AUTOSAR XML (schema 00048)
package /ComponentTypes
  swc implementation Common_Normal_Implementation: behavior=Common_Normal_InternalBehavior
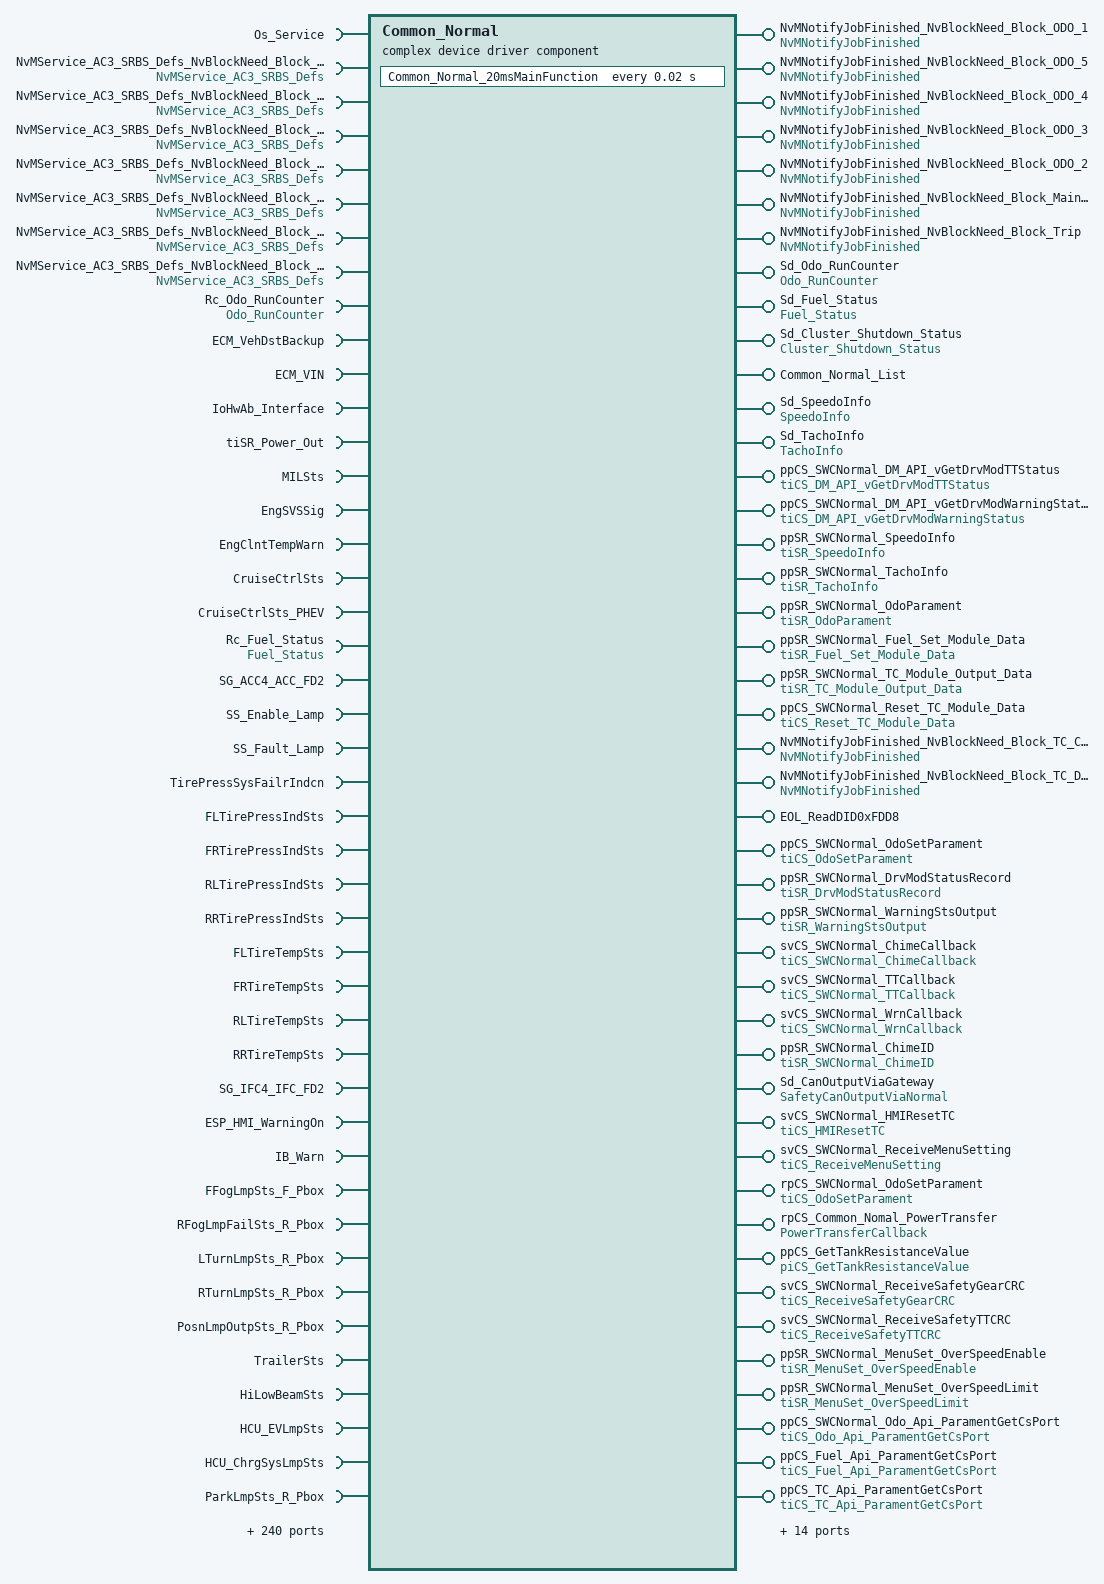
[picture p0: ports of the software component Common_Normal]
  complex device driver sw component type Common_Normal
    require port Os_Service: required-com-specs=[GetElapsedValue, GetCounterValue], required-interface=Os_Service
    require port NvMService_AC3_SRBS_Defs_NvBlockNeed_Block_ODO_1: required-com-specs=[WriteBlock, SetRamBlockStatus, RestoreBlockDefaults, ReadBlock, InvalidateNvBlock, GetErrorStatus, EraseBlock], required-interface=NvMService_AC3_SRBS_Defs
    provide port NvMNotifyJobFinished_NvBlockNeed_Block_ODO_1: server-com-spec{operation=JobFinished, queue-length=1}, provided-interface=NvMNotifyJobFinished
    provide port NvMNotifyJobFinished_NvBlockNeed_Block_ODO_5: server-com-spec{operation=JobFinished, queue-length=1}, provided-interface=NvMNotifyJobFinished
    require port NvMService_AC3_SRBS_Defs_NvBlockNeed_Block_ODO_5: required-com-specs=[WriteBlock, SetRamBlockStatus, RestoreBlockDefaults, ReadBlock, InvalidateNvBlock, GetErrorStatus, EraseBlock], required-interface=NvMService_AC3_SRBS_Defs
    provide port NvMNotifyJobFinished_NvBlockNeed_Block_ODO_4: server-com-spec{operation=JobFinished, queue-length=1}, provided-interface=NvMNotifyJobFinished
    require port NvMService_AC3_SRBS_Defs_NvBlockNeed_Block_ODO_4: required-com-specs=[WriteBlock, SetRamBlockStatus, RestoreBlockDefaults, ReadBlock, InvalidateNvBlock, GetErrorStatus, EraseBlock], required-interface=NvMService_AC3_SRBS_Defs
    provide port NvMNotifyJobFinished_NvBlockNeed_Block_ODO_3: server-com-spec{operation=JobFinished, queue-length=1}, provided-interface=NvMNotifyJobFinished
    require port NvMService_AC3_SRBS_Defs_NvBlockNeed_Block_ODO_3: required-com-specs=[WriteBlock, SetRamBlockStatus, RestoreBlockDefaults, ReadBlock, InvalidateNvBlock, GetErrorStatus, EraseBlock], required-interface=NvMService_AC3_SRBS_Defs
    provide port NvMNotifyJobFinished_NvBlockNeed_Block_ODO_2: server-com-spec{operation=JobFinished, queue-length=1}, provided-interface=NvMNotifyJobFinished
    require port NvMService_AC3_SRBS_Defs_NvBlockNeed_Block_ODO_2: required-com-specs=[WriteBlock, SetRamBlockStatus, RestoreBlockDefaults, ReadBlock, InvalidateNvBlock, GetErrorStatus, EraseBlock], required-interface=NvMService_AC3_SRBS_Defs
    provide port NvMNotifyJobFinished_NvBlockNeed_Block_MaintainOdo: server-com-spec{operation=JobFinished, queue-length=1}, provided-interface=NvMNotifyJobFinished
    require port NvMService_AC3_SRBS_Defs_NvBlockNeed_Block_MaintainOdo: required-com-specs=[WriteBlock, SetRamBlockStatus, RestoreBlockDefaults, ReadBlock, InvalidateNvBlock, GetErrorStatus, EraseBlock], required-interface=NvMService_AC3_SRBS_Defs
    provide port NvMNotifyJobFinished_NvBlockNeed_Block_Trip: server-com-spec{operation=JobFinished, queue-length=1}, provided-interface=NvMNotifyJobFinished
    require port NvMService_AC3_SRBS_Defs_NvBlockNeed_Block_Trip: required-com-specs=[WriteBlock, SetRamBlockStatus, RestoreBlockDefaults, ReadBlock, InvalidateNvBlock, GetErrorStatus, EraseBlock], required-interface=NvMService_AC3_SRBS_Defs
    provide port Sd_Odo_RunCounter: nonqueued-sender-com-spec{data-element=RunCounter, init-value=0}, provided-interface=Odo_RunCounter
    10 x require port:
      Rc_Odo_RunCounter: nonqueued-receiver-com-spec{data-element=RunCounter, filter=data-filter-type=ALWAYS, init-value=0}, required-interface=Odo_RunCounter
      ECM_VehDstBackup: nonqueued-receiver-com-spec{data-element=ECM_VehDstBackup, alive-timeout=10, enable-update=true, filter=data-filter-type=ALWAYS, handle-never-received=true, init-value=0}, required-interface=ECM_VehDstBackup
      ECM_VIN: nonqueued-receiver-com-spec{data-element=ECM19_0x3B5, alive-timeout=1.2, enable-update=true, filter=data-filter-type=ALWAYS, handle-never-received=true, init-value=8 x 0}, required-interface=ECM_VIN
      IoHwAb_Interface: required-com-specs=[SetHsLsOutput, SetPeriodAndDuty, SetDuty, SetPin, GetPin, GetVoltage], required-interface=IoHwAb_Interface
      tiSR_Power_Out: nonqueued-receiver-com-spec{data-element=SystemStateOut, alive-timeout=1, filter=data-filter-type=ALWAYS, handle-never-received=true, init-value=constant-reference=PowerOutInit}, required-interface=tiSR_Power_Out
      MILSts: nonqueued-receiver-com-spec{data-element=MILSts, alive-timeout=0.2, enable-update=true, filter=data-filter-type=ALWAYS, handle-never-received=true, init-value=0}, required-interface=MILSts
      EngSVSSig: nonqueued-receiver-com-spec{data-element=EngSVSSig, alive-timeout=0.2, enable-update=true, filter=data-filter-type=ALWAYS, handle-never-received=true, init-value=0}, required-interface=EngSVSSig
      EngClntTempWarn: nonqueued-receiver-com-spec{data-element=EngClntTempWarn, alive-timeout=1, enable-update=true, filter=data-filter-type=ALWAYS, handle-never-received=true, init-value=0}, required-interface=EngClntTempWarn
      CruiseCtrlSts: nonqueued-receiver-com-spec{data-element=CruiseCtrlSts, alive-timeout=0.2, enable-update=true, filter=data-filter-type=ALWAYS, handle-never-received=true, init-value=0}, required-interface=CruiseCtrlSts
      CruiseCtrlSts_PHEV: nonqueued-receiver-com-spec{data-element=CruiseCtrlSts_PHEV, alive-timeout=0.2, enable-update=true, filter=data-filter-type=ALWAYS, handle-never-received=true, init-value=0}, required-interface=CruiseCtrlSts_PHEV
    provide port Sd_Fuel_Status: nonqueued-sender-com-spec{data-element=Fuel_Status, init-value=0}, provided-interface=Fuel_Status
    38 x require port:
      Rc_Fuel_Status: nonqueued-receiver-com-spec{data-element=Fuel_Status, alive-timeout=1, enable-update=true, filter=data-filter-type=ALWAYS, handle-never-received=true, init-value=0}, required-interface=Fuel_Status
      SG_ACC4_ACC_FD2: nonqueued-receiver-com-spec{data-element=SG_ACC4_ACC_FD2, uses-end-to-end-protection=true, alive-timeout=1, enable-update=true, handle-never-received=true, init-value=fields=[ACC_FctSts:0, ACC_InterSysInfoDisp:0, ACC_ModDisp:0, ACC_ObjDetecte:0, ACC_SpdSetValue:0, ACC_TakeOverReq:0, ACC_TgtObjBarDisp:0, ACC_TimeGapSet:0, Checksum_ACC4:0, ISL_InterSysInfoDisp:0, RollingCounter_ACC4:0, TJA_ACC_SelSts:0, TJA_ICA_InterSysInfoDisp:0, TJA_ICA_ModDisp:0, CruCha_ModDisp:0, CruChar_InterSysInfoDisp:0, Longctrl_HazActv:0, dummy_ACC_FD2_8:0, dummy_ACC_FD2_9:0, dummy_ACC_FD2_10:0]}, required-interface=SG_ACC4_ACC_FD2
      SS_Enable_Lamp: nonqueued-receiver-com-spec{data-element=SS_Enable_Lamp, alive-timeout=1, enable-update=true, filter=data-filter-type=ALWAYS, handle-never-received=true, init-value=0}, required-interface=SS_Enable_Lamp
      SS_Fault_Lamp: nonqueued-receiver-com-spec{data-element=SS_Fault_Lamp, alive-timeout=1, enable-update=true, filter=data-filter-type=ALWAYS, handle-never-received=true, init-value=0}, required-interface=SS_Fault_Lamp
      TirePressSysFailrIndcn: nonqueued-receiver-com-spec{data-element=TirePressSysFailrIndcn, alive-timeout=5, enable-update=true, filter=data-filter-type=ALWAYS, handle-never-received=true, init-value=0}, required-interface=TirePressSysFailrIndcn
      FLTirePressIndSts: nonqueued-receiver-com-spec{data-element=FLTirePressIndSts, alive-timeout=5, enable-update=true, filter=data-filter-type=ALWAYS, handle-never-received=true, init-value=0}, required-interface=FLTirePressIndSts
      FRTirePressIndSts: nonqueued-receiver-com-spec{data-element=FRTirePressIndSts, alive-timeout=5, enable-update=true, filter=data-filter-type=ALWAYS, handle-never-received=true, init-value=0}, required-interface=FRTirePressIndSts
      RLTirePressIndSts: nonqueued-receiver-com-spec{data-element=RLTirePressIndSts, alive-timeout=5, enable-update=true, filter=data-filter-type=ALWAYS, handle-never-received=true, init-value=0}, required-interface=RLTirePressIndSts
      RRTirePressIndSts: nonqueued-receiver-com-spec{data-element=RRTirePressIndSts, alive-timeout=5, enable-update=true, filter=data-filter-type=ALWAYS, handle-never-received=true, init-value=0}, required-interface=RRTirePressIndSts
      FLTireTempSts: nonqueued-receiver-com-spec{data-element=FLTireTempSts, alive-timeout=5, enable-update=true, filter=data-filter-type=ALWAYS, handle-never-received=true, init-value=0}, required-interface=FLTireTempSts
      FRTireTempSts: nonqueued-receiver-com-spec{data-element=FRTireTempSts, alive-timeout=5, enable-update=true, filter=data-filter-type=ALWAYS, handle-never-received=true, init-value=0}, required-interface=FRTireTempSts
      RLTireTempSts: nonqueued-receiver-com-spec{data-element=RLTireTempSts, alive-timeout=5, enable-update=true, filter=data-filter-type=ALWAYS, handle-never-received=true, init-value=0}, required-interface=RLTireTempSts
      RRTireTempSts: nonqueued-receiver-com-spec{data-element=RRTireTempSts, alive-timeout=5, enable-update=true, filter=data-filter-type=ALWAYS, handle-never-received=true, init-value=0}, required-interface=RRTireTempSts
      SG_IFC4_IFC_FD2: nonqueued-receiver-com-spec{data-element=SG_IFC4_IFC_FD2, uses-end-to-end-protection=true, alive-timeout=0.5, enable-update=true, handle-never-received=true, init-value=fields=[CameraBlockageSts:0, Checksum_IFC4:0, ELKMainState:0, IFC_Handsoffwarn:0, IFCCalibrationSts:0, LaneAvailability:0, LDW_LKAWarn:0, LSSErrSts:0, LSSFuncSts:0, LSSIntervention:0, RollingCounter_IFC4:0, TJA_FollowSts:0, AESintervention:0, ESSintervention:0, dummy_IFC_FD2_13:0, dummy_IFC_FD2_14:0, dummy_IFC_FD2_15:0, ELKActSts:0, IntelligentEvaActSts:0, LCKStsIndcr:0]}, required-interface=SG_IFC4_IFC_FD2
      ESP_HMI_WarningOn: nonqueued-receiver-com-spec{data-element=ESP_HMI_WarningOn, alive-timeout=0.1, enable-update=true, filter=data-filter-type=ALWAYS, handle-never-received=true, init-value=0}, required-interface=ESP_HMI_WarningOn
      IB_Warn: nonqueued-receiver-com-spec{data-element=IB_Warn, alive-timeout=0.2, enable-update=true, filter=data-filter-type=ALWAYS, handle-never-received=true, init-value=0}, required-interface=IB_Warn
      FFogLmpSts_F_Pbox: nonqueued-receiver-com-spec{data-element=FFogLmpSts_F_Pbox, alive-timeout=0.5, enable-update=true, filter=data-filter-type=ALWAYS, handle-never-received=true, init-value=0}, required-interface=FFogLmpSts_F_Pbox
      RFogLmpFailSts_R_Pbox: nonqueued-receiver-com-spec{data-element=RFogLmpFailSts_R_Pbox, alive-timeout=0.5, enable-update=true, filter=data-filter-type=ALWAYS, handle-never-received=true, init-value=0}, required-interface=RFogLmpFailSts_R_Pbox
      LTurnLmpSts_R_Pbox: nonqueued-receiver-com-spec{data-element=LTurnLmpSts_R_Pbox, alive-timeout=0.5, enable-update=true, filter=data-filter-type=ALWAYS, handle-never-received=true, init-value=0}, required-interface=LTurnLmpSts_R_Pbox
      RTurnLmpSts_R_Pbox: nonqueued-receiver-com-spec{data-element=RTurnLmpSts_R_Pbox, alive-timeout=0.5, enable-update=true, filter=data-filter-type=ALWAYS, handle-never-received=true, init-value=0}, required-interface=RTurnLmpSts_R_Pbox
      PosnLmpOutpSts_R_Pbox: nonqueued-receiver-com-spec{data-element=PosnLmpOutpSts_R_Pbox, alive-timeout=0.5, enable-update=true, filter=data-filter-type=ALWAYS, handle-never-received=true, init-value=0}, required-interface=PosnLmpOutpSts_R_Pbox
      TrailerSts: nonqueued-receiver-com-spec{data-element=TrailerSts, alive-timeout=0.5, enable-update=true, filter=data-filter-type=ALWAYS, handle-never-received=true, init-value=0}, required-interface=TrailerSts
      HiLowBeamSts: nonqueued-receiver-com-spec{data-element=HiLowBeamSts, alive-timeout=0.5, enable-update=true, filter=data-filter-type=ALWAYS, handle-never-received=true, init-value=0}, required-interface=HiLowBeamSts
      HCU_EVLmpSts: nonqueued-receiver-com-spec{data-element=HCU_EVLmpSts, alive-timeout=0.2, enable-update=true, filter=data-filter-type=ALWAYS, handle-never-received=true, init-value=0}, required-interface=HCU_EVLmpSts
      HCU_ChrgSysLmpSts: nonqueued-receiver-com-spec{data-element=HCU_ChrgSysLmpSts, alive-timeout=0.5, enable-update=true, filter=data-filter-type=ALWAYS, handle-never-received=true, init-value=0}, required-interface=HCU_ChrgSysLmpSts
      ParkLmpSts_R_Pbox: nonqueued-receiver-com-spec{data-element=ParkLmpSts_R_Pbox, alive-timeout=0.5, enable-update=true, filter=data-filter-type=ALWAYS, handle-never-received=true, init-value=0}, required-interface=ParkLmpSts_R_Pbox
      TgtRcprtnTrqSts: nonqueued-receiver-com-spec{data-element=TgtRcprtnTrqSts, alive-timeout=0.1, enable-update=true, filter=data-filter-type=ALWAYS, handle-never-received=true, init-value=0}, required-interface=TgtRcprtnTrqSts
      CCO_Active: nonqueued-receiver-com-spec{data-element=CCO_Active, alive-timeout=0.2, enable-update=true, filter=data-filter-type=ALWAYS, handle-never-received=true, init-value=0}, required-interface=CCO_Active
      RSDS_CTA_Actv: nonqueued-receiver-com-spec{data-element=RSDS_CTA_Actv, alive-timeout=0.2, enable-update=true, filter=data-filter-type=ALWAYS, handle-never-received=true, init-value=0}, required-interface=RSDS_CTA_Actv
      RSDS_ErrSts: nonqueued-receiver-com-spec{data-element=RSDS_ErrSts, alive-timeout=0.2, enable-update=true, filter=data-filter-type=ALWAYS, handle-never-received=true, init-value=0}, required-interface=RSDS_ErrSts
      RemoteModSts: nonqueued-receiver-com-spec{data-element=RemoteModSts, alive-timeout=1, enable-update=true, filter=data-filter-type=ALWAYS, handle-never-received=true, init-value=0}, required-interface=RemoteModSts
      KL30BRelaySts: nonqueued-receiver-com-spec{data-element=KL30BRelaySts, alive-timeout=1, enable-update=true, filter=data-filter-type=ALWAYS, handle-never-received=true, init-value=0}, required-interface=KL30BRelaySts
      BMS_SOCLowWarn: nonqueued-receiver-com-spec{data-element=BMS_SOCLowWarn, alive-timeout=10, enable-update=true, filter=data-filter-type=ALWAYS, handle-never-received=true, init-value=0}, required-interface=BMS_SOCLowWarn
      TSRSts: nonqueued-receiver-com-spec{data-element=TSRSts, alive-timeout=1, enable-update=true, filter=data-filter-type=ALWAYS, handle-never-received=true, init-value=0}, required-interface=TSRSts
      TSRSpdLimSts: nonqueued-receiver-com-spec{data-element=TSRSpdLimSts, alive-timeout=1, enable-update=true, filter=data-filter-type=ALWAYS, handle-never-received=true, init-value=0}, required-interface=TSRSpdLimSts
      TSRSpdLim: nonqueued-receiver-com-spec{data-element=TSRSpdLim, alive-timeout=1, enable-update=true, filter=data-filter-type=ALWAYS, handle-never-received=true, init-value=0}, required-interface=TSRSpdLim
      TSRSpdLimWarn: nonqueued-receiver-com-spec{data-element=TSRSpdLimWarn, alive-timeout=1, enable-update=true, filter=data-filter-type=ALWAYS, handle-never-received=true, init-value=0}, required-interface=TSRSpdLimWarn
      TSRTrfcSignVal: nonqueued-receiver-com-spec{data-element=TSRTrfcSignVal, alive-timeout=1, enable-update=true, filter=data-filter-type=ALWAYS, handle-never-received=true, init-value=0}, required-interface=TSRTrfcSignVal
    provide port Sd_Cluster_Shutdown_Status: nonqueued-sender-com-spec=Element, provided-interface=Cluster_Shutdown_Status
    require port Rc_Cluster_Shutdown_Status: nonqueued-receiver-com-spec{data-element=Element, filter=data-filter-type=ALWAYS, init-value=0}, required-interface=Cluster_Shutdown_Status
    require port VConfig_GetKindConfig: client-com-spec=Operation_VConfig_GetKindConfig, required-interface=VConfig_GetKindConfig
    require port VConfig_GetUpdateTick: client-com-spec=OperationVConfig_GetUpdateTick, required-interface=VConfig_GetUpdateTick
    provide port Common_Normal_List: provided-com-specs=[{operation=Deinit, queue-length=1}, {operation=Int, queue-length=1}], provided-interface=Common_Normal_List
    21 x require port:
      SS_Screen_tip: nonqueued-receiver-com-spec{data-element=SS_Screen_tip, alive-timeout=1, filter=data-filter-type=ALWAYS, handle-never-received=true, init-value=0}, required-interface=SS_Screen_tip
      TgtCrsVehSpd: nonqueued-receiver-com-spec{data-element=TgtCrsVehSpd, alive-timeout=0.2, filter=data-filter-type=ALWAYS, handle-never-received=true, init-value=0}, required-interface=TgtCrsVehSpd
      ECM11_EngSpd_ForIP: nonqueued-receiver-com-spec{data-element=EngSpd_ForIP, alive-timeout=1, filter=data-filter-type=ALWAYS, handle-never-received=true, init-value=0}, required-interface=EngSpd_ForIP
      ECM1_EngSpdVldty: nonqueued-receiver-com-spec{data-element=EngSpdVldty, alive-timeout=0.1, filter=data-filter-type=ALWAYS, handle-never-received=true, init-value=0}, required-interface=EngSpdVldty
      TranPMode_Sts: nonqueued-receiver-com-spec{data-element=TranPMode_Sts, alive-timeout=1, filter=data-filter-type=ALWAYS, handle-never-received=true, init-value=0}, required-interface=TranPMode_Sts
      Stat_PwrSv_Lvl: nonqueued-receiver-com-spec{data-element=Stat_PwrSv_Lvl, alive-timeout=1, filter=data-filter-type=ALWAYS, handle-never-received=true, init-value=0}, required-interface=Stat_PwrSv_Lvl
      Dyn_PwrSv_Lvl: nonqueued-receiver-com-spec{data-element=Dyn_PwrSv_Lvl, alive-timeout=1, filter=data-filter-type=ALWAYS, handle-never-received=true, init-value=0}, required-interface=Dyn_PwrSv_Lvl
      LvPwrSysErr: nonqueued-receiver-com-spec{data-element=LvPwrSysErr, alive-timeout=1, filter=data-filter-type=ALWAYS, handle-never-received=true, init-value=0}, required-interface=LvPwrSysErr
      DrvDoorSts: nonqueued-receiver-com-spec{data-element=DrvDoorSts, alive-timeout=0.5, filter=data-filter-type=ALWAYS, handle-never-received=true, init-value=0}, required-interface=DrvDoorSts
      PassengerDoorSts: nonqueued-receiver-com-spec{data-element=PassengerDoorSts, alive-timeout=0.5, filter=data-filter-type=ALWAYS, handle-never-received=true, init-value=0}, required-interface=PassengerDoorSts
      LRDoorSts: nonqueued-receiver-com-spec{data-element=LRDoorSts, alive-timeout=0.5, filter=data-filter-type=ALWAYS, handle-never-received=true, init-value=0}, required-interface=LRDoorSts
      RRDoorSts: nonqueued-receiver-com-spec{data-element=RRDoorSts, alive-timeout=0.5, filter=data-filter-type=ALWAYS, handle-never-received=true, init-value=0}, required-interface=RRDoorSts
      TrunkSts: nonqueued-receiver-com-spec{data-element=TrunkSts, alive-timeout=0.5, filter=data-filter-type=ALWAYS, handle-never-received=true, init-value=0}, required-interface=TrunkSts
      HoodSts_F_Pbox: nonqueued-receiver-com-spec{data-element=HoodSts_F_Pbox, alive-timeout=0.5, filter=data-filter-type=ALWAYS, handle-never-received=true, init-value=0}, required-interface=HoodSts_F_Pbox
      SysPowerMod: nonqueued-receiver-com-spec{data-element=SysPowerMod, alive-timeout=0.5, filter=data-filter-type=ALWAYS, handle-never-received=true, init-value=0}, required-interface=SysPowerMod
      AutoLmpSwtSts: nonqueued-receiver-com-spec{data-element=AutoLmpSwtSts, alive-timeout=0.2, filter=data-filter-type=ALWAYS, handle-never-received=true, init-value=0}, required-interface=AutoLmpSwtSts
      LBrkLmpFailSts: nonqueued-receiver-com-spec{data-element=LBrkLmpFailSts, alive-timeout=0.5, filter=data-filter-type=ALWAYS, handle-never-received=true, init-value=0}, required-interface=LBrkLmpFailSts
      HiPosnBrkLmpFailSts: nonqueued-receiver-com-spec{data-element=HiPosnBrkLmpFailSts, alive-timeout=0.5, filter=data-filter-type=ALWAYS, handle-never-received=true, init-value=0}, required-interface=HiPosnBrkLmpFailSts
      RBrkLmpFailSts: nonqueued-receiver-com-spec{data-element=RBrkLmpFailSts, alive-timeout=0.5, filter=data-filter-type=ALWAYS, handle-never-received=true, init-value=0}, required-interface=RBrkLmpFailSts
      LicPlateLmpFailSts: nonqueued-receiver-com-spec{data-element=LicPlateLmpFailSts, alive-timeout=0.5, filter=data-filter-type=ALWAYS, handle-never-received=true, init-value=0}, required-interface=LicPlateLmpFailSts
      RvsLmpFailSts: nonqueued-receiver-com-spec{data-element=RvsLmpFailSts, alive-timeout=0.5, filter=data-filter-type=ALWAYS, handle-never-received=true, init-value=0}, required-interface=RvsLmpFailSts
    provide port Sd_SpeedoInfo: provided-interface=SpeedoInfo
      provided-com-specs:
        data-element=OverSpdWrnFlg, init-value=0
        data-element=IndicateSpeed, init-value=0
        data-element=RealSpeed, init-value=0
        data-element=VehRunSts, init-value=0
    provide port Sd_TachoInfo: provided-com-specs=[{data-element=EngSpd, init-value=0}, {data-element=EngRunSts, init-value=0}], provided-interface=TachoInfo
    88 x require port:
      Rc_TachoInfo: required-interface=TachoInfo
        required-com-specs:
          data-element=EngSpd, filter=data-filter-type=ALWAYS, init-value=0
          data-element=EngRunSts, filter=data-filter-type=ALWAYS, init-value=0
      Rc_SpeedoInfo: required-interface=SpeedoInfo
        required-com-specs:
          data-element=OverSpdWrnFlg, filter=data-filter-type=ALWAYS, init-value=0
          data-element=IndicateSpeed, filter=data-filter-type=ALWAYS, init-value=0
          data-element=RealSpeed, filter=data-filter-type=ALWAYS, init-value=0
          data-element=VehRunSts, filter=data-filter-type=ALWAYS, init-value=0
      DCT3_TgtEngSpdIP: nonqueued-receiver-com-spec{data-element=TgtEngSpdIP, alive-timeout=0.1, enable-update=true, filter=data-filter-type=ALWAYS, handle-never-received=true, init-value=0}, required-interface=TgtEngSpdIP
      DCT3_TgtEngSpdIPValid: nonqueued-receiver-com-spec{data-element=TgtEngSpdIPValid, alive-timeout=0.1, enable-update=true, filter=data-filter-type=ALWAYS, handle-never-received=true, init-value=0}, required-interface=TgtEngSpdIPValid
      EngSpd_ForIP: nonqueued-receiver-com-spec{data-element=EngSpd_ForIP, alive-timeout=1, filter=data-filter-type=ALWAYS, handle-never-received=true, init-value=0}, required-interface=EngSpd_ForIP
      EngSpdVldty: nonqueued-receiver-com-spec{data-element=EngSpdVldty, alive-timeout=0.1, filter=data-filter-type=ALWAYS, handle-never-received=true, init-value=0}, required-interface=EngSpdVldty
      LRPosnLmpFailSts: nonqueued-receiver-com-spec{data-element=LRPosnLmpFailSts, alive-timeout=0.5, filter=data-filter-type=ALWAYS, handle-never-received=true, init-value=0}, required-interface=LRPosnLmpFailSts
      RRPosnLmpFailSts: nonqueued-receiver-com-spec{data-element=RRPosnLmpFailSts, alive-timeout=0.5, filter=data-filter-type=ALWAYS, handle-never-received=true, init-value=0}, required-interface=RRPosnLmpFailSts
      RLSFailSts: nonqueued-receiver-com-spec{data-element=RLSFailSts, alive-timeout=0.5, filter=data-filter-type=ALWAYS, handle-never-received=true, init-value=0}, required-interface=RLSFailSts
      DrowsyDrvDetWarn: nonqueued-receiver-com-spec{data-element=DrowsyDrvDetWarn, alive-timeout=0.5, filter=data-filter-type=ALWAYS, handle-never-received=true, init-value=0}, required-interface=DrowsyDrvDetWarn
      WarnKeyInCarWhenExit: nonqueued-receiver-com-spec{data-element=WarnKeyInCarWhenExit, alive-timeout=2, filter=data-filter-type=ALWAYS, handle-never-received=true, init-value=0}, required-interface=WarnKeyInCarWhenExit
      WarnVldKeyNotFound: nonqueued-receiver-com-spec{data-element=WarnVldKeyNotFound, alive-timeout=2, filter=data-filter-type=ALWAYS, handle-never-received=true, init-value=0}, required-interface=WarnVldKeyNotFound
      WarnEngStrtNotMeet: nonqueued-receiver-com-spec{data-element=WarnEngStrtNotMeet, alive-timeout=2, filter=data-filter-type=ALWAYS, handle-never-received=true, init-value=0}, required-interface=WarnEngStrtNotMeet
      PowerRlyFault: nonqueued-receiver-com-spec{data-element=PowerRlyFault, alive-timeout=2, filter=data-filter-type=ALWAYS, handle-never-received=true, init-value=0}, required-interface=PowerRlyFault
      WarnPowerNotInOffPosn: nonqueued-receiver-com-spec{data-element=WarnPowerNotInOffPosn, alive-timeout=2, filter=data-filter-type=ALWAYS, handle-never-received=true, init-value=0}, required-interface=WarnPowerNotInOffPosn
      RotSteerWheel: nonqueued-receiver-com-spec{data-element=RotSteerWheel, alive-timeout=2, filter=data-filter-type=ALWAYS, handle-never-received=true, init-value=0}, required-interface=RotSteerWheel
      DiagLmpReq: nonqueued-receiver-com-spec{data-element=DiagLmpReq, alive-timeout=0.2, filter=data-filter-type=ALWAYS, handle-never-received=true, init-value=0}, required-interface=DiagLmpReq
      CouplingThermWarning: nonqueued-receiver-com-spec{data-element=CouplingThermWarning, alive-timeout=0.2, filter=data-filter-type=ALWAYS, handle-never-received=true, init-value=0}, required-interface=CouplingThermWarning
      CCO_Warn: nonqueued-receiver-com-spec{data-element=CCO_Warn, alive-timeout=0.2, filter=data-filter-type=ALWAYS, handle-never-received=true, init-value=0}, required-interface=CCO_Warn
      HCU_ChrgSysErr_3: nonqueued-receiver-com-spec{data-element=HCU_ChrgSysErr_3, alive-timeout=0.5, filter=data-filter-type=ALWAYS, handle-never-received=true, init-value=0}, required-interface=HCU_ChrgSysErr_3
      HCU_ChrgSysErr_4: nonqueued-receiver-com-spec{data-element=HCU_ChrgSysErr_4, alive-timeout=0.5, filter=data-filter-type=ALWAYS, handle-never-received=true, init-value=0}, required-interface=HCU_ChrgSysErr_4
      HCU_ChrgSysErr_1: nonqueued-receiver-com-spec{data-element=HCU_ChrgSysErr_1, alive-timeout=0.5, filter=data-filter-type=ALWAYS, handle-never-received=true, init-value=0}, required-interface=HCU_ChrgSysErr_1
      HCU_ChrgSysErr_2: nonqueued-receiver-com-spec{data-element=HCU_ChrgSysErr_2, alive-timeout=0.5, filter=data-filter-type=ALWAYS, handle-never-received=true, init-value=0}, required-interface=HCU_ChrgSysErr_2
      HCU_ChrgSysErr_{5..8}: nonqueued-receiver-com-spec{data-element=HCU_ChrgSysErr_{5..8}, alive-timeout=0.5, filter=data-filter-type=ALWAYS, handle-never-received=true, init-value=0}, required-interface=HCU_ChrgSysErr_{5..8}
      VSG_Sts: nonqueued-receiver-com-spec{data-element=VSG_Sts, alive-timeout=1, filter=data-filter-type=ALWAYS, handle-never-received=true, init-value=0}, required-interface=VSG_Sts
      HCU_BattLowTemWarn: nonqueued-receiver-com-spec{data-element=HCU_BattLowTemWarn, alive-timeout=0.5, filter=data-filter-type=ALWAYS, handle-never-received=true, init-value=0}, required-interface=HCU_BattLowTemWarn
      HCU_BattLowHeatSts: nonqueued-receiver-com-spec{data-element=HCU_BattLowHeatSts, alive-timeout=0.5, filter=data-filter-type=ALWAYS, handle-never-received=true, init-value=0}, required-interface=HCU_BattLowHeatSts
      HCU_ACLineDisconnect: nonqueued-receiver-com-spec{data-element=HCU_ACLineDisconnect, alive-timeout=2, filter=data-filter-type=ALWAYS, handle-never-received=true, init-value=0}, required-interface=HCU_ACLineDisconnect
      HCU_ChargSts: nonqueued-receiver-com-spec{data-element=HCU_ChargSts, alive-timeout=2, filter=data-filter-type=ALWAYS, handle-never-received=true, init-value=0}, required-interface=HCU_ChargSts
      HCU_WorkshopMode: nonqueued-receiver-com-spec{data-element=HCU_WorkshopMode, alive-timeout=2, filter=data-filter-type=ALWAYS, handle-never-received=true, init-value=0}, required-interface=HCU_WorkshopMode
      HCU_IntelBattTempMagSts: nonqueued-receiver-com-spec{data-element=HCU_IntelBattTempMagSts, alive-timeout=2, filter=data-filter-type=ALWAYS, handle-never-received=true, init-value=0}, required-interface=HCU_IntelBattTempMagSts
      HCU_EgyUsed: nonqueued-receiver-com-spec{data-element=HCU_EgyUsed, alive-timeout=10, filter=data-filter-type=ALWAYS, handle-never-received=true, init-value=0}, required-interface=HCU_EgyUsed
      HCU_RecupPwr: nonqueued-receiver-com-spec{data-element=HCU_RecupPwr, alive-timeout=10, filter=data-filter-type=ALWAYS, handle-never-received=true, init-value=0}, required-interface=HCU_RecupPwr
      HCU_EVContnsDistanceVld: nonqueued-receiver-com-spec{data-element=HCU_EVContnsDistanceVld, alive-timeout=10, filter=data-filter-type=ALWAYS, handle-never-received=true, init-value=0}, required-interface=HCU_EVContnsDistanceVld
      HCU_EVContnsDistance: nonqueued-receiver-com-spec{data-element=HCU_EVContnsDistance, alive-timeout=10, filter=data-filter-type=ALWAYS, handle-never-received=true, init-value=0}, required-interface=HCU_EVContnsDistance
      BMS_BattHeatRunaway: nonqueued-receiver-com-spec{data-element=BMS_BattHeatRunaway, alive-timeout=1, filter=data-filter-type=ALWAYS, handle-never-received=true, init-value=0}, required-interface=BMS_BattHeatRunaway
      BMS_BattSOC: nonqueued-receiver-com-spec{data-element=BMS_BattSOC, alive-timeout=1, filter=data-filter-type=ALWAYS, handle-never-received=true, init-value=0}, required-interface=BMS_BattSOC
      OBC_ConnectSts: nonqueued-receiver-com-spec{data-element=OBC_ConnectSts, alive-timeout=2, filter=data-filter-type=ALWAYS, handle-never-received=true, init-value=0}, required-interface=OBC_ConnectSts
      VSG_HUTSoundResp: nonqueued-receiver-com-spec{data-element=VSG_HUTSoundResp, alive-timeout=1, filter=data-filter-type=ALWAYS, handle-never-received=true, init-value=0}, required-interface=VSG_HUTSoundResp
      HCU_DrvMod: nonqueued-receiver-com-spec{data-element=HCU_DrvMod, alive-timeout=0.2, filter=data-filter-type=ALWAYS, handle-never-received=true, init-value=0}, required-interface=HCU_DrvMod
      HCUImmoAuthRes: nonqueued-receiver-com-spec{data-element=HCUImmoAuthRes, alive-timeout=0.2, filter=data-filter-type=ALWAYS, handle-never-received=true, init-value=0}, required-interface=HCUImmoAuthRes
      HCU_ECODrvHabit_Indcn: nonqueued-receiver-com-spec{data-element=HCU_ECODrvHabit_Indcn, alive-timeout=0.2, filter=data-filter-type=ALWAYS, handle-never-received=true, init-value=0}, required-interface=HCU_ECODrvHabit_Indcn
      HCU_TotDrvReqPower: nonqueued-receiver-com-spec{data-element=HCU_TotDrvReqPower, alive-timeout=0.2, filter=data-filter-type=ALWAYS, handle-never-received=true, init-value=0}, required-interface=HCU_TotDrvReqPower
      HCU_AvailPower_TM: nonqueued-receiver-com-spec{data-element=HCU_AvailPower_TM, alive-timeout=0.2, filter=data-filter-type=ALWAYS, handle-never-received=true, init-value=0}, required-interface=HCU_AvailPower_TM
      BMS_ChrgDurationTime: nonqueued-receiver-com-spec{data-element=BMS_ChrgDurationTime, alive-timeout=10, filter=data-filter-type=ALWAYS, handle-never-received=true, init-value=0}, required-interface=BMS_ChrgDurationTime
      AccelPedlPosnDiagc: nonqueued-receiver-com-spec{data-element=AccelPedlPosnDiagc, alive-timeout=0.2, filter=data-filter-type=ALWAYS, handle-never-received=true, init-value=0}, required-interface=AccelPedlPosnDiagc
      AccelPedalPosnVldty: nonqueued-receiver-com-spec{data-element=AccelPedalPosnVldty, alive-timeout=0.2, filter=data-filter-type=ALWAYS, handle-never-received=true, init-value=0}, required-interface=AccelPedalPosnVldty
      BrkPedalSts_BCM: nonqueued-receiver-com-spec{data-element=BrkPedalSts_BCM, alive-timeout=0.5, filter=data-filter-type=ALWAYS, handle-never-received=true, init-value=0}, required-interface=BrkPedalSts_BCM
      EMS_AuthenResult: nonqueued-receiver-com-spec{data-element=EMS_AuthenResult, alive-timeout=0.1, filter=data-filter-type=ALWAYS, handle-never-received=true, init-value=0}, required-interface=EMS_AuthenResult
      FTIVFault: nonqueued-receiver-com-spec{data-element=FTIVFault, alive-timeout=1, filter=data-filter-type=ALWAYS, handle-never-received=true, init-value=0}, required-interface=FTIVFault
      HCU_RaceLaunchSts: nonqueued-receiver-com-spec{data-element=HCU_RaceLaunchSts, alive-timeout=0.1, filter=data-filter-type=ALWAYS, handle-never-received=true, init-value=0}, required-interface=HCU_RaceLaunchSts
      HCU_RaceLaunchAvail: nonqueued-receiver-com-spec{data-element=HCU_RaceLaunchAvail, alive-timeout=0.1, filter=data-filter-type=ALWAYS, handle-never-received=true, init-value=0}, required-interface=HCU_RaceLaunchAvail
      GPF_Warning: nonqueued-receiver-com-spec{data-element=GPF_Warning, alive-timeout=1, filter=data-filter-type=ALWAYS, handle-never-received=true, init-value=0}, required-interface=GPF_Warning
      LLasHdLmpDiagSig: nonqueued-receiver-com-spec{data-element=LLasHdLmpDiagSig, alive-timeout=0.5, filter=data-filter-type=ALWAYS, handle-never-received=true, init-value=0}, required-interface=LLasHdLmpDiagSig
      RLasHdLmpDiagSig: nonqueued-receiver-com-spec{data-element=RLasHdLmpDiagSig, alive-timeout=0.5, filter=data-filter-type=ALWAYS, handle-never-received=true, init-value=0}, required-interface=RLasHdLmpDiagSig
      LasHdLmpSts_F_Pbox: nonqueued-receiver-com-spec{data-element=LasHdLmpSts_F_Pbox, alive-timeout=0.5, filter=data-filter-type=ALWAYS, handle-never-received=true, init-value=0}, required-interface=LasHdLmpSts_F_Pbox
      LLowBeamFailSts: nonqueued-receiver-com-spec{data-element=LLowBeamFailSts, alive-timeout=0.5, filter=data-filter-type=ALWAYS, handle-never-received=true, init-value=0}, required-interface=LLowBeamFailSts
      RLowBeamFailSts: nonqueued-receiver-com-spec{data-element=RLowBeamFailSts, alive-timeout=0.5, filter=data-filter-type=ALWAYS, handle-never-received=true, init-value=0}, required-interface=RLowBeamFailSts
      LHiBeamFailSts: nonqueued-receiver-com-spec{data-element=LHiBeamFailSts, alive-timeout=0.5, filter=data-filter-type=ALWAYS, handle-never-received=true, init-value=0}, required-interface=LHiBeamFailSts
      RHiBeamFailSts: nonqueued-receiver-com-spec{data-element=RHiBeamFailSts, alive-timeout=0.5, filter=data-filter-type=ALWAYS, handle-never-received=true, init-value=0}, required-interface=RHiBeamFailSts
      LHeadLmpFailSts: nonqueued-receiver-com-spec{data-element=LHeadLmpFailSts, alive-timeout=0.5, filter=data-filter-type=ALWAYS, handle-never-received=true, init-value=0}, required-interface=LHeadLmpFailSts
      RHeadLmpFailSts: nonqueued-receiver-com-spec{data-element=RHeadLmpFailSts, alive-timeout=0.5, filter=data-filter-type=ALWAYS, handle-never-received=true, init-value=0}, required-interface=RHeadLmpFailSts
      EspFuncOffSts_mode: nonqueued-receiver-com-spec{data-element=EspFuncOffSts_mode, alive-timeout=0.2, filter=data-filter-type=ALWAYS, handle-never-received=true, init-value=0}, required-interface=EspFuncOffSts_mode
      FuelTankCapWarning: nonqueued-receiver-com-spec{data-element=FuelTankCapWarning, alive-timeout=1, filter=data-filter-type=ALWAYS, handle-never-received=true, init-value=0}, required-interface=FuelTankCapWarning
      RearELDLckSts: nonqueued-receiver-com-spec{data-element=RearELDLckSts, alive-timeout=0.2, filter=data-filter-type=ALWAYS, handle-never-received=true, init-value=0}, required-interface=RearELDLckSts
      WPC_FaultSts: nonqueued-receiver-com-spec{data-element=WPC_FaultSts, alive-timeout=1, filter=data-filter-type=ALWAYS, handle-never-received=true, init-value=0}, required-interface=WPC_FaultSts
      WPC_PhoneReminder: nonqueued-receiver-com-spec{data-element=WPC_PhoneReminder, alive-timeout=1, filter=data-filter-type=ALWAYS, handle-never-received=true, init-value=0}, required-interface=WPC_PhoneReminder
      CCO_TgtVel: nonqueued-receiver-com-spec{data-element=CCO_TgtVel, alive-timeout=0.2, filter=data-filter-type=ALWAYS, handle-never-received=true, init-value=0}, required-interface=CCO_TgtVel
      EWP_Err: nonqueued-receiver-com-spec{data-element=EWP_Err, alive-timeout=1, filter=data-filter-type=ALWAYS, handle-never-received=true, init-value=0}, required-interface=EWP_Err
      DistrctnLvl: nonqueued-receiver-com-spec{data-element=DistrctnLvl, alive-timeout=0.5, filter=data-filter-type=ALWAYS, handle-never-received=true, init-value=0}, required-interface=DistrctnLvl
      DrowsnsLvl: nonqueued-receiver-com-spec{data-element=DrowsnsLvl, alive-timeout=0.5, filter=data-filter-type=ALWAYS, handle-never-received=true, init-value=0}, required-interface=DrowsnsLvl
      DMSProc: nonqueued-receiver-com-spec{data-element=DMSProc, alive-timeout=0.5, filter=data-filter-type=ALWAYS, handle-never-received=true, init-value=0}, required-interface=DMSProc
      DMSProcResult: nonqueued-receiver-com-spec{data-element=DMSProcResult, alive-timeout=0.5, filter=data-filter-type=ALWAYS, handle-never-received=true, init-value=0}, required-interface=DMSProcResult
      DMSProcSts: nonqueued-receiver-com-spec{data-element=DMSProcSts, alive-timeout=0.5, filter=data-filter-type=ALWAYS, handle-never-received=true, init-value=0}, required-interface=DMSProcSts
      PressReliProgs: nonqueued-receiver-com-spec{data-element=PressReliProgs, alive-timeout=1, filter=data-filter-type=ALWAYS, handle-never-received=true, init-value=0}, required-interface=PressReliProgs
      RSDS_TrailerSts: nonqueued-receiver-com-spec{data-element=RSDS_TrailerSts, alive-timeout=0.2, filter=data-filter-type=ALWAYS, handle-never-received=true, init-value=0}, required-interface=RSDS_TrailerSts
      RSDS_BrkgTrig: nonqueued-receiver-com-spec{data-element=RSDS_BrkgTrig, alive-timeout=0.2, filter=data-filter-type=ALWAYS, handle-never-received=true, init-value=0}, required-interface=RSDS_BrkgTrig
      RSDS_RCW_Trigger: nonqueued-receiver-com-spec{data-element=RSDS_RCW_Trigger, alive-timeout=0.2, filter=data-filter-type=ALWAYS, handle-never-received=true, init-value=0}, required-interface=RSDS_RCW_Trigger
      IPC_Send: client-com-spec=IPC_Send, required-interface=IPC_Send
      HiBeamSts_F_Pbox: nonqueued-receiver-com-spec{data-element=HiBeamSts_F_Pbox, alive-timeout=0.5, filter=data-filter-type=ALWAYS, handle-never-received=true, init-value=0}, required-interface=HiBeamSts_F_Pbox
      RFogLmpSts_R_Pbox: nonqueued-receiver-com-spec{data-element=RFogLmpSts_R_Pbox, alive-timeout=0.5, filter=data-filter-type=ALWAYS, handle-never-received=true, init-value=0}, required-interface=RFogLmpSts_R_Pbox
      HCU_AccelPedalPosn_DiagValid: nonqueued-receiver-com-spec{data-element=HCU_AccelPedalPosn_DiagValid, alive-timeout=0.1, filter=data-filter-type=ALWAYS, handle-never-received=true, init-value=0}, required-interface=HCU_AccelPedalPosn_DiagValid
      HCU_AccelPedalPosn_Diag: nonqueued-receiver-com-spec{data-element=HCU_AccelPedalPosn_Diag, alive-timeout=0.1, filter=data-filter-type=ALWAYS, handle-never-received=true, init-value=0}, required-interface=HCU_AccelPedalPosn_Diag
      RSDS_LCAResp: nonqueued-receiver-com-spec{data-element=RSDS_LCAResp, alive-timeout=0.2, filter=data-filter-type=ALWAYS, handle-never-received=true, init-value=0}, required-interface=RSDS_LCAResp
      RSDS_BliSts: nonqueued-receiver-com-spec{data-element=RSDS_BliSts, alive-timeout=0.2, filter=data-filter-type=ALWAYS, handle-never-received=true, init-value=0}, required-interface=RSDS_BliSts
    provide port ppCS_SWCNormal_DM_API_vGetDrvModTTStatus: server-com-spec{operation=Operation, queue-length=1}, provided-interface=tiCS_DM_API_vGetDrvModTTStatus
    provide port ppCS_SWCNormal_DM_API_vGetDrvModWarningStatus: server-com-spec{operation=Operation, queue-length=1}, provided-interface=tiCS_DM_API_vGetDrvModWarningStatus
    require port rpCS_SWCNormal_DM_API_vGetDrvModTTStatus: client-com-spec=Operation, required-interface=tiCS_DM_API_vGetDrvModTTStatus
    require port rpCS_SWCNormal_DM_API_vGetDrvModWarningStatus: client-com-spec=Operation, required-interface=tiCS_DM_API_vGetDrvModWarningStatus
    provide port ppSR_SWCNormal_SpeedoInfo: nonqueued-sender-com-spec{data-element=Element, init-value=fields=[OverSpdWrnFlg:0, VehRunSts:0, IndicateSpeed:0, RealSpeed:0, IndicateSpeedMile:0, RealSpeedMile:0, RealSpeedBak:0, Msg_missingSts:0, VehSpdVld:0]}, provided-interface=tiSR_SpeedoInfo
    provide port ppSR_SWCNormal_TachoInfo: nonqueued-sender-com-spec{data-element=Element, init-value=fields=[EngRunSts:0, EngSpd:0, TimeOutFlag:0, EngSpdBak:0, Msg_missingSts:0]}, provided-interface=tiSR_TachoInfo
    require port rpSR_SWCNormal_SpeedoInfo: nonqueued-receiver-com-spec{data-element=Element, filter=data-filter-type=ALWAYS, init-value=fields=[OverSpdWrnFlg:0, VehRunSts:0, IndicateSpeed:0, RealSpeed:0, IndicateSpeedMile:0, RealSpeedMile:0, RealSpeedBak:0, Msg_missingSts:0, VehSpdVld:0]}, required-interface=tiSR_SpeedoInfo
    require port rpSR_SWCNormal_TachoInfo: nonqueued-receiver-com-spec{data-element=Element, filter=data-filter-type=ALWAYS}, required-interface=tiSR_TachoInfo
    provide port ppSR_SWCNormal_OdoParament: nonqueued-sender-com-spec{data-element=Element, init-value=fields=[OdoKmValue_u32:0, OdoMileValue_u32:0, TripKmValue_u32:[0, 0, 0], TripMileValue_u32:[0, 0, 0], FsrvKmValue_s32:0, FsrvMileValue_s32:0, OdoTripIsaInvalid:0, OdoInputlValid:0, NvmBlockWriteFlag:0, ClearData_u32:0, FsrvStatus:0, RunCounter_u8:0, VinCheckFlag_u8:0, ClearFlag_u8:0]}, provided-interface=tiSR_OdoParament
    require port rpSR_SWCNormal_OdoParament: nonqueued-receiver-com-spec{data-element=Element, filter=data-filter-type=ALWAYS}, required-interface=tiSR_OdoParament
    provide port ppSR_SWCNormal_Fuel_Set_Module_Data: nonqueued-sender-com-spec{data-element=Element, init-value=fields=[Fuel_Fast_Fill_Status:0, Fuel_Fast_Fill_Status_Aux:0, 0, 0, Fuel_Level_Display_Percent:0, Fuel_Level_Display_Percent_Aux:0, Fuel_Level_Display_Segment:0, Fuel_Warning_Status_Aux:0, Fuel_Warning_Status:0, Fuel_Sensor_Error_Status_Aux:0, Fuel_Sensor_Error_Status:0, Fuel_Level_Display_Value:0, Fuel_Level_Calculate_Value_Aux:0, Fuel_Level_Calculate_Value:0, Fuel_Sensor_Raw_Value_A:0, Fuel_Level_Display_Value_Aux:0, Fuel_Sensor_Raw_Value_B:0, Fuel_Sensor_Switch:0]}, provided-interface=tiSR_Fuel_Set_Module_Data
    require port rpSR_SWCNormal_Fuel_Set_Module_Data: nonqueued-receiver-com-spec{data-element=Element, filter=data-filter-type=ALWAYS}, required-interface=tiSR_Fuel_Set_Module_Data
    provide port ppSR_SWCNormal_TC_Module_Output_Data: nonqueued-sender-com-spec{data-element=Element, init-value=fields=[u16AFE_1st_Display_Output_Data:0, u16AFE_2st_Display_Output_Data:0, u32AFE_1st_Fuel_Trip_Value:0, u32AFE_1st_Fuel_Consumption_Value:0, u32AFE_2st_Fuel_Trip_Value:0, u32AFE_2st_Fuel_Consumption_Value:0, u16IFE_Calculate_Output_Data:0, u16IFE_Display_Output_Data:0, u32IFE_Fuel_Trip_Value:0, u32IFE_Fuel_Consumption_Value:0, u32IFE_Fuel_Consumption_Can_Signal:0, u16AVS_1st_Display_Output_Data:0, u16AVS_2st_Display_Output_Data:0, u32AVS_1st_Driving_Time_Value:0, u32AVS_2st_Driving_Time_Value:0, u32AVS_1st_Fuel_Trip_Value:0, u32AVS_2st_Fuel_Trip_Value:0, u8DrivingTime_1st_Display_Hour:0, u8DrivingTime_2st_Display_Hour:0, u8DrivingTime_1st_Display_Minute:0, u8DrivingTime_2st_Display_Minute:0, u16DTE_Fuel_Tank_Volume:0, u16DTE_Fuel_Tank_Volume_Aux:0, u8DTE_Fuel_Stage_Consumption:0, u8DTE_Fuel_Stage_Consumption_Aux:0, u16DTE_Display_Output_Data:0, u16DTE_Display_Output_Data_Aux:0, u16DTE_Calculate_Output_Data:0, u16SFC_Output_Data:0, u8IFC_Poc_Update:0, u16IFC_Poc_Calculate_Value:0, u16SFC_For_Fuel_Output_Data:0, u16IFC_Poc_For_Fuel_Calculate_Rate:0, u16IFC_Poc_For_Fuel_Calculate_Rate_Aux:0]}, provided-interface=tiSR_TC_Module_Output_Data
    require port rpSR_SWCNormal_TC_Module_Output_Data: nonqueued-receiver-com-spec{data-element=Element, filter=data-filter-type=ALWAYS}, required-interface=tiSR_TC_Module_Output_Data
    provide port ppCS_SWCNormal_Reset_TC_Module_Data: server-com-spec{operation=WriteData, queue-length=1}, provided-interface=tiCS_Reset_TC_Module_Data
    require port rpCS_SWCNormal_Reset_TC_Module_Data: client-com-spec=WriteData, required-interface=tiCS_Reset_TC_Module_Data
    provide port NvMNotifyJobFinished_NvBlockNeed_Block_TC_Config_Data: server-com-spec{operation=JobFinished, queue-length=1}, provided-interface=NvMNotifyJobFinished
    require port NvMService_AC3_SRBS_Defs_NvBlockNeed_Block_TC_Config_Data: required-com-specs=[WriteBlock, SetRamBlockStatus, RestoreBlockDefaults, ReadBlock, InvalidateNvBlock, GetErrorStatus, EraseBlock], required-interface=NvMService_AC3_SRBS_Defs
    require port NvMService_AC3_SRBS_Defs_NvBlockNeed_Block_TC_Data: required-com-specs=[EraseBlock, InvalidateNvBlock, RestoreBlockDefaults, WriteBlock, ReadBlock, SetRamBlockStatus, GetErrorStatus], required-interface=NvMService_AC3_SRBS_Defs
    provide port NvMNotifyJobFinished_NvBlockNeed_Block_TC_Data: server-com-spec{operation=JobFinished, queue-length=1}, provided-interface=NvMNotifyJobFinished
    provide port EOL_ReadDID0xFDD8: server-com-spec{operation=EOL_GetReadHardInputForCluster, queue-length=1}, provided-interface=EOL_ReadDID0xFDD8
    provide port ppCS_SWCNormal_OdoSetParament: server-com-spec{operation=Operation, queue-length=1}, provided-interface=tiCS_OdoSetParament
    36 x require port:
      SG_IFC5_IFC_FD2: nonqueued-receiver-com-spec{data-element=SG_IFC5_IFC_FD2, uses-end-to-end-protection=true, alive-timeout=0.5, enable-update=true, filter=data-filter-type=ALWAYS, handle-never-received=true, init-value=fields=[Checksum_IFC5:0, IFC_LaneCurve:0, IFC_LeLane_dy:0, IFC_LeLaneTyp:0, IFC_NextLeLaneTyp:0, IFC_NextRiLaneTyp:0, IFC_RiLane_dy:0, IFC_RiLaneTyp:0, RollingCounter_IFC5:0, dummy_IFC_FD2_16:0]}, required-interface=SG_IFC5_IFC_FD2
      RSDS_IPSoundReq: nonqueued-receiver-com-spec{data-element=RSDS_IPSoundReq, alive-timeout=0.2, enable-update=true, filter=data-filter-type=ALWAYS, handle-never-received=true, init-value=0}, required-interface=RSDS_IPSoundReq
      TSRSpdLimCfdc: nonqueued-receiver-com-spec{data-element=TSRSpdLimCfdc, alive-timeout=1, enable-update=true, filter=data-filter-type=ALWAYS, handle-never-received=true, init-value=0}, required-interface=TSRSpdLimCfdc
      PASWorkCmd: nonqueued-receiver-com-spec{data-element=PASWorkCmd, alive-timeout=1, enable-update=true, filter=data-filter-type=ALWAYS, handle-never-received=true, init-value=0}, required-interface=PASWorkCmd
      APS_FLSideSnsrFailSts: nonqueued-receiver-com-spec{data-element=APS_FLSideSnsrFailSts, alive-timeout=1, enable-update=true, filter=data-filter-type=ALWAYS, handle-never-received=true, init-value=0}, required-interface=APS_FLSideSnsrFailSts
      APS_FRSideSnsrFailSts: nonqueued-receiver-com-spec{data-element=APS_FRSideSnsrFailSts, alive-timeout=1, enable-update=true, filter=data-filter-type=ALWAYS, handle-never-received=true, init-value=0}, required-interface=APS_FRSideSnsrFailSts
      APS_RLSideSnsrFailSts: nonqueued-receiver-com-spec{data-element=APS_RLSideSnsrFailSts, alive-timeout=1, enable-update=true, filter=data-filter-type=ALWAYS, handle-never-received=true, init-value=0}, required-interface=APS_RLSideSnsrFailSts
      APS_RRSideSnsrFailSts: nonqueued-receiver-com-spec{data-element=APS_RRSideSnsrFailSts, alive-timeout=1, enable-update=true, filter=data-filter-type=ALWAYS, handle-never-received=true, init-value=0}, required-interface=APS_RRSideSnsrFailSts
      SDW_SoundIndcn: nonqueued-receiver-com-spec{data-element=SDW_SoundIndcn, alive-timeout=1, enable-update=true, filter=data-filter-type=ALWAYS, handle-never-received=true, init-value=0}, required-interface=SDW_SoundIndcn
      SDWActiveSts: nonqueued-receiver-com-spec{data-element=SDWActiveSts, alive-timeout=1, enable-update=true, filter=data-filter-type=ALWAYS, handle-never-received=true, init-value=0}, required-interface=SDWActiveSts
      APS_WorkSts: nonqueued-receiver-com-spec{data-element=APS_WorkSts, alive-timeout=0.2, enable-update=true, filter=data-filter-type=ALWAYS, handle-never-received=true, init-value=0}, required-interface=APS_WorkSts
      APS_SysSoundIndcn: nonqueued-receiver-com-spec{data-element=APS_SysSoundIndcn, alive-timeout=0.2, enable-update=true, filter=data-filter-type=ALWAYS, handle-never-received=true, init-value=0}, required-interface=APS_SysSoundIndcn
      RPAS_SoundIndcn_FD: nonqueued-receiver-com-spec{data-element=RPAS_SoundIndcn_FD, alive-timeout=1, enable-update=true, filter=data-filter-type=ALWAYS, handle-never-received=true, init-value=0}, required-interface=RPAS_SoundIndcn_FD
      RPAS_WorkSts_FD: nonqueued-receiver-com-spec{data-element=RPAS_WorkSts_FD, alive-timeout=1, enable-update=true, filter=data-filter-type=ALWAYS, handle-never-received=true, init-value=0}, required-interface=RPAS_WorkSts_FD
      FLTirePress: nonqueued-receiver-com-spec{data-element=FLTirePress, alive-timeout=5, enable-update=true, filter=data-filter-type=ALWAYS, handle-never-received=true, init-value=0}, required-interface=FLTirePress
      FLTireTemp: nonqueued-receiver-com-spec{data-element=FLTireTemp, alive-timeout=5, enable-update=true, filter=data-filter-type=ALWAYS, handle-never-received=true, init-value=0}, required-interface=FLTireTemp
      RLTirePress: nonqueued-receiver-com-spec{data-element=RLTirePress, alive-timeout=5, enable-update=true, filter=data-filter-type=ALWAYS, handle-never-received=true, init-value=0}, required-interface=RLTirePress
      RLTireTemp: nonqueued-receiver-com-spec{data-element=RLTireTemp, alive-timeout=5, enable-update=true, filter=data-filter-type=ALWAYS, handle-never-received=true, init-value=0}, required-interface=RLTireTemp
      RRTirePress: nonqueued-receiver-com-spec{data-element=RRTirePress, alive-timeout=5, enable-update=true, filter=data-filter-type=ALWAYS, handle-never-received=true, init-value=0}, required-interface=RRTirePress
      RRTireTemp: nonqueued-receiver-com-spec{data-element=RRTireTemp, alive-timeout=5, enable-update=true, filter=data-filter-type=ALWAYS, handle-never-received=true, init-value=0}, required-interface=RRTireTemp
      FRTirePress: nonqueued-receiver-com-spec{data-element=FRTirePress, alive-timeout=5, enable-update=true, filter=data-filter-type=ALWAYS, handle-never-received=true, init-value=0}, required-interface=FRTirePress
      FRTireTemp: nonqueued-receiver-com-spec{data-element=FRTireTemp, alive-timeout=5, enable-update=true, filter=data-filter-type=ALWAYS, handle-never-received=true, init-value=0}, required-interface=FRTireTemp
      BMS_IntelEngIdlChrgnSts: nonqueued-receiver-com-spec{data-element=BMS_IntelEngIdlChrgnSts, alive-timeout=5, enable-update=true, filter=data-filter-type=ALWAYS, handle-never-received=true, init-value=0}, required-interface=BMS_IntelEngIdlChrgnSts
      BMS_BattKeepTempSts: nonqueued-receiver-com-spec{data-element=BMS_BattKeepTempSts, alive-timeout=5, enable-update=true, filter=data-filter-type=ALWAYS, handle-never-received=true, init-value=0}, required-interface=BMS_BattKeepTempSts
      GentrWarnLmpSts: nonqueued-receiver-com-spec{data-element=GentrWarnLmpSts, alive-timeout=1, enable-update=true, filter=data-filter-type=ALWAYS, handle-never-received=true, init-value=0}, required-interface=GentrWarnLmpSts
      TGS_LEVER: nonqueued-receiver-com-spec{data-element=TGS_LEVER, alive-timeout=0.2, enable-update=true, filter=data-filter-type=ALWAYS, handle-never-received=true, init-value=0}, required-interface=TGS_LEVER
      FPAS_SoundIndcn_FD: nonqueued-receiver-com-spec{data-element=FPAS_SoundIndcn_FD, alive-timeout=1, enable-update=true, filter=data-filter-type=ALWAYS, handle-never-received=true, init-value=0}, required-interface=FPAS_SoundIndcn_FD
      FPAS_WorkSts_FD: nonqueued-receiver-com-spec{data-element=FPAS_WorkSts_FD, alive-timeout=1, enable-update=true, filter=data-filter-type=ALWAYS, handle-never-received=true, init-value=0}, required-interface=FPAS_WorkSts_FD
      FuelConsumption: nonqueued-receiver-com-spec{data-element=FuelConsumption, alive-timeout=0.2, enable-update=true, filter=data-filter-type=ALWAYS, handle-never-received=true, init-value=0}, required-interface=FuelConsumption
      FCTA_Warn: nonqueued-receiver-com-spec{data-element=FCTA_Warn, alive-timeout=0.2, enable-update=true, filter=data-filter-type=ALWAYS, handle-never-received=true, init-value=0}, required-interface=FCTA_Warn
      FCTA_B_FuncSts: nonqueued-receiver-com-spec{data-element=FCTA_B_FuncSts, alive-timeout=0.2, enable-update=true, filter=data-filter-type=ALWAYS, handle-never-received=true, init-value=0}, required-interface=FCTA_B_FuncSts
      FCTBTrig: nonqueued-receiver-com-spec{data-element=FCTBTrig, alive-timeout=0.2, enable-update=true, filter=data-filter-type=ALWAYS, handle-never-received=true, init-value=0}, required-interface=FCTBTrig
      CR_BliSts: nonqueued-receiver-com-spec{data-element=CR_BliSts, alive-timeout=0.2, enable-update=true, filter=data-filter-type=ALWAYS, handle-never-received=true, init-value=0}, required-interface=CR_BliSts
      SG_IFC3_IFC_FD2: nonqueued-receiver-com-spec{data-element=SG_IFC3_IFC_FD2, uses-end-to-end-protection=true, alive-timeout=0.5, enable-update=true, filter=data-filter-type=ALWAYS, handle-never-received=true, init-value=fields=[AESErrSts:0, AESResp:0, AESSts:0, Checksum_IFC3:0, ELKResp:0, ESS_Pedresp:0, ESS_Vehresp:0, ESSErrSts:0, ESSSts:0, IFCHUTInterface:0, IntelligentEvaResp:0, LCKResp:0, LDW_LKA_Snvty:0, LDWResp:0, LKAResp:0, LSSResp:0, LSSWarnFormResp:0, RollingCounter_IFC3:0, dummy_IFC_FD2_8:0, dummy_IFC_FD2_9:0, dummy_IFC_FD2_10:0, dummy_IFC_FD2_11:0, dummy_IFC_FD2_12:0]}, required-interface=SG_IFC3_IFC_FD2
      SG_ACC8_ACC_FD2: nonqueued-receiver-com-spec{data-element=SG_ACC8_ACC_FD2, uses-end-to-end-protection=true, alive-timeout=1, enable-update=true, filter=data-filter-type=ALWAYS, handle-never-received=true, init-value=fields=[ADAS_DriverInloop_Monitor:0, Checksum_ACC8:0, HWA_InterSysInfoDisp:0, HWA_LaneChange:0, HWA_LaneChangeReq:0, HWA_ModDisp:0, HWA_warning:0, Longctrl_HCUTrqReq_DVR:0, RollingCounter_ACC8:0, dummy_ACC_FD2_11:0, dummy_ACC_FD2_12:0, dummy_ACC_FD2_13:0, dummy_ACC_FD2_14:0, dummy_ACC_FD2_15:0]}, required-interface=SG_ACC8_ACC_FD2
      rpSR_SWCNormal_DrvModStatusRecord: nonqueued-receiver-com-spec{data-element=Element, filter=data-filter-type=ALWAYS, init-value=fields=[TelltaleStatus:0, WarningStatus:15 x 0]}, required-interface=tiSR_DrvModStatusRecord
    provide port ppSR_SWCNormal_DrvModStatusRecord: nonqueued-sender-com-spec{data-element=Element, init-value=fields=[TelltaleStatus:0, WarningStatus:15 x 0]}, provided-interface=tiSR_DrvModStatusRecord
    provide port ppSR_SWCNormal_WarningStsOutput: nonqueued-sender-com-spec{data-element=Element, init-value=fields=WarningStatus:150 x 0}, provided-interface=tiSR_WarningStsOutput
    12 x require port:
      rpSR_SWCNormal_WarningStsOutput: nonqueued-receiver-com-spec{data-element=Element, filter=data-filter-type=ALWAYS, init-value=fields=WarningStatus:150 x 0}, required-interface=tiSR_WarningStsOutput
      SG_ACC3_ACC_FD2: nonqueued-receiver-com-spec{data-element=SG_ACC3_ACC_FD2, uses-end-to-end-protection=true, alive-timeout=1, enable-update=true, filter=data-filter-type=ALWAYS, handle-never-received=true, init-value=fields=[ALC_InterSysInfoDisp:0, ALC_Resp:0, Checksum_ACC3:0, HWA_Resp:0, HWA_SnvtySet_Resp:0, ICA_HandsOffResp:0, ISL_Resp:0, Longctrl_Decel_Req_DVR:0, Longctrl_Decel_ReqValue_DVR:0, Longctrl_DecelToStopReq_DVR:0, Longctrl_DrvOFF_Req_DVR:0, Longctrl_EngTrqReq_DVR:0, Longctrl_EngTrqReqActive_DVR:0, Longctrl_HCUTrqReqActive_DVR:0, Longctrl_ModSts_DVR:0, Longctrl_ParkShiftReq_DVR:0, Longctrl_VehHldReq_DVR:0, RollingCounter_ACC3:0, dummy_ACC_FD2_4:0, dummy_ACC_FD2_5:0, dummy_ACC_FD2_6:0, dummy_ACC_FD2_7:0]}, required-interface=SG_ACC3_ACC_FD2
      tiSR_VIN: nonqueued-receiver-com-spec{data-element=Element, filter=data-filter-type=ALWAYS}, required-interface=tiSR_VIN
      SafetyCanOutputViaNormal: required-interface=SafetyCanOutputViaNormal
        required-com-specs:
          data-element=CheckSum_IP2, filter=data-filter-type=ALWAYS, init-value=0
          data-element=RollingCounter_IP2, filter=data-filter-type=ALWAYS, init-value=0
          data-element=IP_VINcompr, filter=data-filter-type=ALWAYS, init-value=0
          data-element=IP_VehTotDistanceValid, filter=data-filter-type=ALWAYS, init-value=0
          data-element=IP_VehTotDistance, filter=data-filter-type=ALWAYS, init-value=0
          data-element=IP_PassSeatBeltWarnLmpFailSts, filter=data-filter-type=ALWAYS, init-value=0
          data-element=IP_VehSpdUnit, filter=data-filter-type=ALWAYS, init-value=0
          data-element=IP_FuelLvlInfo, filter=data-filter-type=ALWAYS, init-value=0
          data-element=IP_FuelLvlLowLmpSts, filter=data-filter-type=ALWAYS, init-value=0
          data-element=IP_Err, filter=data-filter-type=ALWAYS, init-value=0
          data-element=IP_EngOilPressLowLmpSts, filter=data-filter-type=ALWAYS, init-value=0
          data-element=IP_DrvSeatBeltWarnLmpFailSts, filter=data-filter-type=ALWAYS, init-value=0
          data-element=IP_BattChrgLmpSts, filter=data-filter-type=ALWAYS, init-value=0
          data-element=IP_ACCErr, filter=data-filter-type=ALWAYS, init-value=0
          data-element=IP_ABMWarnLmpFailrSts, filter=data-filter-type=ALWAYS, init-value=0
          data-element=dummy_HUT_IP2_0, filter=data-filter-type=ALWAYS, init-value=0
          data-element=IP_RemainDistance, filter=data-filter-type=ALWAYS, init-value=0
          data-element=IP_InstFuelConsUnit, filter=data-filter-type=ALWAYS, init-value=0
          data-element=IP_AvgFuelCons, filter=data-filter-type=ALWAYS, init-value=0
          data-element=IP_InstFuelCons, filter=data-filter-type=ALWAYS, init-value=0
          data-element=IP_CurrTheme, filter=data-filter-type=ALWAYS, init-value=0
          data-element=IP_VehSpdDisp, filter=data-filter-type=ALWAYS, init-value=0
          data-element=IP_FuelMainTankR, filter=data-filter-type=ALWAYS, init-value=0
          data-element=IP_FuelAuxTankR, filter=data-filter-type=ALWAYS, init-value=0
          data-element=IP_VelSpdDisp_Mile, filter=data-filter-type=ALWAYS, init-value=0
          data-element=IP_LagueSet, filter=data-filter-type=ALWAYS, init-value=0
          data-element=IP_EBDFailSts, filter=data-filter-type=ALWAYS
      tiSR_Rte_Read_Sd_RTC_Data: required-interface=if_RTC
        required-com-specs:
          data-element=SleepDateTime, filter=data-filter-type=ALWAYS, init-value=-1
          data-element=UtcTime, filter=data-filter-type=ALWAYS, init-value=-1
      IRTC_Service: required-com-specs=[UTC2PerpetualCalendar, GetUTCTimeInMillis], required-interface=IRTC_Service
      EngCoolantTemp: nonqueued-receiver-com-spec{data-element=EngCoolantTemp, alive-timeout=1, enable-update=true, filter=data-filter-type=ALWAYS, handle-never-received=true, init-value=0}, required-interface=EngCoolantTemp
      EngClntTempVldty: nonqueued-receiver-com-spec{data-element=EngClntTempVldty, alive-timeout=1, enable-update=true, filter=data-filter-type=ALWAYS, handle-never-received=true, init-value=0}, required-interface=EngClntTempVldty
      SocReadyFlag: nonqueued-receiver-com-spec{data-element=Element, filter=data-filter-type=ALWAYS}, required-interface=SocReadyFlag
      ppCS_SWCNormal_ChimeCallback: client-com-spec=Operation, required-interface=ppCS_SWCNormal_ChimeCallback
      ppCS_SWCNormal_TTCallback: client-com-spec=Operation, required-interface=ppCS_SWCNormal_TTCallback
      ppCS_SWCNormal_WrnCallback: client-com-spec=Operation, required-interface=ppCS_SWCNormal_WrnCallback
    4 x provide port:
      svCS_SWCNormal_ChimeCallback: server-com-spec{operation=Operation, queue-length=1}, provided-interface=tiCS_SWCNormal_ChimeCallback
      svCS_SWCNormal_TTCallback: server-com-spec{operation=Operation, queue-length=1}, provided-interface=tiCS_SWCNormal_TTCallback
      svCS_SWCNormal_WrnCallback: server-com-spec{operation=Operation, queue-length=1}, provided-interface=tiCS_SWCNormal_WrnCallback
      ppSR_SWCNormal_ChimeID: nonqueued-sender-com-spec{data-element=Element, init-value=0}, provided-interface=tiSR_SWCNormal_ChimeID
    require port rpSR_SWCNormal_ChimeID: nonqueued-receiver-com-spec{data-element=Element, filter=data-filter-type=ALWAYS, init-value=0}, required-interface=tiSR_SWCNormal_ChimeID
    5 x provide port:
      Sd_CanOutputViaGateway: provided-interface=SafetyCanOutputViaNormal
        provided-com-specs:
          data-element=RollingCounter_IP2, init-value=0
          data-element=IP_VINcompr, init-value=0
          data-element=IP_VehTotDistanceValid, init-value=0
          data-element=IP_VehTotDistance, init-value=16777215
          data-element=IP_PassSeatBeltWarnLmpFailSts, init-value=0
          data-element=IP_VehSpdUnit, init-value=0
          data-element=IP_FuelLvlInfo, init-value=255
          data-element=IP_FuelLvlLowLmpSts, init-value=0
          data-element=IP_Err, init-value=0
          data-element=IP_EngOilPressLowLmpSts, init-value=0
          data-element=IP_DrvSeatBeltWarnLmpFailSts, init-value=0
          data-element=IP_BattChrgLmpSts, init-value=0
          data-element=IP_ACCErr, init-value=0
          data-element=IP_ABMWarnLmpFailrSts, init-value=0
          data-element=dummy_HUT_IP2_0, init-value=0
          data-element=CheckSum_IP2, init-value=0
          data-element=IP_RemainDistance, init-value=4095
          data-element=IP_InstFuelConsUnit, init-value=0
          data-element=IP_AvgFuelCons, init-value=4095
          data-element=IP_InstFuelCons, init-value=16383
          data-element=IP_CurrTheme, init-value=4
          data-element=IP_VehSpdDisp, init-value=0
          data-element=IP_FuelMainTankR, init-value=10
          data-element=IP_FuelAuxTankR, init-value=10
          data-element=IP_VelSpdDisp_Mile, init-value=0
          data-element=IP_LagueSet, init-value=15
          data-element=IP_EBDFailSts, init-value=0
      svCS_SWCNormal_HMIResetTC: server-com-spec{operation=Callback, queue-length=1}, provided-interface=tiCS_HMIResetTC
      svCS_SWCNormal_ReceiveMenuSetting: server-com-spec{operation=Callback, queue-length=1}, provided-interface=tiCS_ReceiveMenuSetting
      rpCS_SWCNormal_OdoSetParament: server-com-spec{operation=Operation, queue-length=1}, provided-interface=tiCS_OdoSetParament
      rpCS_Common_Nomal_PowerTransfer: provided-com-specs=[{operation=Nomal2StandbyCallback, queue-length=1}, {operation=Standby2NomalCallback, queue-length=1}], provided-interface=PowerTransferCallback
    5 x require port:
      rcSR_SWCNormal_BswM_Warm_Reset: nonqueued-receiver-com-spec{data-element=Element, filter=data-filter-type=ALWAYS, init-value=0}, required-interface=SWC_Init_Type
      DiagnosticMonitor_Fuel_Sensor2_ShortToBAT: required-interface=DiagnosticMonitor
        required-com-specs:
          GetEventExtendedDataRecordEx
          GetEventFreezeFrameDataEx
          GetFaultDetectionCounter
          GetDTCOfEvent
          GetEventTested
          GetEventFailed
          GetEventStatus
          GetEventUdsStatus
          ResetEventDebounceStatus
          ResetEventStatus
          SetEventStatus
      DiagnosticMonitor_Fuel_Sensor2_ShortToGND: required-interface=DiagnosticMonitor
        required-com-specs:
          GetEventExtendedDataRecordEx
          GetEventFreezeFrameDataEx
          GetFaultDetectionCounter
          GetDTCOfEvent
          GetEventTested
          GetEventFailed
          GetEventStatus
          GetEventUdsStatus
          ResetEventDebounceStatus
          ResetEventStatus
          SetEventStatus
      DiagnosticMonitor_Fuel_Sensor1_ShortToBAT: required-interface=DiagnosticMonitor
        required-com-specs:
          GetEventExtendedDataRecordEx
          GetEventFreezeFrameDataEx
          GetFaultDetectionCounter
          GetDTCOfEvent
          GetEventTested
          GetEventFailed
          GetEventStatus
          GetEventUdsStatus
          ResetEventDebounceStatus
          ResetEventStatus
          SetEventStatus
      DiagnosticMonitor_Fuel_Sensor1_ShortToGND: required-interface=DiagnosticMonitor
        required-com-specs:
          GetEventExtendedDataRecordEx
          GetEventFreezeFrameDataEx
          GetFaultDetectionCounter
          GetDTCOfEvent
          GetEventTested
          GetEventFailed
          GetEventStatus
          GetEventUdsStatus
          ResetEventDebounceStatus
          ResetEventStatus
          SetEventStatus
    provide port ppCS_GetTankResistanceValue: server-com-spec{operation=Operation, queue-length=1}, provided-interface=piCS_GetTankResistanceValue
    4 x require port:
      SG_HC1: nonqueued-receiver-com-spec{data-element=SG_HC1, uses-end-to-end-protection=true, alive-timeout=1, enable-update=true, handle-never-received=true, init-value=fields=[ADBstatus:0, ALS_FailSts:0, Checksum_HC1:0, HighBeamSts_HC:0, LeftHighBeamFailSts:0, LeftLowBeamFailSts:0, RightHighBeamFailSts:0, RightLowBeamFailSts:0, RollingCounter_HC1:0, dummy_HC1_0:0, dummy_HC1_1:0, dummy_HC1_2:0, dummy_HC1_3:0, dummy_HC1_4:0, dummy_HC1_5:0]}, required-interface=SG_HC1
      SG_ACC7_ACC_FD2: nonqueued-receiver-com-spec{data-element=SG_ACC7_ACC_FD2, uses-end-to-end-protection=true, alive-timeout=1, enable-update=true, handle-never-received=true, init-value=fields=[ACC_LeTargrtDection:0, ACC_LeTgtDx:0, ACC_LeTgtDy:0, ACC_LeTgtTyp:0, ACC_RiTargrtDetn:0, ACC_RiTgtDx:0, ACC_RiTgtDy:0, ACC_RiTgtTyp:0, Checksum_ACC7:0, dummy_ACC_FD2_19:0, dummy_ACC_FD2_20:0, Request_driveoff:0, RollingCounter_ACC7:0]}, required-interface=SG_ACC7_ACC_FD2
      Cconfig_KindBuffers_400Bytes: nonqueued-receiver-com-spec{data-element=CconfigKind_400Bytes, filter=data-filter-type=ALWAYS, init-value=400 x 0}, required-interface=Cconfig_KindBuffers_400Bytes
      T_Box_SysErrSts: nonqueued-receiver-com-spec{data-element=T_Box_SysErrSts, alive-timeout=5, enable-update=true, handle-never-received=true, init-value=0}, required-interface=T_Box_SysErrSts
    provide port svCS_SWCNormal_ReceiveSafetyGearCRC: server-com-spec{operation=Callback, queue-length=1}, provided-interface=tiCS_ReceiveSafetyGearCRC
    provide port svCS_SWCNormal_ReceiveSafetyTTCRC: server-com-spec{operation=Callback, queue-length=1}, provided-interface=tiCS_ReceiveSafetyTTCRC
    require port rpSR_SWCNormal_MenuSet_OverSpeedEnable: nonqueued-receiver-com-spec{data-element=Element, filter=data-filter-type=ALWAYS, init-value=0}, required-interface=tiSR_MenuSet_OverSpeedEnable
    require port rpSR_SWCNormal_MenuSet_OverSpeedLimit: nonqueued-receiver-com-spec{data-element=Element, filter=data-filter-type=ALWAYS, init-value=0}, required-interface=tiSR_MenuSet_OverSpeedLimit
    provide port ppSR_SWCNormal_MenuSet_OverSpeedEnable: nonqueued-sender-com-spec{data-element=Element, init-value=0}, provided-interface=tiSR_MenuSet_OverSpeedEnable
    provide port ppSR_SWCNormal_MenuSet_OverSpeedLimit: nonqueued-sender-com-spec{data-element=Element, init-value=0}, provided-interface=tiSR_MenuSet_OverSpeedLimit
    provide port ppCS_SWCNormal_Odo_Api_ParamentGetCsPort: server-com-spec{operation=Operation, queue-length=1}, provided-interface=tiCS_Odo_Api_ParamentGetCsPort
    6 x require port:
      BSD_LCA_warningReqRight: nonqueued-receiver-com-spec{data-element=BSD_LCA_warningReqRight, alive-timeout=0.2, enable-update=true, handle-never-received=true, init-value=0}, required-interface=BSD_LCA_warningReqRight
      BSD_LCA_warningReqleft: nonqueued-receiver-com-spec{data-element=BSD_LCA_warningReqleft, alive-timeout=0.2, enable-update=true, handle-never-received=true, init-value=0}, required-interface=BSD_LCA_warningReqleft
      DOW_warningReqleft: nonqueued-receiver-com-spec{data-element=DOW_warningReqleft, alive-timeout=0.2, enable-update=true, handle-never-received=true, init-value=0}, required-interface=DOW_warningReqleft
      DOW_warningReqRight: nonqueued-receiver-com-spec{data-element=DOW_warningReqRight, alive-timeout=0.2, enable-update=true, handle-never-received=true, init-value=0}, required-interface=DOW_warningReqRight
      RCTA_warningReqLeft: nonqueued-receiver-com-spec{data-element=RCTA_warningReqLeft, alive-timeout=0.2, enable-update=true, handle-never-received=true, init-value=0}, required-interface=RCTA_warningReqLeft
      RCTA_warningReqRight: nonqueued-receiver-com-spec{data-element=RCTA_warningReqRight, alive-timeout=0.2, enable-update=true, handle-never-received=true, init-value=0}, required-interface=RCTA_warningReqRight
    provide port ppCS_Fuel_Api_ParamentGetCsPort: server-com-spec{operation=Operation, queue-length=1}, provided-interface=tiCS_Fuel_Api_ParamentGetCsPort
    provide port ppCS_TC_Api_ParamentGetCsPort: server-com-spec{operation=Operation, queue-length=1}, provided-interface=tiCS_TC_Api_ParamentGetCsPort
    13 x require port:
      SG_AEB2_AEB_FD2: nonqueued-receiver-com-spec{data-element=SG_AEB2_AEB_FD2, alive-timeout=0.5, enable-update=true, handle-never-received=true, init-value=fields=[AEB_JA_Resp:1, AEB_PedResp:1, AEB_VehResp:1, Checksum_AEB2:0, FCW_Snvty:0, RollingCounter_AEB2:0, dummy_AEB_FD2_8:0, dummy_AEB_FD2_9:0, dummy_AEB_FD2_10:0, dummy_AEB_FD2_11:0, dummy_AEB_FD2_12:0, dummy_AEB_FD2_13:0, dummy_AEB_FD2_14:0]}, required-interface=SG_AEB2_AEB_FD2
      SG_AEB3_AEB_FD2: nonqueued-receiver-com-spec{data-element=SG_AEB3_AEB_FD2, alive-timeout=0.5, enable-update=true, handle-never-received=true, init-value=fields=[AEB_JA_Warn:0, AEB_JABrkTrig:0, AEB_JAFuncSts:0, AEB_PedTrig:0, AEB_VehTrig:0, Checksum_AEB3:0, FCW_AEB_PedFctSts:0, FCW_AEB_VehFctSts:0, FCW_Warn:0, RollingCounter_AEB3:0, dummy_AEB_FD2_15:0, dummy_AEB_FD2_16:0, dummy_AEB_FD2_17:0, dummy_AEB_FD2_18:0, dummy_AEB_FD2_19:0, dummy_AEB_FD2_20:0, dummy_AEB_FD2_21:0]}, required-interface=SG_AEB3_AEB_FD2
      SG_EPS1_FD1: nonqueued-receiver-com-spec{data-element=SG_EPS1_FD1, uses-end-to-end-protection=true, alive-timeout=0.2, enable-update=true, handle-never-received=true, init-value=fields=[CheckSum_EPS1_0x147:0, dummy_EPS_FD1_0:0, dummy_EPS_FD1_1:0, dummy_EPS_FD1_2:0, dummy_EPS_FD1_3:0, dummy_EPS_FD1_4:0, dummy_EPS_FD1_5:0, dummy_EPS_FD1_6:0, dummy_EPS_FD1_7:0, EPS_FailSts_0x147:0, EPS_SteerMod_0x147:0, EPS_TrqSnsrSts_0x147:0, RollingCounter_EPS1_0x147:0]}, required-interface=SG_EPS1_FD1
      SG_ESP2_ESP_FD2: nonqueued-receiver-com-spec{data-element=SG_ESP2_ESP_FD2, uses-end-to-end-protection=true, alive-timeout=0.2, enable-update=true, handle-never-received=true, init-value=fields=[ABAActv_0x137:0, ABAavailable_0x137:0, ABPActv_0x137:0, ABPAvailable_0x137:0, AEBAvailable_0x137:0, AEBBAActv_0x137:0, AEBIBActv_0x137:0, AVHErrSts_0x137:0, AVHSts_0x137:0, AWBActv_0x137:0, AWBAvailable_0x137:0, BrkDskOvrheatd_0x137:0, CDDActv_0x137:0, CDDAvailable_0x137:0, CDPActv_0x137:0, CheckSum_ESP2_0x137:0, dummy_ESP_FD2_8:0, dummy_ESP_FD2_9:0, dummy_ESP_FD2_10:0, dummy_ESP_FD2_11:0, dummy_ESP_FD2_12:0, dummy_ESP_FD2_13:0, dummy_ESP_FD2_14:0, dummy_ESP_FD2_15:0, HDCCtrl_0x137:0, HDCFault_0x137:0, NoBrkForce_0x137:0, RollingCounter_ESP2_0x137:0, VehStandstill_0x137:0]}, required-interface=SG_ESP2_ESP_FD2
      SG_ABM1: nonqueued-receiver-com-spec{data-element=SG_ABM1, alive-timeout=5, enable-update=true, handle-never-received=true, init-value=fields=[AirbFailLmpCmd:0, CheckSum_ABM1:0, DrvSBR:0, DrvSBR_Visual:0, PassSBR:0, PassSBR_Visual:0, RollingCounter_ABM1:0, SecRowLSBR:0, SecRowLSBR_Visual:0, SecRowMidSBR:0, SecRowMidSBR_Visual:0, SecRowRSBR:0, SecRowRSBR_Visual:0, CrashOutputSts:0, dummy_ABM1_0:0, dummy_ABM1_1:0, dummy_ABM1_2:0, dummy_ABM1_3:0, dummy_ABM1_4:0, dummy_ABM1_5:0]}, required-interface=SG_ABM1
      SG_ABS3_ESP_FD2: nonqueued-receiver-com-spec{data-element=SG_ABS3_ESP_FD2, alive-timeout=0.2, enable-update=true, handle-never-received=true, init-value=fields=[ABSActv_0x137:0, ABSFailSts_0x137:1, CheckSum_ABS3_0x137:0, dummy_ESP_FD2_37:0, dummy_ESP_FD2_38:0, dummy_ESP_FD2_39:0, dummy_ESP_FD2_40:0, EBDActv_0x137:0, EBDFailSts_0x137:0, RollingCounter_ABS3_0x137:0, VehOdoInfo_0x137:0, VehOdoInfoSts_0x137:1, VehSpd_0x137:0, VehSpdVld_0x137:0]}, required-interface=SG_ABS3_ESP_FD2
      SG_DCT7: nonqueued-receiver-com-spec{data-element=SG_DCT7, alive-timeout=0.5, enable-update=true, handle-never-received=true, init-value=fields=[CheckSum_DCT7:0, DCT_PrsBrk_Warn:0, DCT_RaceModeSts:0, DCT_ShftNotAlwd_Warn:0, DCT_ShftRecom_M:0, DrvAutoGearDisp:0, DrvWarnMsg:0, RollingCounter_DCT7:0, DrvFaiMsg_0x235:0, DrvGearDispSts_0x235:0, DrvModDisp_0x235:0, DrvModDispSts_0x235:0, dummy_DCT7_0:0, dummy_DCT7_1:0, dummy_DCT7_2:0, dummy_DCT7_3:0, dummy_DCT7_4:0, dummy_DCT7_5:0]}, required-interface=SG_DCT7
      SG_EPB1: nonqueued-receiver-com-spec{data-element=SG_EPB1, alive-timeout=0.2, enable-update=true, handle-never-received=true, init-value=fields=[CheckSum_EPB1:0, EPBErrSts:0, EPBRedLmpSts:0, EPBSts:0, EPBTextDisp:0, PressBrakePedalPointOut:0, RollingCounter_EPB1:0, dummy_EPB1_0:0, dummy_EPB1_1:0, dummy_EPB1_2:0, dummy_EPB1_3:0, dummy_EPB1_4:0, dummy_EPB1_5:0, dummy_EPB1_6:0, dummy_EPB1_7:0]}, required-interface=SG_EPB1
      SG_EPS1: nonqueued-receiver-com-spec{data-element=SG_EPS1, alive-timeout=0.2, enable-update=true, handle-never-received=true, init-value=fields=[CheckSum_EPS1_0x168:0, dummy_EPS1_0:0, dummy_EPS1_1:0, dummy_EPS1_2:0, dummy_EPS1_3:0, dummy_EPS1_4:0, dummy_EPS1_5:0, dummy_EPS1_6:0, dummy_EPS1_7:0, EPS_FailSts_0x168:0, EPS_SteerMod_0x168:0, EPS_TrqSnsrSts_0x168:1, RollingCounter_EPS1_0x168:0]}, required-interface=SG_EPS1
      SG_ESP2: nonqueued-receiver-com-spec{data-element=SG_ESP2, alive-timeout=0.2, enable-update=true, handle-never-received=true, init-value=fields=[DrivingModDis:0, DrivingModReq_ESP:0, TAB_Available:0, TAB_Sts:0, ABAActv_0x145:0, ABAavailable_0x145:0, ABPActv_0x145:0, ABPAvailable_0x145:0, AEBAvailable_0x145:0, AEBBAActv_0x145:0, AEBIBActv_0x145:0, AVHErrSts_0x145:0, AVHSts_0x145:0, AWBActv_0x145:0, AWBAvailable_0x145:0, BrkDskOvrheatd_0x145:0, CDDActv_0x145:0, CDDAvailable_0x145:0, CDPActv_0x145:0, CheckSum_ESP2_0x145:0, dummy_ESP2_0:0, dummy_ESP2_1:0, dummy_ESP2_2:0, dummy_ESP2_3:0, dummy_ESP2_4:0, dummy_ESP2_5:0, dummy_ESP2_6:0, dummy_ESP2_7:0, HDCCtrl_0x145:0, HDCFault_0x145:0, NoBrkForce_0x145:0, RollingCounter_ESP2_0x145:0, VehStandstill_0x145:0]}, required-interface=SG_ESP2
      SG_ABS3: nonqueued-receiver-com-spec{data-element=SG_ABS3, alive-timeout=0.2, enable-update=true, handle-never-received=true, init-value=fields=[ABSActv_0x265:0, ABSFailSts_0x265:1, CheckSum_ABS3_0x265:0, dummy_ABS3_0:0, dummy_ABS3_1:0, dummy_ABS3_2:0, dummy_ABS3_3:0, EBDActv_0x265:0, EBDFailSts_0x265:0, RollingCounter_ABS3_0x265:0, VehOdoInfo_0x265:0, VehOdoInfoSts_0x265:1, VehSpd_0x265:0, VehSpdVld_0x265:0]}, required-interface=SG_ABS3
      CsmDecrypt_CsmPrimitives_AES128_Decrypt: required-com-specs=[CancelJob, Decrypt], required-interface=CsmDecrypt_CsmPrimitives_AES128_Decrypt
      CsmEncrypt_CsmPrimitives_AES128_Encrypt: required-com-specs=[CancelJob, Encrypt], required-interface=CsmEncrypt_CsmPrimitives_AES128_Encrypt
    provide port ppSR_SWCNormal_MenuSetData: nonqueued-sender-com-spec{data-element=Element, init-value=fields=[NaviLimitSpeed:0, OverSpeedEnable:0, Language:0, ClusterTheme:0, OdometerUnit:0, TemperatureUnit:0, TirePressureUnit:0, TripComputerId:0, InteractiveCarId:0, DrivingModeMemorySwitch:0, TimeUnit:0, HighwayAssistSwitch:0, LaneChangeAssistSwitch:0, Cluster_Sunrise_Sunset_Mode:0, Cluster_Auto_Mode:0, DrvgModeMemReq:0, DrvingModReq_HUT:0, DataSyncFlag:0, AtmosphereLampLinkageSwt_Sts:0, SimSoundWaveLinkageSwt_Sts:0]}, provided-interface=tiSR_MenuSetData
    5 x require port:
      Hsm_Port: client-com-spec=TrngGenerate, required-interface=Hsm_Port
      HsmKeyM: required-com-specs=[SetCmacKey, SetAes128Key, GetCmacKeyState, GetCmacKey, GetAes128Key], required-interface=HsmKeyM
      rpSR_SWCNormal_MenuSetData: nonqueued-receiver-com-spec{data-element=Element, filter=data-filter-type=ALWAYS, init-value=fields=[NaviLimitSpeed:0, OverSpeedEnable:0, Language:0, ClusterTheme:0, OdometerUnit:0, TemperatureUnit:0, TirePressureUnit:0, TripComputerId:0, InteractiveCarId:0, DrivingModeMemorySwitch:0, TimeUnit:0, HighwayAssistSwitch:0, LaneChangeAssistSwitch:0, Cluster_Sunrise_Sunset_Mode:0, Cluster_Auto_Mode:0, DrvgModeMemReq:0, DrvingModReq_HUT:0, DataSyncFlag:0, AtmosphereLampLinkageSwt_Sts:0, SimSoundWaveLinkageSwt_Sts:0]}, required-interface=tiSR_MenuSetData
      NvMAdmin_NvBlockNeed_Menu: client-com-spec=SetBlockProtection, required-interface=NvMAdministration
      NvMService_AC3_SRBS_NvBlockNeed_Menu: required-com-specs=[WriteBlock, SetRamBlockStatus, ReadBlock, InvalidateNvBlock, GetErrorStatus, EraseBlock], required-interface=NvMService_AC3_SRBS
    provide port NvMNotifyJobFinished_NvBlockNeed_Menu: server-com-spec{operation=JobFinished, queue-length=1}, provided-interface=NvMNotifyJobFinished
    require port tiSR_SWC_TT_SelfCheck: nonqueued-receiver-com-spec{data-element=Element, filter=data-filter-type=ALWAYS, init-value=1}, required-interface=tiSR_SWC_TT_SelfCheck
    provide port CsmJob_Aes128_Decrypt_Cbk_Callback: server-com-spec{operation=CallbackNotification, queue-length=1}, provided-interface=CallbackNotification
    provide port CsmJob_Aes128_Encrypt_Cbk_Callback: server-com-spec{operation=CallbackNotification, queue-length=1}, provided-interface=CallbackNotification
    require port CanFrameCounter: required-com-specs=[Can_ECM2_Counter, Can_ESP_FD2_Counter, Can_ABS3_Counter], required-interface=CanFrameCounter
    require port rpSR_SWCNormal_S2M_Information: required-interface=tiSR_S2M_Information
      required-com-specs:
        data-element=TachoValue, filter=data-filter-type=ALWAYS, init-value=0
        data-element=SpeedValue, filter=data-filter-type=ALWAYS, init-value=0
    provide port svCS_SWCNormal_SensorAorB_Status: server-com-spec{operation=Operation, queue-length=1}, provided-interface=tiSR_SensorAorB_Status
    7 x require port:
      rpCS_SWCNormal_SensorAorB_Status: client-com-spec=Operation, required-interface=tiSR_SensorAorB_Status
      SG_IFC6_IFC_FD2: nonqueued-receiver-com-spec{data-element=SG_IFC6_IFC_FD2, uses-end-to-end-protection=true, alive-timeout=0.5, enable-update=true, filter=data-filter-type=ALWAYS, handle-never-received=true, init-value=fields=[Checksum_IFC6:0, dummy_IFC_FD2_17:0, dummy_IFC_FD2_18:0, dummy_IFC_FD2_19:0, dummy_IFC_FD2_20:0, IFC_NextLeLane_dy:2496, IFC_NextRiLane_dy:2496, RollingCounter_IFC6:0]}, required-interface=SG_IFC6_IFC_FD2
      SG_HCU_PT4: nonqueued-receiver-com-spec{data-element=SG_HCU_PT4, uses-end-to-end-protection=true, alive-timeout=1, enable-update=true, filter=data-filter-type=ALWAYS, handle-never-received=true, init-value=fields=[CarWashMode_Sts:0, CarWashMode_StsDisp:0, Checksum_HCU_PT4:0, dummy_HCU_PT4_0:0, dummy_HCU_PT4_1:0, dummy_HCU_PT4_2:0, dummy_HCU_PT4_3:0, dummy_HCU_PT4_4:0, dummy_HCU_PT4_5:0, dummy_HCU_PT4_6:0, dummy_HCU_PT4_7:0, HCU_ACStsReq:2, HCU_BattPowerRedWarn:0, HCU_ConnectChrgLine_Indcn:0, HCU_EgyRecFB:0, HCU_EnerSavePowerMod:0, HCU_InhbChrgInfo:0, HCU_OilTankCoverSts:0, HCU_OPDFail:0, HCU_RefuReq:0, HCU_RemoveChrgLine_Indcn:0, HCU_Shift_P_Indcn:0, HCU_SOCLow_Indcn:0, HCU_WadeModeSetSts:0, OPDParkWarnReq:0, RollingCounter_HCU_PT4:0]}, required-interface=SG_HCU_PT4
      SG_HCU_PT7: nonqueued-receiver-com-spec{data-element=SG_HCU_PT7, uses-end-to-end-protection=true, alive-timeout=0.5, enable-update=true, filter=data-filter-type=ALWAYS, handle-never-received=true, init-value=fields=[CheckSum_HCU_PT7:0, dummy_HCU_PT7_0:0, dummy_HCU_PT7_1:0, dummy_HCU_PT7_2:0, dummy_HCU_PT7_3:0, dummy_HCU_PT7_4:0, dummy_HCU_PT7_5:0, dummy_HCU_PT7_6:0, HCU_12VSysErr_1:0, HCU_12VSysErr_2:0, HCU_12VSysErrLmpSts:0, HCU_EnrgFlowInd:0, HCU_HybSysErr_1:0, HCU_HybSysErr_2:0, HCU_HybSysErr_3:0, HCU_HybSysErr_4:0, HCU_HybSysErr_5:0, HCU_HybSysErr_6:0, HCU_HybSysErr_7:0, HCU_HybSysErrLmpSts:0, HCU_ModSwtFail:0, HCU_OPDLmpSts:0, HCU_OPDSts:0, HCU_PowerRedWarnLmpCmd:0, HCU_RdyLmpSts:0, RollingCounter_HCU_PT7:0]}, required-interface=SG_HCU_PT7
      SG_BMS4: nonqueued-receiver-com-spec{data-element=SG_BMS4, uses-end-to-end-protection=true, alive-timeout=0.1, enable-update=true, filter=data-filter-type=ALWAYS, handle-never-received=true, init-value=fields=[BMS_BattPoweErr:0, BMS_ErrCategory:0, BMS_PackCurr:0, BMS_PackVolt:178, BMS_PowerDownCmplt:0, CheckSum_BMS4:0, dummy_BMS4_0:0, dummy_BMS4_1:0, dummy_BMS4_2:0, dummy_BMS4_3:0, dummy_BMS4_4:0, RollingCounter_BMS4:0]}, required-interface=SG_BMS4
      SG_DHT_FD1: nonqueued-receiver-com-spec{data-element=SG_DHT_FD1, uses-end-to-end-protection=true, alive-timeout=0.1, enable-update=true, filter=data-filter-type=ALWAYS, handle-never-received=true, init-value=fields=[CheckSum_DHT1:0, dummy_DHT_FD1_8:0, dummy_DHT_FD1_9:0, dummy_DHT_FD1_10:0, dummy_DHT_FD1_11:0, dummy_DHT_FD1_12:0, dummy_DHT_FD1_13:0, RollingCounter_DHT1:0, TCU_ClutchHotWarning:0, TCU_ErrCategory:0]}, required-interface=SG_DHT_FD1
      SG_HCU_HP5: nonqueued-receiver-com-spec{data-element=SG_HCU_HP5, uses-end-to-end-protection=true, alive-timeout=0.5, enable-update=true, filter=data-filter-type=ALWAYS, handle-never-received=true, init-value=fields=[Checksum_HCU_HP5:0, DrvFaiMsg_0x201:0, DrvGearDisp:0, DrvGearDispSts_0x201:0, DrvModDisp_0x201:0, DrvModDispSts_0x201:0, dummy_HCU_HP5_0:0, dummy_HCU_HP5_1:0, dummy_HCU_HP5_2:0, dummy_HCU_HP5_3:0, dummy_HCU_HP5_4:0, HCU_EnrgFlowInd_DHT:0, HCU_PrsBrkWarn:0, HCU_ShftNotAlwd_Warn:0, RollingCounter_HCU_HP5:0]}, required-interface=SG_HCU_HP5
    provide port ppCS_SWCNormal_TC_EnergyInfo: server-com-spec{operation=Operation, queue-length=1}, provided-interface=tiCS_TC_EnergyInfo
    provide port ppCS_SWCNormal_TC_EnergyInfoResp: server-com-spec{operation=Operation, queue-length=1}, provided-interface=tiCS_TC_EnergyInfoResp
    12 x require port:
      FPAS_SoundIndcn: nonqueued-receiver-com-spec{data-element=FPAS_SoundIndcn, alive-timeout=1, enable-update=true, filter=data-filter-type=ALWAYS, handle-never-received=true, init-value=0}, required-interface=FPAS_SoundIndcn
      FPAS_WorkSts: nonqueued-receiver-com-spec{data-element=FPAS_WorkSts, alive-timeout=1, enable-update=true, filter=data-filter-type=ALWAYS, handle-never-received=true, init-value=0}, required-interface=FPAS_WorkSts
      RPAS_WorkSts: nonqueued-receiver-com-spec{data-element=RPAS_WorkSts, alive-timeout=1, enable-update=true, filter=data-filter-type=ALWAYS, handle-never-received=true, init-value=0}, required-interface=RPAS_WorkSts
      RPAS_SoundIndcn: nonqueued-receiver-com-spec{data-element=RPAS_SoundIndcn, alive-timeout=1, enable-update=true, filter=data-filter-type=ALWAYS, handle-never-received=true, init-value=0}, required-interface=RPAS_SoundIndcn
      LHiBeamSts: nonqueued-receiver-com-spec{data-element=LHiBeamSts, alive-timeout=2, enable-update=true, filter=data-filter-type=ALWAYS, handle-never-received=true, init-value=0}, required-interface=LHiBeamSts
      RHiBeamSts: nonqueued-receiver-com-spec{data-element=RHiBeamSts, alive-timeout=2, enable-update=true, filter=data-filter-type=ALWAYS, handle-never-received=true, init-value=0}, required-interface=RHiBeamSts
      LADBstatus: nonqueued-receiver-com-spec{data-element=LADBstatus, alive-timeout=2, enable-update=true, filter=data-filter-type=ALWAYS, handle-never-received=true, init-value=0}, required-interface=LADBstatus
      RADBstatus: nonqueued-receiver-com-spec{data-element=RADBstatus, alive-timeout=2, enable-update=true, filter=data-filter-type=ALWAYS, handle-never-received=true, init-value=0}, required-interface=RADBstatus
      AVASDTCResults: nonqueued-receiver-com-spec{data-element=AVASDTC, filter=data-filter-type=ALWAYS, init-value=fields=[ElementConstant:2, ElementConstant_1:2, ElementConstant_2:2, ElementConstant_3:2, ElementConstant_4:2, ElementConstant_5:2]}, required-interface=AVASDTCResults
      ACAmbTemp: nonqueued-receiver-com-spec{data-element=ACAmbTemp, alive-timeout=1, filter=data-filter-type=ALWAYS, handle-never-received=true, init-value=0}, required-interface=ACAmbTemp
      rpCS_SWCNormal_ComEx: required-com-specs=[SendSignal, ReceiveSignal, GetRxE2EStatus], required-interface=ComEx
      rpSR_SWCNormal_EnergyInfoId: nonqueued-receiver-com-spec{data-element=Data, filter=data-filter-type=ALWAYS, init-value=fields=[ModuleId:0, ClientId:0]}, required-interface=tiSR_EnergyInfoId
    provide port svCS_SWCNormal_ReceiveAdasStatus: server-com-spec{operation=Callback, queue-length=1}, provided-interface=tiCS_HMIResetTC
    provide port svCS_SWCNormal_ReceiveHMIPowerMode: server-com-spec{operation=Callback, queue-length=1}, provided-interface=tiCS_HMIResetTC
    require port rpSR_SWCNormal_DiagMonitorReInitFlag: nonqueued-receiver-com-spec{data-element=ChangeCounter, filter=data-filter-type=ALWAYS, init-value=0}, required-interface=piDiagMonitorReInitFlag
    provide port ppCS_SWCNormal_ReceiveMenuTheme: server-com-spec{operation=Callback, queue-length=1}, provided-interface=tiCS_ReceiveMenuSetting
    provide port ppCS_SWCNormal_OdoTimeSync: server-com-spec{operation=CallBack, queue-length=1}, provided-interface=tiCS_OdoTimeSync
    provide port ppCS_SWCNormal_TtToChime: server-com-spec{operation=Callback, queue-length=1}, provided-interface=TtToChime
    require port Vconfig_GetKindBuffers: nonqueued-receiver-com-spec{data-element=AllKinds, filter=data-filter-type=ALWAYS, init-value=600 x 0}, required-interface=Vconfig_GetKindBuffers
    provide port svCS_SWCNormal_ReceiveOffroadInfo: server-com-spec{operation=Callback, queue-length=1}, provided-interface=tiCS_ReceiveOffroadInfo
    provide port ppSR_SWCNormal_TC_NE_ChargStsOutput: nonqueued-sender-com-spec{data-element=Element, init-value=fields=ChargFaultSts:0}, provided-interface=tiSR_TC_NE_ChargStsOutput
    require port rpSR_SWCNormal_TC_NE_ChargStsOutput: nonqueued-receiver-com-spec{data-element=Element, filter=data-filter-type=ALWAYS, init-value=fields=ChargFaultSts:0}, required-interface=tiSR_TC_NE_ChargStsOutput
    behavior Common_Normal_InternalBehavior: data-type-mapping=[DataTypeMappings_DEV, DataTypeMappings_DEV]
      exclusive area ExclusiveArea_Normal
      ar-typed-per-instance-memorys:
        9 x data, all with sw-calibration-access=READ-ONLY:
          NvBlockNeed_Block_ODO_{1..5}_MirrorBlock: type=A_ODO_data_u8_16
          NvBlockNeed_Block_MaintainOdo_MirrorBlock: type=NVMBlockMaintain_Type
          NvBlockNeed_Block_Trip_MirrorBlock: type=NVMBlockTrip
          NvBlockNeed_MENU_Data_MirrorBlock: type=NVMMenuData_A20
          NvBlockNeed_Menu_MirrorBlock: type=NVMMenuData_A20
      timing event TMT_ODO_MainFunction: start-on-event=Common_Normal_20msMainFunction, period=0.02
      init event ODO_InitEvent: start-on-event=Common_Normal_Init
      7 x operation invoked event:
        OIT_NvMNotifyJobFinished_NvBlockNeed_Block_ODO_1_JobFinished_NvMNotifyJobFinished_NvBlockNeed_Block_ODO_1_JobFinished: start-on-event=NvMNotifyJobFinished_NvBlockNeed_Block_ODO_1_JobFinished, operation=NvMNotifyJobFinished_NvBlockNeed_Block_ODO_1.JobFinished
        OIT_NvMNotifyJobFinished_NvBlockNeed_Block_ODO_5_JobFinished_NvMNotifyJobFinished_NvBlockNeed_Block_ODO_5_JobFinished: start-on-event=NvMNotifyJobFinished_NvBlockNeed_Block_ODO_5_JobFinished, operation=NvMNotifyJobFinished_NvBlockNeed_Block_ODO_5.JobFinished
        OIT_NvMNotifyJobFinished_NvBlockNeed_Block_ODO_4_JobFinished_NvMNotifyJobFinished_NvBlockNeed_Block_ODO_4_JobFinished: start-on-event=NvMNotifyJobFinished_NvBlockNeed_Block_ODO_4_JobFinished, operation=NvMNotifyJobFinished_NvBlockNeed_Block_ODO_4.JobFinished
        OIT_NvMNotifyJobFinished_NvBlockNeed_Block_ODO_3_JobFinished_NvMNotifyJobFinished_NvBlockNeed_Block_ODO_3_JobFinished: start-on-event=NvMNotifyJobFinished_NvBlockNeed_Block_ODO_3_JobFinished, operation=NvMNotifyJobFinished_NvBlockNeed_Block_ODO_3.JobFinished
        OIT_NvMNotifyJobFinished_NvBlockNeed_Block_ODO_2_JobFinished_NvMNotifyJobFinished_NvBlockNeed_Block_ODO_2_JobFinished: start-on-event=NvMNotifyJobFinished_NvBlockNeed_Block_ODO_2_JobFinished, operation=NvMNotifyJobFinished_NvBlockNeed_Block_ODO_2.JobFinished
        OIT_NvMNotifyJobFinished_NvBlockNeed_Block_Trip_JobFinished_NvMNotifyJobFinished_NvBlockNeed_Block_Trip_JobFinished: start-on-event=NvMNotifyJobFinished_NvBlockNeed_Block_Trip_JobFinished, operation=NvMNotifyJobFinished_NvBlockNeed_Block_Trip.JobFinished
        OIT_NvMNotifyJobFinished_NvBlockNeed_Block_MaintainOdo_JobFinished_NvMNotifyJobFinished_NvBlockNeed_Block_MaintainOdo_JoEF103C2C: start-on-event=NvMNotifyJobFinished_NvBlockNeed_Block_MaintainOdo_JobFinished, operation=NvMNotifyJobFinished_NvBlockNeed_Block_MaintainOdo.JobFinished
      4 x timing event:
        TMT_Speedo_MainFunction: start-on-event=Common_Normal_20msMainFunction_A, period=0.02
        TMT_Tacho_MainFunction: start-on-event=Common_Normal_5msMainFunction, period=0.005
        TMT_TC_MainFunction: start-on-event=Common_Normal_100msMainFunction, period=0.1
        TMT_Common_Normal_MainFunction: start-on-event=Common_Normal_10msMainFunction, period=0.01
      operation invoked event OIT_Common_Normal_List_Deinit_Common_Normal_List_Deinit: start-on-event=Common_Normal_List_Deinit, operation=Common_Normal_List.Deinit
      operation invoked event OIT_Common_Normal_List_Int_Common_Normal_List_Int: start-on-event=Common_Normal_List_Int, operation=Common_Normal_List.Int
      4 x timing event:
        TMT_Common_Normal_10msMainFunction_: start-on-event=Common_Normal_10msMainFunction_, period=0.01
        TMT_Common_Normal_20msMainFunction_: start-on-event=Common_Normal_20msMainFunction_, period=0.02
        TMT_Common_Normal_50msMainFunction_: start-on-event=Common_Normal_20msMainFunction_B, period=0.02
        TMT_Common_Normal_100msMainFunction_: start-on-event=Common_Normal_100msMainFunction_, period=0.1
      asynchronous server call returns event ASCRE_TC_MainFunction_SC_IoHwAb_Interface_GetPin
      asynchronous server call returns event ASCRE_TC_MainFunction_SC_IoHwAb_Interface_GetVoltage
      32 x operation invoked event:
        OIT_RTE_TC_API_Set_TC_Module_Reset_Data_ppCS_SWCNormal_Reset_TC_Module_Data_WriteData: start-on-event=RTE_TC_API_Set_TC_Module_Reset_Data, operation=ppCS_SWCNormal_Reset_TC_Module_Data.WriteData
        OIT_DM_API_vGetDrvModTTStatus_ppCS_SWCNormal_DM_API_vGetDrvModTTStatus_Operation: start-on-event=DM_API_vGetDrvModTTStatus, operation=ppCS_SWCNormal_DM_API_vGetDrvModTTStatus.Operation
        OIT_DM_API_vGetDrvModWarningStatus_ppCS_SWCNormal_DM_API_vGetDrvModWarningStatus_Operation: start-on-event=DM_API_vGetDrvModWarningStatus, operation=ppCS_SWCNormal_DM_API_vGetDrvModWarningStatus.Operation
        OIT_NvMNotifyJobFinished_NvBlockNeed_Block_TC_Config_Data_JobFinished_NvMNotifyJobFinished_NvBlockNeed_Block_TC_Config_DDE1EEDD9: start-on-event=NvMNotifyJobFinished_NvBlockNeed_Block_TC_Config_Data_JobFinished, operation=NvMNotifyJobFinished_NvBlockNeed_Block_TC_Config_Data.JobFinished
        OIT_NvMNotifyJobFinished_NvBlockNeed_Block_TC_Data_JobFinished_NvMNotifyJobFinished_NvBlockNeed_Block_TC_Data_JobFinished: start-on-event=NvMNotifyJobFinished_NvBlockNeed_Block_TC_Data_JobFinished, operation=NvMNotifyJobFinished_NvBlockNeed_Block_TC_Data.JobFinished
        OIT_EOL_ReadDID0xFDD8_EOL_GetReadHardInputForCluster_EOL_ReadDID0xFDD8_EOL_GetReadHardInputForCluster: start-on-event=EOL_ReadDID0xFDD8_EOL_GetReadHardInputForCluster, operation=EOL_ReadDID0xFDD8.EOL_GetReadHardInputForCluster
        OIT_RTE_Odo_Api_ParamentSetFunction_ppCS_SWCNormal_OdoSetParament_Operation: start-on-event=RTE_Odo_Api_ParamentSetFunction, operation=ppCS_SWCNormal_OdoSetParament.Operation
        OIT_svCS_SWCNormal_TTCallback_Operation_svCS_SWCNormal_TTCallback_Operation: start-on-event=svCS_SWCNormal_TTCallback_Operation, operation=svCS_SWCNormal_TTCallback.Operation
        OIT_svCS_SWCNormal_ChimeCallback_Operation_svCS_SWCNormal_ChimeCallback_Operation: start-on-event=svCS_SWCNormal_ChimeCallback_Operation, operation=svCS_SWCNormal_ChimeCallback.Operation
        OIT_svCS_SWCNormal_WrnCallback_Operation_svCS_SWCNormal_WrnCallback_Operation: start-on-event=svCS_SWCNormal_WrnCallback_Operation, operation=svCS_SWCNormal_WrnCallback.Operation
        OIT_svCS_SWCNormal_ReceiveMenuSetting_Callback_svCS_SWCNormal_ReceiveMenuSetting_Callback: start-on-event=svCS_SWCNormal_ReceiveMenuSetting_Callback, operation=svCS_SWCNormal_ReceiveMenuSetting.Callback
        OIT_svCS_SWCNormal_HMIResetTC_Callback_svCS_SWCNormal_HMIResetTC_Callback: start-on-event=svCS_SWCNormal_HMIResetTC_Callback, operation=svCS_SWCNormal_HMIResetTC.Callback
        OIT_Common_Normal_Nomal2Standby_Callbcak_rpCS_Common_Nomal_PowerTransfer_Nomal2StandbyCallback: start-on-event=Common_Normal_Nomal2Standby_Callbcak, operation=rpCS_Common_Nomal_PowerTransfer.Nomal2StandbyCallback
        OIT_Common_Normal_Standby2Nomal_Callbcak_rpCS_Common_Nomal_PowerTransfer_Standby2NomalCallback: start-on-event=Common_Normal_Standby2Nomal_Callbcak, operation=rpCS_Common_Nomal_PowerTransfer.Standby2NomalCallback
        OIT_ppCS_GetTankResistanceValue_Operation_ppCS_GetTankResistanceValue_Operation: start-on-event=svCS_GetTankResistanceValue_Operation, operation=ppCS_GetTankResistanceValue.Operation
        OIT_svCS_SWCNormal_ReceiveSafetyGearCRCCallback_svCS_SWCNormal_ReceiveSafetyGearCRC_Callback: start-on-event=svCS_SWCNormal_ReceiveSafetyGearCRCCallback, operation=svCS_SWCNormal_ReceiveSafetyGearCRC.Callback
        OIT_svCS_SWCNormal_ReceiveSafetyTTCRCCallback_svCS_SWCNormal_ReceiveSafetyTTCRC_Callback: start-on-event=svCS_SWCNormal_ReceiveSafetyTTCRCCallback, operation=svCS_SWCNormal_ReceiveSafetyTTCRC.Callback
        OIT_Odo_Api_ParamentGetCsPort_ppCS_SWCNormal_Odo_Api_ParamentGetCsPort_Operation: start-on-event=Odo_Api_ParamentGetCsPortGetData, operation=ppCS_SWCNormal_Odo_Api_ParamentGetCsPort.Operation
        OIT_tiCS_Fuel_Api_ParamentGetCsPort_Operation_tiCS_Fuel_Api_ParamentGetCsPort_Operation: start-on-event=Fuel_Api_ParamentGetCsPort_Operation, operation=ppCS_Fuel_Api_ParamentGetCsPort.Operation
        OIT_NvMNotifyJobFinished_NvBlockNeed_Menu_JobFinished_NvMNotifyJobFinished_NvBlockNeed_Menu_JobFinished: start-on-event=NvMNotifyJobFinished_NvBlockNeed_Menu_JobFinished, operation=NvMNotifyJobFinished_NvBlockNeed_Menu.JobFinished
        OIT_CsmJob_Aes128_Decrypt_Cbk_Callback_CallbackNotification_CsmJob_Aes128_Decrypt_Cbk_Callback_CallbackNotification: start-on-event=CsmJob_Aes128_Decrypt_Cbk_Callback_CallbackNotification, operation=CsmJob_Aes128_Decrypt_Cbk_Callback.CallbackNotification
        OIT_CsmJob_Aes128_Encrypt_Cbk_Callback_CallbackNotification_CsmJob_Aes128_Encrypt_Cbk_Callback_CallbackNotification: start-on-event=CsmJob_Aes128_Encrypt_Cbk_Callback_CallbackNotification, operation=CsmJob_Aes128_Encrypt_Cbk_Callback.CallbackNotification
        OIT_svCS_SWCNormal_SensorAorB_Status_Operation_svCS_SWCNormal_SensorAorB_Status_Operation: start-on-event=SWCNormal_SensorAorB_Status_Operation, operation=svCS_SWCNormal_SensorAorB_Status.Operation
        OIT_ppCS_SWCNormal_TC_EnergyInfo_Operation_ppCS_SWCNormal_TC_EnergyInfo_Operation: start-on-event=TC_EnergyInfo, operation=ppCS_SWCNormal_TC_EnergyInfo.Operation
        OIT_ppCS_SWCNormal_TC_EnergyInfoResp_Operation_ppCS_SWCNormal_TC_EnergyInfoResp_Operation: start-on-event=TC_EnergyInfoResp, operation=ppCS_SWCNormal_TC_EnergyInfoResp.Operation
        OIT_TC_Api_ParamentGetCsPort_1_Operation_ppCS_TC_Api_ParamentGetCsPort_Operation: start-on-event=TC_Api_ParamentGetCsPort_1_Operation, operation=ppCS_TC_Api_ParamentGetCsPort.Operation
        OIT_svCS_SWCNormal_ReceiveAdasStatus_Callback_svCS_SWCNormal_ReceiveAdasStatus_Callback: start-on-event=svCS_SWCNormal_ReceiveAdasStatus_Callback, operation=svCS_SWCNormal_ReceiveAdasStatus.Callback
        OIT_svCS_SWCNormal_ReceiveHMIPowerMode_Callback_svCS_SWCNormal_ReceiveHMIPowerMode_Callback: start-on-event=svCS_SWCNormal_ReceiveHMIPowerMode_Callback, operation=svCS_SWCNormal_ReceiveHMIPowerMode.Callback
        OIT_ppCS_SWCNormal_ReceiveMenuTheme_Callback_ppCS_SWCNormal_ReceiveMenuTheme_Callback: start-on-event=ppCS_SWCNormal_ReceiveMenuTheme_Callback, operation=ppCS_SWCNormal_ReceiveMenuTheme.Callback
        OIT_ppCS_SWCNormal_OdoTimeSync_CallBack_ppCS_SWCNormal_OdoTimeSync_CallBack: start-on-event=ppCS_SWCNormal_OdoTimeSync_CallBack, operation=ppCS_SWCNormal_OdoTimeSync.CallBack
        OIT_ppCS_TtToChime_ppCS_TtToChime_Operation: start-on-event=ppCS_TtToChime, operation=ppCS_SWCNormal_TtToChime.Callback
        OIT_svCS_SWCNormal_ReceiveOffroadInfo_Callback_svCS_SWCNormal_ReceiveOffroadInfo_Callback: start-on-event=svCS_SWCNormal_ReceiveOffroadInfo_Callback, operation=svCS_SWCNormal_ReceiveOffroadInfo.Callback
      port-api-options:
        enable-take-address=true, error-handling=NO-TRANSFORMER-ERROR-HANDLING, indirect-api=false, port=Common_Normal_List
        enable-take-address=true, error-handling=NO-TRANSFORMER-ERROR-HANDLING, indirect-api=false, port=NvMService_AC3_SRBS_Defs_NvBlockNeed_Block_MaintainOdo
        enable-take-address=true, error-handling=NO-TRANSFORMER-ERROR-HANDLING, indirect-api=false, port=NvMService_AC3_SRBS_Defs_NvBlockNeed_Block_ODO_{1..5}
        enable-take-address=true, error-handling=NO-TRANSFORMER-ERROR-HANDLING, indirect-api=false, port=NvMService_AC3_SRBS_Defs_NvBlockNeed_Block_Trip
        enable-take-address=true, error-handling=NO-TRANSFORMER-ERROR-HANDLING, indirect-api=false, port=ppCS_SWCNormal_OdoSetParament
        enable-take-address=true, error-handling=NO-TRANSFORMER-ERROR-HANDLING, indirect-api=false, port=rpCS_SWCNormal_OdoSetParament
        enable-take-address=false, error-handling=NO-TRANSFORMER-ERROR-HANDLING, indirect-api=false, port=ppCS_SWCNormal_TtToChime
        enable-take-address=true, error-handling=NO-TRANSFORMER-ERROR-HANDLING, indirect-api=false, port=svCS_SWCNormal_ReceiveOffroadInfo
      51 x runnable:
        Common_Normal_20msMainFunction  # OffSet:4ms
          data-read-access:
            access REC_tiSR_Power_Out_SystemStateOut: accessed-variable=tiSR_Power_Out.SystemStateOut
          data-receive-point-by-arguments:
            166 x access:
              REC_ECM_VIN_ECM_VIN: accessed-variable=ECM_VIN.ECM19_0x3B5
              REC_ECM_VehDstBackup_ECM_VehDstBackup: accessed-variable=ECM_VehDstBackup.ECM_VehDstBackup
              REC_MILSts_MILSts: accessed-variable=MILSts.MILSts
              REC_EngSVSSig_EngSVSSig: accessed-variable=EngSVSSig.EngSVSSig
              REC_EngClntTempWarn_EngClntTempWarn: accessed-variable=EngClntTempWarn.EngClntTempWarn
              REC_CruiseCtrlSts_CruiseCtrlSts: accessed-variable=CruiseCtrlSts.CruiseCtrlSts
              REC_CruiseCtrlSts_PHEV_CruiseCtrlSts_PHEV: accessed-variable=CruiseCtrlSts_PHEV.CruiseCtrlSts_PHEV
              REC_SG_ACC4_ACC_FD2_SG_ACC4_ACC_FD2: accessed-variable=SG_ACC4_ACC_FD2.SG_ACC4_ACC_FD2
              REC_SS_Enable_Lamp_SS_Enable_Lamp: accessed-variable=SS_Enable_Lamp.SS_Enable_Lamp
              REC_SS_Fault_Lamp_SS_Fault_Lamp: accessed-variable=SS_Fault_Lamp.SS_Fault_Lamp
              REC_TirePressSysFailrIndcn_TirePressSysFailrIndcn: accessed-variable=TirePressSysFailrIndcn.TirePressSysFailrIndcn
              REC_FLTirePressIndSts_FLTirePressIndSts: accessed-variable=FLTirePressIndSts.FLTirePressIndSts
              REC_FRTirePressIndSts_FRTirePressIndSts: accessed-variable=FRTirePressIndSts.FRTirePressIndSts
              REC_RLTirePressIndSts_RLTirePressIndSts: accessed-variable=RLTirePressIndSts.RLTirePressIndSts
              REC_RRTirePressIndSts_RRTirePressIndSts: accessed-variable=RRTirePressIndSts.RRTirePressIndSts
              REC_FLTireTempSts_FLTireTempSts: accessed-variable=FLTireTempSts.FLTireTempSts
              REC_FRTireTempSts_FRTireTempSts: accessed-variable=FRTireTempSts.FRTireTempSts
              REC_RLTireTempSts_RLTireTempSts: accessed-variable=RLTireTempSts.RLTireTempSts
              REC_RRTireTempSts_RRTireTempSts: accessed-variable=RRTireTempSts.RRTireTempSts
              REC_SG_IFC4_IFC_FD2_SG_IFC4_IFC_FD2: accessed-variable=SG_IFC4_IFC_FD2.SG_IFC4_IFC_FD2
              REC_ESP_HMI_WarningOn_ESP_HMI_WarningOn: accessed-variable=ESP_HMI_WarningOn.ESP_HMI_WarningOn
              REC_IB_Warn_IB_Warn: accessed-variable=IB_Warn.IB_Warn
              REC_FFogLmpSts_F_Pbox_FFogLmpSts_F_Pbox: accessed-variable=FFogLmpSts_F_Pbox.FFogLmpSts_F_Pbox
              REC_RFogLmpFailSts_R_Pbox_RFogLmpFailSts_R_Pbox: accessed-variable=RFogLmpFailSts_R_Pbox.RFogLmpFailSts_R_Pbox
              REC_LTurnLmpSts_R_Pbox_LTurnLmpSts_R_Pbox: accessed-variable=LTurnLmpSts_R_Pbox.LTurnLmpSts_R_Pbox
              REC_RTurnLmpSts_R_Pbox_RTurnLmpSts_R_Pbox: accessed-variable=RTurnLmpSts_R_Pbox.RTurnLmpSts_R_Pbox
              REC_PosnLmpOutpSts_R_Pbox_PosnLmpOutpSts_R_Pbox: accessed-variable=PosnLmpOutpSts_R_Pbox.PosnLmpOutpSts_R_Pbox
              REC_TrailerSts_TrailerSts: accessed-variable=TrailerSts.TrailerSts
              REC_HiLowBeamSts_HiLowBeamSts: accessed-variable=HiLowBeamSts.HiLowBeamSts
              REC_HCU_EVLmpSts_HCU_EVLmpSts: accessed-variable=HCU_EVLmpSts.HCU_EVLmpSts
              REC_HCU_ChrgSysLmpSts_HCU_ChrgSysLmpSts: accessed-variable=HCU_ChrgSysLmpSts.HCU_ChrgSysLmpSts
              REC_ParkLmpSts_R_Pbox_ParkLmpSts_R_Pbox: accessed-variable=ParkLmpSts_R_Pbox.ParkLmpSts_R_Pbox
              REC_TgtRcprtnTrqSts_TgtRcprtnTrqSts: accessed-variable=TgtRcprtnTrqSts.TgtRcprtnTrqSts
              REC_CCO_Active_CCO_Active: accessed-variable=CCO_Active.CCO_Active
              REC_RSDS_CTA_Actv_RSDS_CTA_Actv: accessed-variable=RSDS_CTA_Actv.RSDS_CTA_Actv
              REC_RSDS_ErrSts_RSDS_ErrSts: accessed-variable=RSDS_ErrSts.RSDS_ErrSts
              REC_RemoteModSts_RemoteModSts: accessed-variable=RemoteModSts.RemoteModSts
              REC_KL30BRelaySts_KL30BRelaySts: accessed-variable=KL30BRelaySts.KL30BRelaySts
              REC_BMS_SOCLowWarn_BMS_SOCLowWarn: accessed-variable=BMS_SOCLowWarn.BMS_SOCLowWarn
              REC_TSRSts_TSRSts: accessed-variable=TSRSts.TSRSts
              REC_TSRSpdLimSts_TSRSpdLimSts: accessed-variable=TSRSpdLimSts.TSRSpdLimSts
              REC_TSRSpdLim_TSRSpdLim: accessed-variable=TSRSpdLim.TSRSpdLim
              REC_TSRSpdLimWarn_TSRSpdLimWarn: accessed-variable=TSRSpdLimWarn.TSRSpdLimWarn
              REC_TSRTrfcSignVal_TSRTrfcSignVal: accessed-variable=TSRTrfcSignVal.TSRTrfcSignVal
              REC_WPC_PhoneReminder_WPC_PhoneReminder: accessed-variable=WPC_PhoneReminder.WPC_PhoneReminder
              REC_WPC_FaultSts_WPC_FaultSts: accessed-variable=WPC_FaultSts.WPC_FaultSts
              REC_WarnVldKeyNotFound_WarnVldKeyNotFound: accessed-variable=WarnVldKeyNotFound.WarnVldKeyNotFound
              REC_WarnPowerNotInOffPosn_WarnPowerNotInOffPosn: accessed-variable=WarnPowerNotInOffPosn.WarnPowerNotInOffPosn
              REC_WarnKeyInCarWhenExit_WarnKeyInCarWhenExit: accessed-variable=WarnKeyInCarWhenExit.WarnKeyInCarWhenExit
              REC_WarnEngStrtNotMeet_WarnEngStrtNotMeet: accessed-variable=WarnEngStrtNotMeet.WarnEngStrtNotMeet
              REC_VSG_Sts_VSG_Sts: accessed-variable=VSG_Sts.VSG_Sts
              REC_VSG_HUTSoundResp_VSG_HUTSoundResp: accessed-variable=VSG_HUTSoundResp.VSG_HUTSoundResp
              REC_TrunkSts_TrunkSts: accessed-variable=TrunkSts.TrunkSts
              REC_TranPMode_Sts_TranPMode_Sts: accessed-variable=TranPMode_Sts.TranPMode_Sts
              REC_TgtCrsVehSpd_TgtCrsVehSpd: accessed-variable=TgtCrsVehSpd.TgtCrsVehSpd
              REC_SysPowerMod_SysPowerMod: accessed-variable=SysPowerMod.SysPowerMod
              REC_Stat_PwrSv_Lvl_Stat_PwrSv_Lvl: accessed-variable=Stat_PwrSv_Lvl.Stat_PwrSv_Lvl
              REC_SS_Screen_tip_SS_Screen_tip: accessed-variable=SS_Screen_tip.SS_Screen_tip
              REC_RvsLmpFailSts_RvsLmpFailSts: accessed-variable=RvsLmpFailSts.RvsLmpFailSts
              REC_RSDS_TrailerSts_RSDS_TrailerSts: accessed-variable=RSDS_TrailerSts.RSDS_TrailerSts
              REC_RSDS_RCW_Trigger_RSDS_RCW_Trigger: accessed-variable=RSDS_RCW_Trigger.RSDS_RCW_Trigger
              REC_RSDS_BrkgTrig_RSDS_BrkgTrig: accessed-variable=RSDS_BrkgTrig.RSDS_BrkgTrig
              REC_RRPosnLmpFailSts_RRPosnLmpFailSts: accessed-variable=RRPosnLmpFailSts.RRPosnLmpFailSts
              REC_RRDoorSts_RRDoorSts: accessed-variable=RRDoorSts.RRDoorSts
              REC_RotSteerWheel_RotSteerWheel: accessed-variable=RotSteerWheel.RotSteerWheel
              REC_RLSFailSts_RLSFailSts: accessed-variable=RLSFailSts.RLSFailSts
              REC_RLowBeamFailSts_RLowBeamFailSts: accessed-variable=RLowBeamFailSts.RLowBeamFailSts
              REC_RLasHdLmpDiagSig_RLasHdLmpDiagSig: accessed-variable=RLasHdLmpDiagSig.RLasHdLmpDiagSig
              REC_RHiBeamFailSts_RHiBeamFailSts: accessed-variable=RHiBeamFailSts.RHiBeamFailSts
              REC_RHeadLmpFailSts_RHeadLmpFailSts: accessed-variable=RHeadLmpFailSts.RHeadLmpFailSts
              REC_RFogLmpSts_R_Pbox_RFogLmpSts_R_Pbox: accessed-variable=RFogLmpSts_R_Pbox.RFogLmpSts_R_Pbox
              REC_RearELDLckSts_RearELDLckSts: accessed-variable=RearELDLckSts.RearELDLckSts
              REC_Rc_TachoInfo_EngSpd: accessed-variable=Rc_TachoInfo.EngSpd
              REC_Rc_TachoInfo_EngRunSts: accessed-variable=Rc_TachoInfo.EngRunSts
              REC_Rc_SpeedoInfo_VehRunSts: accessed-variable=Rc_SpeedoInfo.VehRunSts
              REC_Rc_SpeedoInfo_RealSpeed: accessed-variable=Rc_SpeedoInfo.RealSpeed
              REC_Rc_SpeedoInfo_OverSpdWrnFlg: accessed-variable=Rc_SpeedoInfo.OverSpdWrnFlg
              REC_Rc_SpeedoInfo_IndicateSpeed: accessed-variable=Rc_SpeedoInfo.IndicateSpeed
              REC_Rc_Odo_RunCounter_RunCounter: accessed-variable=Rc_Odo_RunCounter.RunCounter
              REC_Rc_Fuel_Status_Fuel_Status: accessed-variable=Rc_Fuel_Status.Fuel_Status
              REC_Rc_Cluster_Shutdown_Status_Element: accessed-variable=Rc_Cluster_Shutdown_Status.Element
              REC_RBrkLmpFailSts_RBrkLmpFailSts: accessed-variable=RBrkLmpFailSts.RBrkLmpFailSts
              REC_PressReliProgs_PressReliProgs: accessed-variable=PressReliProgs.PressReliProgs
              REC_PowerRlyFault_PowerRlyFault: accessed-variable=PowerRlyFault.PowerRlyFault
              REC_PassengerDoorSts_PassengerDoorSts: accessed-variable=PassengerDoorSts.PassengerDoorSts
              REC_OBC_ConnectSts_OBC_ConnectSts: accessed-variable=OBC_ConnectSts.OBC_ConnectSts
              REC_LvPwrSysErr_LvPwrSysErr: accessed-variable=LvPwrSysErr.LvPwrSysErr
              REC_LRPosnLmpFailSts_LRPosnLmpFailSts: accessed-variable=LRPosnLmpFailSts.LRPosnLmpFailSts
              REC_LRDoorSts_LRDoorSts: accessed-variable=LRDoorSts.LRDoorSts
              REC_LLowBeamFailSts_LLowBeamFailSts: accessed-variable=LLowBeamFailSts.LLowBeamFailSts
              REC_LLasHdLmpDiagSig_LLasHdLmpDiagSig: accessed-variable=LLasHdLmpDiagSig.LLasHdLmpDiagSig
              REC_LicPlateLmpFailSts_LicPlateLmpFailSts: accessed-variable=LicPlateLmpFailSts.LicPlateLmpFailSts
              REC_LHiBeamFailSts_LHiBeamFailSts: accessed-variable=LHiBeamFailSts.LHiBeamFailSts
              REC_LHeadLmpFailSts_LHeadLmpFailSts: accessed-variable=LHeadLmpFailSts.LHeadLmpFailSts
              REC_LBrkLmpFailSts_LBrkLmpFailSts: accessed-variable=LBrkLmpFailSts.LBrkLmpFailSts
              REC_LasHdLmpSts_F_Pbox_LasHdLmpSts_F_Pbox: accessed-variable=LasHdLmpSts_F_Pbox.LasHdLmpSts_F_Pbox
              REC_HoodSts_F_Pbox_HoodSts_F_Pbox: accessed-variable=HoodSts_F_Pbox.HoodSts_F_Pbox
              REC_HiPosnBrkLmpFailSts_HiPosnBrkLmpFailSts: accessed-variable=HiPosnBrkLmpFailSts.HiPosnBrkLmpFailSts
              REC_HiBeamSts_F_Pbox_HiBeamSts_F_Pbox: accessed-variable=HiBeamSts_F_Pbox.HiBeamSts_F_Pbox
              REC_HCUImmoAuthRes_HCUImmoAuthRes: accessed-variable=HCUImmoAuthRes.HCUImmoAuthRes
              REC_HCU_WorkshopMode_HCU_WorkshopMode: accessed-variable=HCU_WorkshopMode.HCU_WorkshopMode
              REC_HCU_TotDrvReqPower_HCU_TotDrvReqPower: accessed-variable=HCU_TotDrvReqPower.HCU_TotDrvReqPower
              REC_HCU_RecupPwr_HCU_RecupPwr: accessed-variable=HCU_RecupPwr.HCU_RecupPwr
              REC_HCU_RaceLaunchSts_HCU_RaceLaunchSts: accessed-variable=HCU_RaceLaunchSts.HCU_RaceLaunchSts
              REC_HCU_RaceLaunchAvail_HCU_RaceLaunchAvail: accessed-variable=HCU_RaceLaunchAvail.HCU_RaceLaunchAvail
              REC_HCU_IntelBattTempMagSts_HCU_IntelBattTempMagSts: accessed-variable=HCU_IntelBattTempMagSts.HCU_IntelBattTempMagSts
              REC_HCU_EVContnsDistanceVld_HCU_EVContnsDistanceVld: accessed-variable=HCU_EVContnsDistanceVld.HCU_EVContnsDistanceVld
              REC_HCU_EVContnsDistance_HCU_EVContnsDistance: accessed-variable=HCU_EVContnsDistance.HCU_EVContnsDistance
              REC_HCU_EgyUsed_HCU_EgyUsed: accessed-variable=HCU_EgyUsed.HCU_EgyUsed
              REC_HCU_ECODrvHabit_Indcn_HCU_ECODrvHabit_Indcn: accessed-variable=HCU_ECODrvHabit_Indcn.HCU_ECODrvHabit_Indcn
              REC_HCU_DrvMod_HCU_DrvMod: accessed-variable=HCU_DrvMod.HCU_DrvMod
              REC_HCU_ChrgSysErr_8_HCU_ChrgSysErr_8: accessed-variable=HCU_ChrgSysErr_8.HCU_ChrgSysErr_8
              REC_HCU_ChrgSysErr_7_HCU_ChrgSysErr_7: accessed-variable=HCU_ChrgSysErr_7.HCU_ChrgSysErr_7
              REC_HCU_ChrgSysErr_6_HCU_ChrgSysErr_6: accessed-variable=HCU_ChrgSysErr_6.HCU_ChrgSysErr_6
              REC_HCU_ChrgSysErr_5_HCU_ChrgSysErr_5: accessed-variable=HCU_ChrgSysErr_5.HCU_ChrgSysErr_5
              REC_HCU_ChrgSysErr_4_HCU_ChrgSysErr_4: accessed-variable=HCU_ChrgSysErr_4.HCU_ChrgSysErr_4
              REC_HCU_ChrgSysErr_3_HCU_ChrgSysErr_3: accessed-variable=HCU_ChrgSysErr_3.HCU_ChrgSysErr_3
              REC_HCU_ChrgSysErr_2_HCU_ChrgSysErr_2: accessed-variable=HCU_ChrgSysErr_2.HCU_ChrgSysErr_2
              REC_HCU_ChrgSysErr_1_HCU_ChrgSysErr_1: accessed-variable=HCU_ChrgSysErr_1.HCU_ChrgSysErr_1
              REC_HCU_ChargSts_HCU_ChargSts: accessed-variable=HCU_ChargSts.HCU_ChargSts
              REC_HCU_BattLowTemWarn_HCU_BattLowTemWarn: accessed-variable=HCU_BattLowTemWarn.HCU_BattLowTemWarn
              REC_HCU_BattLowHeatSts_HCU_BattLowHeatSts: accessed-variable=HCU_BattLowHeatSts.HCU_BattLowHeatSts
              REC_HCU_AvailPower_TM_HCU_AvailPower_TM: accessed-variable=HCU_AvailPower_TM.HCU_AvailPower_TM
              REC_HCU_ACLineDisconnect_HCU_ACLineDisconnect: accessed-variable=HCU_ACLineDisconnect.HCU_ACLineDisconnect
              REC_GPF_Warning_GPF_Warning: accessed-variable=GPF_Warning.GPF_Warning
              REC_FuelTankCapWarning_FuelTankCapWarning: accessed-variable=FuelTankCapWarning.FuelTankCapWarning
              REC_FTIVFault_FTIVFault: accessed-variable=FTIVFault.FTIVFault
              REC_EWP_Err_EWP_Err: accessed-variable=EWP_Err.EWP_Err
              REC_EspFuncOffSts_mode_EspFuncOffSts_mode: accessed-variable=EspFuncOffSts_mode.EspFuncOffSts_mode
              REC_EngSpdVldty_EngSpdVldty: accessed-variable=EngSpdVldty.EngSpdVldty
              REC_EngSpd_ForIP_EngSpd_ForIP: accessed-variable=EngSpd_ForIP.EngSpd_ForIP
              REC_EMS_AuthenResult_EMS_AuthenResult: accessed-variable=EMS_AuthenResult.EMS_AuthenResult
              REC_ECM11_EngSpd_ForIP_EngSpd_ForIP: accessed-variable=ECM11_EngSpd_ForIP.EngSpd_ForIP
              REC_ECM1_EngSpdVldty_EngSpdVldty: accessed-variable=ECM1_EngSpdVldty.EngSpdVldty
              REC_Dyn_PwrSv_Lvl_Dyn_PwrSv_Lvl: accessed-variable=Dyn_PwrSv_Lvl.Dyn_PwrSv_Lvl
              REC_DrvDoorSts_DrvDoorSts: accessed-variable=DrvDoorSts.DrvDoorSts
              REC_DrowsyDrvDetWarn_DrowsyDrvDetWarn: accessed-variable=DrowsyDrvDetWarn.DrowsyDrvDetWarn
              REC_DrowsnsLvl_DrowsnsLvl: accessed-variable=DrowsnsLvl.DrowsnsLvl
              REC_DMSProcSts_DMSProcSts: accessed-variable=DMSProcSts.DMSProcSts
              REC_DMSProcResult_DMSProcResult: accessed-variable=DMSProcResult.DMSProcResult
              REC_DMSProc_DMSProc: accessed-variable=DMSProc.DMSProc
              REC_DistrctnLvl_DistrctnLvl: accessed-variable=DistrctnLvl.DistrctnLvl
              REC_DiagLmpReq_DiagLmpReq: accessed-variable=DiagLmpReq.DiagLmpReq
              REC_DCT3_TgtEngSpdIPValid_TgtEngSpdIPValid: accessed-variable=DCT3_TgtEngSpdIPValid.TgtEngSpdIPValid
              REC_DCT3_TgtEngSpdIP_TgtEngSpdIP: accessed-variable=DCT3_TgtEngSpdIP.TgtEngSpdIP
              REC_CouplingThermWarning_CouplingThermWarning: accessed-variable=CouplingThermWarning.CouplingThermWarning
              REC_CCO_Warn_CCO_Warn: accessed-variable=CCO_Warn.CCO_Warn
              REC_CCO_TgtVel_CCO_TgtVel: accessed-variable=CCO_TgtVel.CCO_TgtVel
              REC_BrkPedalSts_BCM_BrkPedalSts_BCM: accessed-variable=BrkPedalSts_BCM.BrkPedalSts_BCM
              REC_BMS_ChrgDurationTime_BMS_ChrgDurationTime: accessed-variable=BMS_ChrgDurationTime.BMS_ChrgDurationTime
              REC_BMS_BattSOC_BMS_BattSOC: accessed-variable=BMS_BattSOC.BMS_BattSOC
              REC_BMS_BattHeatRunaway_BMS_BattHeatRunaway: accessed-variable=BMS_BattHeatRunaway.BMS_BattHeatRunaway
              REC_AutoLmpSwtSts_AutoLmpSwtSts: accessed-variable=AutoLmpSwtSts.AutoLmpSwtSts
              REC_AccelPedlPosnDiagc_AccelPedlPosnDiagc: accessed-variable=AccelPedlPosnDiagc.AccelPedlPosnDiagc
              REC_AccelPedalPosnVldty_AccelPedalPosnVldty: accessed-variable=AccelPedalPosnVldty.AccelPedalPosnVldty
              REC_ACAmbTemp_ACAmbTemp: accessed-variable=ACAmbTemp.ACAmbTemp
              REC_HCU_AccelPedalPosn_Diag_HCU_AccelPedalPosn_Diag: accessed-variable=HCU_AccelPedalPosn_Diag.HCU_AccelPedalPosn_Diag
              REC_HCU_AccelPedalPosn_DiagValid_HCU_AccelPedalPosn_DiagValid: accessed-variable=HCU_AccelPedalPosn_DiagValid.HCU_AccelPedalPosn_DiagValid
              REC_RSDS_BliSts_RSDS_BliSts: accessed-variable=RSDS_BliSts.RSDS_BliSts
              REC_RSDS_LCAResp_RSDS_LCAResp: accessed-variable=RSDS_LCAResp.RSDS_LCAResp
              REC_rpSR_SWCNormal_OdoParament_Element: accessed-variable=rpSR_SWCNormal_OdoParament.Element
              REC_rpSR_SWCNormal_SpeedoInfo_Element: accessed-variable=rpSR_SWCNormal_SpeedoInfo.Element
              REC_rpSR_SWCNormal_TachoInfo_Element: accessed-variable=rpSR_SWCNormal_TachoInfo.Element
              REC_rpSR_SWCNormal_Fuel_Set_Module_Data_Element: accessed-variable=rpSR_SWCNormal_Fuel_Set_Module_Data.Element
              REC_rpSR_SWCNormal_TC_Module_Output_Data_Element: accessed-variable=rpSR_SWCNormal_TC_Module_Output_Data.Element
              REC_rpSR_SWCNormal_TC_NE_ChargStsOutput_Element: accessed-variable=rpSR_SWCNormal_TC_NE_ChargStsOutput.Element
          data-send-points:
            access SEND_Sd_Odo_RunCounter_RunCounter: accessed-variable=Sd_Odo_RunCounter.RunCounter
            access SEND_ppSR_SWCNormal_SpeedoInfo_Element: accessed-variable=ppSR_SWCNormal_SpeedoInfo.Element
            access SEND_ppSR_SWCNormal_TachoInfo_Element: accessed-variable=ppSR_SWCNormal_TachoInfo.Element
          59 x sync call:
            SC_Os_Service_GetCounterValue: operation=Os_Service.GetCounterValue
            SC_Os_Service_GetElapsedValue: operation=Os_Service.GetElapsedValue
            SC_NvMService_AC3_SRBS_Defs_NvBlockNeed_Block_ODO_1_EraseBlock: operation=NvMService_AC3_SRBS_Defs_NvBlockNeed_Block_ODO_1.EraseBlock
            SC_NvMService_AC3_SRBS_Defs_NvBlockNeed_Block_ODO_1_GetErrorStatus: operation=NvMService_AC3_SRBS_Defs_NvBlockNeed_Block_ODO_1.GetErrorStatus
            SC_NvMService_AC3_SRBS_Defs_NvBlockNeed_Block_ODO_1_InvalidateNvBlock: operation=NvMService_AC3_SRBS_Defs_NvBlockNeed_Block_ODO_1.InvalidateNvBlock
            SC_NvMService_AC3_SRBS_Defs_NvBlockNeed_Block_ODO_1_ReadBlock: operation=NvMService_AC3_SRBS_Defs_NvBlockNeed_Block_ODO_1.ReadBlock
            SC_NvMService_AC3_SRBS_Defs_NvBlockNeed_Block_ODO_1_RestoreBlockDefaults: operation=NvMService_AC3_SRBS_Defs_NvBlockNeed_Block_ODO_1.RestoreBlockDefaults
            SC_NvMService_AC3_SRBS_Defs_NvBlockNeed_Block_ODO_1_SetRamBlockStatus: operation=NvMService_AC3_SRBS_Defs_NvBlockNeed_Block_ODO_1.SetRamBlockStatus
            SC_NvMService_AC3_SRBS_Defs_NvBlockNeed_Block_ODO_1_WriteBlock: operation=NvMService_AC3_SRBS_Defs_NvBlockNeed_Block_ODO_1.WriteBlock
            SC_NvMService_AC3_SRBS_Defs_NvBlockNeed_Block_ODO_2_EraseBlock: operation=NvMService_AC3_SRBS_Defs_NvBlockNeed_Block_ODO_2.EraseBlock
            SC_NvMService_AC3_SRBS_Defs_NvBlockNeed_Block_ODO_2_GetErrorStatus: operation=NvMService_AC3_SRBS_Defs_NvBlockNeed_Block_ODO_2.GetErrorStatus
            SC_NvMService_AC3_SRBS_Defs_NvBlockNeed_Block_ODO_2_InvalidateNvBlock: operation=NvMService_AC3_SRBS_Defs_NvBlockNeed_Block_ODO_2.InvalidateNvBlock
            SC_NvMService_AC3_SRBS_Defs_NvBlockNeed_Block_ODO_2_ReadBlock: operation=NvMService_AC3_SRBS_Defs_NvBlockNeed_Block_ODO_2.ReadBlock
            SC_NvMService_AC3_SRBS_Defs_NvBlockNeed_Block_ODO_2_RestoreBlockDefaults: operation=NvMService_AC3_SRBS_Defs_NvBlockNeed_Block_ODO_2.RestoreBlockDefaults
            SC_NvMService_AC3_SRBS_Defs_NvBlockNeed_Block_ODO_2_SetRamBlockStatus: operation=NvMService_AC3_SRBS_Defs_NvBlockNeed_Block_ODO_2.SetRamBlockStatus
            SC_NvMService_AC3_SRBS_Defs_NvBlockNeed_Block_ODO_2_WriteBlock: operation=NvMService_AC3_SRBS_Defs_NvBlockNeed_Block_ODO_2.WriteBlock
            SC_NvMService_AC3_SRBS_Defs_NvBlockNeed_Block_ODO_3_EraseBlock: operation=NvMService_AC3_SRBS_Defs_NvBlockNeed_Block_ODO_3.EraseBlock
            SC_NvMService_AC3_SRBS_Defs_NvBlockNeed_Block_ODO_3_GetErrorStatus: operation=NvMService_AC3_SRBS_Defs_NvBlockNeed_Block_ODO_3.GetErrorStatus
            SC_NvMService_AC3_SRBS_Defs_NvBlockNeed_Block_ODO_3_InvalidateNvBlock: operation=NvMService_AC3_SRBS_Defs_NvBlockNeed_Block_ODO_3.InvalidateNvBlock
            SC_NvMService_AC3_SRBS_Defs_NvBlockNeed_Block_ODO_3_ReadBlock: operation=NvMService_AC3_SRBS_Defs_NvBlockNeed_Block_ODO_3.ReadBlock
            SC_NvMService_AC3_SRBS_Defs_NvBlockNeed_Block_ODO_3_RestoreBlockDefaults: operation=NvMService_AC3_SRBS_Defs_NvBlockNeed_Block_ODO_3.RestoreBlockDefaults
            SC_NvMService_AC3_SRBS_Defs_NvBlockNeed_Block_ODO_3_SetRamBlockStatus: operation=NvMService_AC3_SRBS_Defs_NvBlockNeed_Block_ODO_3.SetRamBlockStatus
            SC_NvMService_AC3_SRBS_Defs_NvBlockNeed_Block_ODO_3_WriteBlock: operation=NvMService_AC3_SRBS_Defs_NvBlockNeed_Block_ODO_3.WriteBlock
            SC_NvMService_AC3_SRBS_Defs_NvBlockNeed_Block_ODO_4_EraseBlock: operation=NvMService_AC3_SRBS_Defs_NvBlockNeed_Block_ODO_4.EraseBlock
            SC_NvMService_AC3_SRBS_Defs_NvBlockNeed_Block_ODO_4_GetErrorStatus: operation=NvMService_AC3_SRBS_Defs_NvBlockNeed_Block_ODO_4.GetErrorStatus
            SC_NvMService_AC3_SRBS_Defs_NvBlockNeed_Block_ODO_4_InvalidateNvBlock: operation=NvMService_AC3_SRBS_Defs_NvBlockNeed_Block_ODO_4.InvalidateNvBlock
            SC_NvMService_AC3_SRBS_Defs_NvBlockNeed_Block_ODO_4_ReadBlock: operation=NvMService_AC3_SRBS_Defs_NvBlockNeed_Block_ODO_4.ReadBlock
            SC_NvMService_AC3_SRBS_Defs_NvBlockNeed_Block_ODO_4_RestoreBlockDefaults: operation=NvMService_AC3_SRBS_Defs_NvBlockNeed_Block_ODO_4.RestoreBlockDefaults
            SC_NvMService_AC3_SRBS_Defs_NvBlockNeed_Block_ODO_4_SetRamBlockStatus: operation=NvMService_AC3_SRBS_Defs_NvBlockNeed_Block_ODO_4.SetRamBlockStatus
            SC_NvMService_AC3_SRBS_Defs_NvBlockNeed_Block_ODO_4_WriteBlock: operation=NvMService_AC3_SRBS_Defs_NvBlockNeed_Block_ODO_4.WriteBlock
            SC_NvMService_AC3_SRBS_Defs_NvBlockNeed_Block_ODO_5_EraseBlock: operation=NvMService_AC3_SRBS_Defs_NvBlockNeed_Block_ODO_5.EraseBlock
            SC_NvMService_AC3_SRBS_Defs_NvBlockNeed_Block_ODO_5_GetErrorStatus: operation=NvMService_AC3_SRBS_Defs_NvBlockNeed_Block_ODO_5.GetErrorStatus
            SC_NvMService_AC3_SRBS_Defs_NvBlockNeed_Block_ODO_5_InvalidateNvBlock: operation=NvMService_AC3_SRBS_Defs_NvBlockNeed_Block_ODO_5.InvalidateNvBlock
            SC_NvMService_AC3_SRBS_Defs_NvBlockNeed_Block_ODO_5_ReadBlock: operation=NvMService_AC3_SRBS_Defs_NvBlockNeed_Block_ODO_5.ReadBlock
            SC_NvMService_AC3_SRBS_Defs_NvBlockNeed_Block_ODO_5_RestoreBlockDefaults: operation=NvMService_AC3_SRBS_Defs_NvBlockNeed_Block_ODO_5.RestoreBlockDefaults
            SC_NvMService_AC3_SRBS_Defs_NvBlockNeed_Block_ODO_5_SetRamBlockStatus: operation=NvMService_AC3_SRBS_Defs_NvBlockNeed_Block_ODO_5.SetRamBlockStatus
            SC_NvMService_AC3_SRBS_Defs_NvBlockNeed_Block_ODO_5_WriteBlock: operation=NvMService_AC3_SRBS_Defs_NvBlockNeed_Block_ODO_5.WriteBlock
            SC_IPC_Send_IPC_Send: operation=IPC_Send.IPC_Send
            SC_NvMService_AC3_SRBS_Defs_NvBlockNeed_Block_MaintainOdo_EraseBlock: operation=NvMService_AC3_SRBS_Defs_NvBlockNeed_Block_MaintainOdo.EraseBlock
            SC_NvMService_AC3_SRBS_Defs_NvBlockNeed_Block_MaintainOdo_GetErrorStatus: operation=NvMService_AC3_SRBS_Defs_NvBlockNeed_Block_MaintainOdo.GetErrorStatus
            SC_NvMService_AC3_SRBS_Defs_NvBlockNeed_Block_MaintainOdo_InvalidateNvBlock: operation=NvMService_AC3_SRBS_Defs_NvBlockNeed_Block_MaintainOdo.InvalidateNvBlock
            SC_NvMService_AC3_SRBS_Defs_NvBlockNeed_Block_MaintainOdo_ReadBlock: operation=NvMService_AC3_SRBS_Defs_NvBlockNeed_Block_MaintainOdo.ReadBlock
            SC_NvMService_AC3_SRBS_Defs_NvBlockNeed_Block_MaintainOdo_RestoreBlockDefaults: operation=NvMService_AC3_SRBS_Defs_NvBlockNeed_Block_MaintainOdo.RestoreBlockDefaults
            SC_NvMService_AC3_SRBS_Defs_NvBlockNeed_Block_MaintainOdo_SetRamBlockStatus: operation=NvMService_AC3_SRBS_Defs_NvBlockNeed_Block_MaintainOdo.SetRamBlockStatus
            SC_NvMService_AC3_SRBS_Defs_NvBlockNeed_Block_MaintainOdo_WriteBlock: operation=NvMService_AC3_SRBS_Defs_NvBlockNeed_Block_MaintainOdo.WriteBlock
            SC_NvMService_AC3_SRBS_Defs_NvBlockNeed_Block_Trip_EraseBlock: operation=NvMService_AC3_SRBS_Defs_NvBlockNeed_Block_Trip.EraseBlock
            SC_NvMService_AC3_SRBS_Defs_NvBlockNeed_Block_Trip_GetErrorStatus: operation=NvMService_AC3_SRBS_Defs_NvBlockNeed_Block_Trip.GetErrorStatus
            SC_NvMService_AC3_SRBS_Defs_NvBlockNeed_Block_Trip_InvalidateNvBlock: operation=NvMService_AC3_SRBS_Defs_NvBlockNeed_Block_Trip.InvalidateNvBlock
            SC_NvMService_AC3_SRBS_Defs_NvBlockNeed_Block_Trip_ReadBlock: operation=NvMService_AC3_SRBS_Defs_NvBlockNeed_Block_Trip.ReadBlock
            SC_NvMService_AC3_SRBS_Defs_NvBlockNeed_Block_Trip_RestoreBlockDefaults: operation=NvMService_AC3_SRBS_Defs_NvBlockNeed_Block_Trip.RestoreBlockDefaults
            SC_NvMService_AC3_SRBS_Defs_NvBlockNeed_Block_Trip_SetRamBlockStatus: operation=NvMService_AC3_SRBS_Defs_NvBlockNeed_Block_Trip.SetRamBlockStatus
            SC_NvMService_AC3_SRBS_Defs_NvBlockNeed_Block_Trip_WriteBlock: operation=NvMService_AC3_SRBS_Defs_NvBlockNeed_Block_Trip.WriteBlock
            SC_rpCS_SWCNormal_Reset_TC_Module_Data_WriteData: operation=rpCS_SWCNormal_Reset_TC_Module_Data.WriteData
            SC_rpCS_SWCNormal_DM_API_vGetDrvModTTStatus_Operation: operation=rpCS_SWCNormal_DM_API_vGetDrvModTTStatus.Operation
            SC_rpCS_SWCNormal_DM_API_vGetDrvModWarningStatus_Operation: operation=rpCS_SWCNormal_DM_API_vGetDrvModWarningStatus.Operation
            SC_VConfig_GetKindConfig_Operation_VConfig_GetKindConfig: operation=VConfig_GetKindConfig.Operation_VConfig_GetKindConfig
            SC_VConfig_GetUpdateTick_OperationVConfig_GetUpdateTick: operation=VConfig_GetUpdateTick.OperationVConfig_GetUpdateTick
            SC_IoHwAb_Interface_GetPin: operation=IoHwAb_Interface.GetPin
            SC_IoHwAb_Interface_GetVoltage: operation=IoHwAb_Interface.GetVoltage
        Common_Normal_Init
        NvMNotifyJobFinished_NvBlockNeed_Block_ODO_1_JobFinished
        NvMNotifyJobFinished_NvBlockNeed_Block_ODO_5_JobFinished
        NvMNotifyJobFinished_NvBlockNeed_Block_ODO_4_JobFinished
        NvMNotifyJobFinished_NvBlockNeed_Block_ODO_3_JobFinished
        NvMNotifyJobFinished_NvBlockNeed_Block_ODO_2_JobFinished
        NvMNotifyJobFinished_NvBlockNeed_Block_Trip_JobFinished
        NvMNotifyJobFinished_NvBlockNeed_Block_MaintainOdo_JobFinished
        Common_Normal_20msMainFunction_A  # OffSet:7ms
          data-receive-point-by-arguments:
            access REC_AVASDTCResults_AVASDTC: accessed-variable=AVASDTCResults.AVASDTC
        Common_Normal_5msMainFunction: can-enter-exclusive-area=ExclusiveArea_Normal  # OffSet:0ms
          6 x sync call:
            SC_NvMService_AC3_SRBS_NvBlockNeed_Menu_EraseBlock: operation=NvMService_AC3_SRBS_NvBlockNeed_Menu.EraseBlock
            SC_NvMService_AC3_SRBS_NvBlockNeed_Menu_GetErrorStatus: operation=NvMService_AC3_SRBS_NvBlockNeed_Menu.GetErrorStatus
            SC_NvMService_AC3_SRBS_NvBlockNeed_Menu_InvalidateNvBlock: operation=NvMService_AC3_SRBS_NvBlockNeed_Menu.InvalidateNvBlock
            SC_NvMService_AC3_SRBS_NvBlockNeed_Menu_ReadBlock: operation=NvMService_AC3_SRBS_NvBlockNeed_Menu.ReadBlock
            SC_NvMService_AC3_SRBS_NvBlockNeed_Menu_SetRamBlockStatus: operation=NvMService_AC3_SRBS_NvBlockNeed_Menu.SetRamBlockStatus
            SC_NvMService_AC3_SRBS_NvBlockNeed_Menu_WriteBlock: operation=NvMService_AC3_SRBS_NvBlockNeed_Menu.WriteBlock
        Common_Normal_100msMainFunction  # OffSet:9ms
          data-read-access:
            access REC_tiSR_Power_Out_SystemStateOut: accessed-variable=tiSR_Power_Out.SystemStateOut
          data-receive-point-by-arguments:
            access REC_Rc_Odo_RunCounter_RunCounter: accessed-variable=Rc_Odo_RunCounter.RunCounter
            access REC_Rc_Fuel_Status_Fuel_Status: accessed-variable=Rc_Fuel_Status.Fuel_Status
          data-send-points:
            4 x access:
              SEND_Sd_Fuel_Status_Fuel_Status: accessed-variable=Sd_Fuel_Status.Fuel_Status
              SEND_ppSR_SWCNormal_OdoParament_Element: accessed-variable=ppSR_SWCNormal_OdoParament.Element
              SEND_ppSR_SWCNormal_Fuel_Set_Module_Data_Element: accessed-variable=ppSR_SWCNormal_Fuel_Set_Module_Data.Element
              SEND_ppSR_SWCNormal_TC_Module_Output_Data_Element: accessed-variable=ppSR_SWCNormal_TC_Module_Output_Data.Element
          sync call SC_IoHwAb_Interface_GetPin: operation=IoHwAb_Interface.GetPin
          sync call SC_IoHwAb_Interface_GetVoltage: operation=IoHwAb_Interface.GetVoltage
          wait point WP_TC_MainFunction_SC_IoHwAb_Interface_GetPin
          wait point WP_TC_MainFunction_SC_IoHwAb_Interface_GetVoltage
        Common_Normal_10msMainFunction: can-enter-exclusive-area=ExclusiveArea_Normal  # OffSet:2ms
          data-read-access:
            access REC_tiSR_Power_Out_SystemStateOut: accessed-variable=tiSR_Power_Out.SystemStateOut
          data-receive-point-by-arguments:
            270 x access:
              REC_Rc_Cluster_Shutdown_Status_Element: accessed-variable=Rc_Cluster_Shutdown_Status.Element
              REC_SS_Screen_tip_SS_Screen_tip: accessed-variable=SS_Screen_tip.SS_Screen_tip
              REC_TgtCrsVehSpd_TgtCrsVehSpd: accessed-variable=TgtCrsVehSpd.TgtCrsVehSpd
              REC_EngSpd_ForIP_EngSpd_ForIP: accessed-variable=EngSpd_ForIP.EngSpd_ForIP
              REC_EngSpdVldty_EngSpdVldty: accessed-variable=EngSpdVldty.EngSpdVldty
              REC_TranPMode_Sts_TranPMode_Sts: accessed-variable=TranPMode_Sts.TranPMode_Sts
              REC_Dyn_PwrSv_Lvl_Dyn_PwrSv_Lvl: accessed-variable=Dyn_PwrSv_Lvl.Dyn_PwrSv_Lvl
              REC_Stat_PwrSv_Lvl_Stat_PwrSv_Lvl: accessed-variable=Stat_PwrSv_Lvl.Stat_PwrSv_Lvl
              REC_LvPwrSysErr_LvPwrSysErr: accessed-variable=LvPwrSysErr.LvPwrSysErr
              REC_BMS_SOCLowWarn_BMS_SOCLowWarn: accessed-variable=BMS_SOCLowWarn.BMS_SOCLowWarn
              REC_CCO_Active_CCO_Active: accessed-variable=CCO_Active.CCO_Active
              REC_CruiseCtrlSts_CruiseCtrlSts: accessed-variable=CruiseCtrlSts.CruiseCtrlSts
              REC_CruiseCtrlSts_PHEV_CruiseCtrlSts_PHEV: accessed-variable=CruiseCtrlSts_PHEV.CruiseCtrlSts_PHEV
              REC_DrvDoorSts_DrvDoorSts: accessed-variable=DrvDoorSts.DrvDoorSts
              REC_ECM_VIN_ECM_VIN: accessed-variable=ECM_VIN.ECM19_0x3B5
              REC_ECM_VehDstBackup_ECM_VehDstBackup: accessed-variable=ECM_VehDstBackup.ECM_VehDstBackup
              REC_ESP_HMI_WarningOn_ESP_HMI_WarningOn: accessed-variable=ESP_HMI_WarningOn.ESP_HMI_WarningOn
              REC_EngClntTempWarn_EngClntTempWarn: accessed-variable=EngClntTempWarn.EngClntTempWarn
              REC_EngSVSSig_EngSVSSig: accessed-variable=EngSVSSig.EngSVSSig
              REC_FFogLmpSts_F_Pbox_FFogLmpSts_F_Pbox: accessed-variable=FFogLmpSts_F_Pbox.FFogLmpSts_F_Pbox
              REC_FLTirePressIndSts_FLTirePressIndSts: accessed-variable=FLTirePressIndSts.FLTirePressIndSts
              REC_FLTireTempSts_FLTireTempSts: accessed-variable=FLTireTempSts.FLTireTempSts
              REC_FRTirePressIndSts_FRTirePressIndSts: accessed-variable=FRTirePressIndSts.FRTirePressIndSts
              REC_FRTireTempSts_FRTireTempSts: accessed-variable=FRTireTempSts.FRTireTempSts
              REC_HCU_ChrgSysLmpSts_HCU_ChrgSysLmpSts: accessed-variable=HCU_ChrgSysLmpSts.HCU_ChrgSysLmpSts
              REC_HCU_EVLmpSts_HCU_EVLmpSts: accessed-variable=HCU_EVLmpSts.HCU_EVLmpSts
              REC_HiLowBeamSts_HiLowBeamSts: accessed-variable=HiLowBeamSts.HiLowBeamSts
              REC_IB_Warn_IB_Warn: accessed-variable=IB_Warn.IB_Warn
              REC_KL30BRelaySts_KL30BRelaySts: accessed-variable=KL30BRelaySts.KL30BRelaySts
              REC_LRDoorSts_LRDoorSts: accessed-variable=LRDoorSts.LRDoorSts
              REC_LTurnLmpSts_R_Pbox_LTurnLmpSts_R_Pbox: accessed-variable=LTurnLmpSts_R_Pbox.LTurnLmpSts_R_Pbox
              REC_MILSts_MILSts: accessed-variable=MILSts.MILSts
              REC_ParkLmpSts_R_Pbox_ParkLmpSts_R_Pbox: accessed-variable=ParkLmpSts_R_Pbox.ParkLmpSts_R_Pbox
              REC_PassengerDoorSts_PassengerDoorSts: accessed-variable=PassengerDoorSts.PassengerDoorSts
              REC_PosnLmpOutpSts_R_Pbox_PosnLmpOutpSts_R_Pbox: accessed-variable=PosnLmpOutpSts_R_Pbox.PosnLmpOutpSts_R_Pbox
              REC_RFogLmpFailSts_R_Pbox_RFogLmpFailSts_R_Pbox: accessed-variable=RFogLmpFailSts_R_Pbox.RFogLmpFailSts_R_Pbox
              REC_RLTirePressIndSts_RLTirePressIndSts: accessed-variable=RLTirePressIndSts.RLTirePressIndSts
              REC_RLTireTempSts_RLTireTempSts: accessed-variable=RLTireTempSts.RLTireTempSts
              REC_RRDoorSts_RRDoorSts: accessed-variable=RRDoorSts.RRDoorSts
              REC_RRTirePressIndSts_RRTirePressIndSts: accessed-variable=RRTirePressIndSts.RRTirePressIndSts
              REC_RRTireTempSts_RRTireTempSts: accessed-variable=RRTireTempSts.RRTireTempSts
              REC_RSDS_CTA_Actv_RSDS_CTA_Actv: accessed-variable=RSDS_CTA_Actv.RSDS_CTA_Actv
              REC_RSDS_ErrSts_RSDS_ErrSts: accessed-variable=RSDS_ErrSts.RSDS_ErrSts
              REC_RTurnLmpSts_R_Pbox_RTurnLmpSts_R_Pbox: accessed-variable=RTurnLmpSts_R_Pbox.RTurnLmpSts_R_Pbox
              REC_Rc_Fuel_Status_Fuel_Status: accessed-variable=Rc_Fuel_Status.Fuel_Status
              REC_Rc_Odo_RunCounter_RunCounter: accessed-variable=Rc_Odo_RunCounter.RunCounter
              REC_RemoteModSts_RemoteModSts: accessed-variable=RemoteModSts.RemoteModSts
              REC_SG_ACC4_ACC_FD2_SG_ACC4_ACC_FD2: accessed-variable=SG_ACC4_ACC_FD2.SG_ACC4_ACC_FD2
              REC_SG_IFC4_IFC_FD2_SG_IFC4_IFC_FD2: accessed-variable=SG_IFC4_IFC_FD2.SG_IFC4_IFC_FD2
              REC_SS_Enable_Lamp_SS_Enable_Lamp: accessed-variable=SS_Enable_Lamp.SS_Enable_Lamp
              REC_SS_Fault_Lamp_SS_Fault_Lamp: accessed-variable=SS_Fault_Lamp.SS_Fault_Lamp
              REC_TSRSpdLim_TSRSpdLim: accessed-variable=TSRSpdLim.TSRSpdLim
              REC_TSRSpdLimSts_TSRSpdLimSts: accessed-variable=TSRSpdLimSts.TSRSpdLimSts
              REC_TSRSpdLimWarn_TSRSpdLimWarn: accessed-variable=TSRSpdLimWarn.TSRSpdLimWarn
              REC_TSRSts_TSRSts: accessed-variable=TSRSts.TSRSts
              REC_TSRTrfcSignVal_TSRTrfcSignVal: accessed-variable=TSRTrfcSignVal.TSRTrfcSignVal
              REC_TgtRcprtnTrqSts_TgtRcprtnTrqSts: accessed-variable=TgtRcprtnTrqSts.TgtRcprtnTrqSts
              REC_TirePressSysFailrIndcn_TirePressSysFailrIndcn: accessed-variable=TirePressSysFailrIndcn.TirePressSysFailrIndcn
              REC_TrailerSts_TrailerSts: accessed-variable=TrailerSts.TrailerSts
              REC_TrunkSts_TrunkSts: accessed-variable=TrunkSts.TrunkSts
              REC_AutoLmpSwtSts_AutoLmpSwtSts: accessed-variable=AutoLmpSwtSts.AutoLmpSwtSts
              REC_HiPosnBrkLmpFailSts_HiPosnBrkLmpFailSts: accessed-variable=HiPosnBrkLmpFailSts.HiPosnBrkLmpFailSts
              REC_HoodSts_F_Pbox_HoodSts_F_Pbox: accessed-variable=HoodSts_F_Pbox.HoodSts_F_Pbox
              REC_LBrkLmpFailSts_LBrkLmpFailSts: accessed-variable=LBrkLmpFailSts.LBrkLmpFailSts
              REC_LicPlateLmpFailSts_LicPlateLmpFailSts: accessed-variable=LicPlateLmpFailSts.LicPlateLmpFailSts
              REC_RBrkLmpFailSts_RBrkLmpFailSts: accessed-variable=RBrkLmpFailSts.RBrkLmpFailSts
              REC_RvsLmpFailSts_RvsLmpFailSts: accessed-variable=RvsLmpFailSts.RvsLmpFailSts
              REC_SysPowerMod_SysPowerMod: accessed-variable=SysPowerMod.SysPowerMod
              REC_Rc_TachoInfo_EngRunSts: accessed-variable=Rc_TachoInfo.EngRunSts
              REC_Rc_TachoInfo_EngSpd: accessed-variable=Rc_TachoInfo.EngSpd
              REC_Rc_SpeedoInfo_IndicateSpeed: accessed-variable=Rc_SpeedoInfo.IndicateSpeed
              REC_Rc_SpeedoInfo_OverSpdWrnFlg: accessed-variable=Rc_SpeedoInfo.OverSpdWrnFlg
              REC_Rc_SpeedoInfo_RealSpeed: accessed-variable=Rc_SpeedoInfo.RealSpeed
              REC_Rc_SpeedoInfo_VehRunSts: accessed-variable=Rc_SpeedoInfo.VehRunSts
              REC_DCT3_TgtEngSpdIP_TgtEngSpdIP: accessed-variable=DCT3_TgtEngSpdIP.TgtEngSpdIP
              REC_DCT3_TgtEngSpdIPValid_TgtEngSpdIPValid: accessed-variable=DCT3_TgtEngSpdIPValid.TgtEngSpdIPValid
              REC_LRPosnLmpFailSts_LRPosnLmpFailSts: accessed-variable=LRPosnLmpFailSts.LRPosnLmpFailSts
              REC_RRPosnLmpFailSts_RRPosnLmpFailSts: accessed-variable=RRPosnLmpFailSts.RRPosnLmpFailSts
              REC_DiagLmpReq_DiagLmpReq: accessed-variable=DiagLmpReq.DiagLmpReq
              REC_DrowsyDrvDetWarn_DrowsyDrvDetWarn: accessed-variable=DrowsyDrvDetWarn.DrowsyDrvDetWarn
              REC_PowerRlyFault_PowerRlyFault: accessed-variable=PowerRlyFault.PowerRlyFault
              REC_RLSFailSts_RLSFailSts: accessed-variable=RLSFailSts.RLSFailSts
              REC_RotSteerWheel_RotSteerWheel: accessed-variable=RotSteerWheel.RotSteerWheel
              REC_WarnEngStrtNotMeet_WarnEngStrtNotMeet: accessed-variable=WarnEngStrtNotMeet.WarnEngStrtNotMeet
              REC_WarnKeyInCarWhenExit_WarnKeyInCarWhenExit: accessed-variable=WarnKeyInCarWhenExit.WarnKeyInCarWhenExit
              REC_WarnPowerNotInOffPosn_WarnPowerNotInOffPosn: accessed-variable=WarnPowerNotInOffPosn.WarnPowerNotInOffPosn
              REC_WarnVldKeyNotFound_WarnVldKeyNotFound: accessed-variable=WarnVldKeyNotFound.WarnVldKeyNotFound
              REC_ACAmbTemp_ACAmbTemp: accessed-variable=ACAmbTemp.ACAmbTemp
              REC_AccelPedalPosnVldty_AccelPedalPosnVldty: accessed-variable=AccelPedalPosnVldty.AccelPedalPosnVldty
              REC_AccelPedlPosnDiagc_AccelPedlPosnDiagc: accessed-variable=AccelPedlPosnDiagc.AccelPedlPosnDiagc
              REC_BMS_BattHeatRunaway_BMS_BattHeatRunaway: accessed-variable=BMS_BattHeatRunaway.BMS_BattHeatRunaway
              REC_BMS_BattSOC_BMS_BattSOC: accessed-variable=BMS_BattSOC.BMS_BattSOC
              REC_BMS_ChrgDurationTime_BMS_ChrgDurationTime: accessed-variable=BMS_ChrgDurationTime.BMS_ChrgDurationTime
              REC_BrkPedalSts_BCM_BrkPedalSts_BCM: accessed-variable=BrkPedalSts_BCM.BrkPedalSts_BCM
              REC_CCO_TgtVel_CCO_TgtVel: accessed-variable=CCO_TgtVel.CCO_TgtVel
              REC_CCO_Warn_CCO_Warn: accessed-variable=CCO_Warn.CCO_Warn
              REC_CouplingThermWarning_CouplingThermWarning: accessed-variable=CouplingThermWarning.CouplingThermWarning
              REC_DMSProc_DMSProc: accessed-variable=DMSProc.DMSProc
              REC_DMSProcResult_DMSProcResult: accessed-variable=DMSProcResult.DMSProcResult
              REC_DMSProcSts_DMSProcSts: accessed-variable=DMSProcSts.DMSProcSts
              REC_DistrctnLvl_DistrctnLvl: accessed-variable=DistrctnLvl.DistrctnLvl
              REC_DrowsnsLvl_DrowsnsLvl: accessed-variable=DrowsnsLvl.DrowsnsLvl
              REC_EMS_AuthenResult_EMS_AuthenResult: accessed-variable=EMS_AuthenResult.EMS_AuthenResult
              REC_EWP_Err_EWP_Err: accessed-variable=EWP_Err.EWP_Err
              REC_EspFuncOffSts_mode_EspFuncOffSts_mode: accessed-variable=EspFuncOffSts_mode.EspFuncOffSts_mode
              REC_FTIVFault_FTIVFault: accessed-variable=FTIVFault.FTIVFault
              REC_FuelTankCapWarning_FuelTankCapWarning: accessed-variable=FuelTankCapWarning.FuelTankCapWarning
              REC_GPF_Warning_GPF_Warning: accessed-variable=GPF_Warning.GPF_Warning
              REC_HCUImmoAuthRes_HCUImmoAuthRes: accessed-variable=HCUImmoAuthRes.HCUImmoAuthRes
              REC_HCU_ACLineDisconnect_HCU_ACLineDisconnect: accessed-variable=HCU_ACLineDisconnect.HCU_ACLineDisconnect
              REC_HCU_AvailPower_TM_HCU_AvailPower_TM: accessed-variable=HCU_AvailPower_TM.HCU_AvailPower_TM
              REC_HCU_BattLowHeatSts_HCU_BattLowHeatSts: accessed-variable=HCU_BattLowHeatSts.HCU_BattLowHeatSts
              REC_HCU_BattLowTemWarn_HCU_BattLowTemWarn: accessed-variable=HCU_BattLowTemWarn.HCU_BattLowTemWarn
              REC_HCU_ChargSts_HCU_ChargSts: accessed-variable=HCU_ChargSts.HCU_ChargSts
              REC_HCU_ChrgSysErr_{1..8}_HCU_ChrgSysErr_{1..8}: accessed-variable=HCU_ChrgSysErr_{1..8}.HCU_ChrgSysErr_{1..8}
              REC_HCU_DrvMod_HCU_DrvMod: accessed-variable=HCU_DrvMod.HCU_DrvMod
              REC_HCU_ECODrvHabit_Indcn_HCU_ECODrvHabit_Indcn: accessed-variable=HCU_ECODrvHabit_Indcn.HCU_ECODrvHabit_Indcn
              REC_HCU_EVContnsDistance_HCU_EVContnsDistance: accessed-variable=HCU_EVContnsDistance.HCU_EVContnsDistance
              REC_HCU_EVContnsDistanceVld_HCU_EVContnsDistanceVld: accessed-variable=HCU_EVContnsDistanceVld.HCU_EVContnsDistanceVld
              REC_HCU_EgyUsed_HCU_EgyUsed: accessed-variable=HCU_EgyUsed.HCU_EgyUsed
              REC_HCU_IntelBattTempMagSts_HCU_IntelBattTempMagSts: accessed-variable=HCU_IntelBattTempMagSts.HCU_IntelBattTempMagSts
              REC_HCU_RaceLaunchAvail_HCU_RaceLaunchAvail: accessed-variable=HCU_RaceLaunchAvail.HCU_RaceLaunchAvail
              REC_HCU_RaceLaunchSts_HCU_RaceLaunchSts: accessed-variable=HCU_RaceLaunchSts.HCU_RaceLaunchSts
              REC_HCU_RecupPwr_HCU_RecupPwr: accessed-variable=HCU_RecupPwr.HCU_RecupPwr
              REC_HCU_TotDrvReqPower_HCU_TotDrvReqPower: accessed-variable=HCU_TotDrvReqPower.HCU_TotDrvReqPower
              REC_HCU_WorkshopMode_HCU_WorkshopMode: accessed-variable=HCU_WorkshopMode.HCU_WorkshopMode
              REC_LHeadLmpFailSts_LHeadLmpFailSts: accessed-variable=LHeadLmpFailSts.LHeadLmpFailSts
              REC_LHiBeamFailSts_LHiBeamFailSts: accessed-variable=LHiBeamFailSts.LHiBeamFailSts
              REC_LLasHdLmpDiagSig_LLasHdLmpDiagSig: accessed-variable=LLasHdLmpDiagSig.LLasHdLmpDiagSig
              REC_LLowBeamFailSts_LLowBeamFailSts: accessed-variable=LLowBeamFailSts.LLowBeamFailSts
              REC_LasHdLmpSts_F_Pbox_LasHdLmpSts_F_Pbox: accessed-variable=LasHdLmpSts_F_Pbox.LasHdLmpSts_F_Pbox
              REC_OBC_ConnectSts_OBC_ConnectSts: accessed-variable=OBC_ConnectSts.OBC_ConnectSts
              REC_PressReliProgs_PressReliProgs: accessed-variable=PressReliProgs.PressReliProgs
              REC_RHeadLmpFailSts_RHeadLmpFailSts: accessed-variable=RHeadLmpFailSts.RHeadLmpFailSts
              REC_RHiBeamFailSts_RHiBeamFailSts: accessed-variable=RHiBeamFailSts.RHiBeamFailSts
              REC_RLasHdLmpDiagSig_RLasHdLmpDiagSig: accessed-variable=RLasHdLmpDiagSig.RLasHdLmpDiagSig
              REC_RLowBeamFailSts_RLowBeamFailSts: accessed-variable=RLowBeamFailSts.RLowBeamFailSts
              REC_RSDS_BrkgTrig_RSDS_BrkgTrig: accessed-variable=RSDS_BrkgTrig.RSDS_BrkgTrig
              REC_RSDS_RCW_Trigger_RSDS_RCW_Trigger: accessed-variable=RSDS_RCW_Trigger.RSDS_RCW_Trigger
              REC_RSDS_TrailerSts_RSDS_TrailerSts: accessed-variable=RSDS_TrailerSts.RSDS_TrailerSts
              REC_RearELDLckSts_RearELDLckSts: accessed-variable=RearELDLckSts.RearELDLckSts
              REC_VSG_HUTSoundResp_VSG_HUTSoundResp: accessed-variable=VSG_HUTSoundResp.VSG_HUTSoundResp
              REC_VSG_Sts_VSG_Sts: accessed-variable=VSG_Sts.VSG_Sts
              REC_WPC_FaultSts_WPC_FaultSts: accessed-variable=WPC_FaultSts.WPC_FaultSts
              REC_WPC_PhoneReminder_WPC_PhoneReminder: accessed-variable=WPC_PhoneReminder.WPC_PhoneReminder
              REC_ECM11_EngSpd_ForIP_EngSpd_ForIP: accessed-variable=ECM11_EngSpd_ForIP.EngSpd_ForIP
              REC_ECM1_EngSpdVldty_EngSpdVldty: accessed-variable=ECM1_EngSpdVldty.EngSpdVldty
              REC_HCU_AccelPedalPosn_Diag_HCU_AccelPedalPosn_Diag: accessed-variable=HCU_AccelPedalPosn_Diag.HCU_AccelPedalPosn_Diag
              REC_HCU_AccelPedalPosn_DiagValid_HCU_AccelPedalPosn_DiagValid: accessed-variable=HCU_AccelPedalPosn_DiagValid.HCU_AccelPedalPosn_DiagValid
              REC_HiBeamSts_F_Pbox_HiBeamSts_F_Pbox: accessed-variable=HiBeamSts_F_Pbox.HiBeamSts_F_Pbox
              REC_RFogLmpSts_R_Pbox_RFogLmpSts_R_Pbox: accessed-variable=RFogLmpSts_R_Pbox.RFogLmpSts_R_Pbox
              REC_RSDS_BliSts_RSDS_BliSts: accessed-variable=RSDS_BliSts.RSDS_BliSts
              REC_RSDS_LCAResp_RSDS_LCAResp: accessed-variable=RSDS_LCAResp.RSDS_LCAResp
              REC_rpSR_SWCNormal_SpeedoInfo_Element: accessed-variable=rpSR_SWCNormal_SpeedoInfo.Element
              REC_rpSR_SWCNormal_TachoInfo_Element: accessed-variable=rpSR_SWCNormal_TachoInfo.Element
              REC_rpSR_SWCNormal_OdoParament_Element: accessed-variable=rpSR_SWCNormal_OdoParament.Element
              REC_rpSR_SWCNormal_Fuel_Set_Module_Data_Element: accessed-variable=rpSR_SWCNormal_Fuel_Set_Module_Data.Element
              REC_rpSR_SWCNormal_TC_Module_Output_Data_Element: accessed-variable=rpSR_SWCNormal_TC_Module_Output_Data.Element
              REC_SG_IFC5_IFC_FD2_SG_IFC5_IFC_FD2: accessed-variable=SG_IFC5_IFC_FD2.SG_IFC5_IFC_FD2
              REC_RSDS_IPSoundReq_RSDS_IPSoundReq: accessed-variable=RSDS_IPSoundReq.RSDS_IPSoundReq
              REC_TSRSpdLimCfdc_TSRSpdLimCfdc: accessed-variable=TSRSpdLimCfdc.TSRSpdLimCfdc
              REC_PASWorkCmd_PASWorkCmd: accessed-variable=PASWorkCmd.PASWorkCmd
              REC_APS_FLSideSnsrFailSts_APS_FLSideSnsrFailSts: accessed-variable=APS_FLSideSnsrFailSts.APS_FLSideSnsrFailSts
              REC_APS_FRSideSnsrFailSts_APS_FRSideSnsrFailSts: accessed-variable=APS_FRSideSnsrFailSts.APS_FRSideSnsrFailSts
              REC_APS_RLSideSnsrFailSts_APS_RLSideSnsrFailSts: accessed-variable=APS_RLSideSnsrFailSts.APS_RLSideSnsrFailSts
              REC_APS_RRSideSnsrFailSts_APS_RRSideSnsrFailSts: accessed-variable=APS_RRSideSnsrFailSts.APS_RRSideSnsrFailSts
              REC_SDW_SoundIndcn_SDW_SoundIndcn: accessed-variable=SDW_SoundIndcn.SDW_SoundIndcn
              REC_SDWActiveSts_SDWActiveSts: accessed-variable=SDWActiveSts.SDWActiveSts
              REC_APS_WorkSts_APS_WorkSts: accessed-variable=APS_WorkSts.APS_WorkSts
              REC_APS_SysSoundIndcn_APS_SysSoundIndcn: accessed-variable=APS_SysSoundIndcn.APS_SysSoundIndcn
              REC_RPAS_SoundIndcn_FD_RPAS_SoundIndcn_FD: accessed-variable=RPAS_SoundIndcn_FD.RPAS_SoundIndcn_FD
              REC_RPAS_WorkSts_FD_RPAS_WorkSts_FD: accessed-variable=RPAS_WorkSts_FD.RPAS_WorkSts_FD
              REC_FLTirePress_FLTirePress: accessed-variable=FLTirePress.FLTirePress
              REC_FLTireTemp_FLTireTemp: accessed-variable=FLTireTemp.FLTireTemp
              REC_RLTirePress_RLTirePress: accessed-variable=RLTirePress.RLTirePress
              REC_RLTireTemp_RLTireTemp: accessed-variable=RLTireTemp.RLTireTemp
              REC_RRTirePress_RRTirePress: accessed-variable=RRTirePress.RRTirePress
              REC_RRTireTemp_RRTireTemp: accessed-variable=RRTireTemp.RRTireTemp
              REC_FRTirePress_FRTirePress: accessed-variable=FRTirePress.FRTirePress
              REC_FRTireTemp_FRTireTemp: accessed-variable=FRTireTemp.FRTireTemp
              REC_BMS_BattKeepTempSts_BMS_BattKeepTempSts: accessed-variable=BMS_BattKeepTempSts.BMS_BattKeepTempSts
              REC_BMS_IntelEngIdlChrgnSts_BMS_IntelEngIdlChrgnSts: accessed-variable=BMS_IntelEngIdlChrgnSts.BMS_IntelEngIdlChrgnSts
              REC_FPAS_SoundIndcn_FD_FPAS_SoundIndcn_FD: accessed-variable=FPAS_SoundIndcn_FD.FPAS_SoundIndcn_FD
              REC_FPAS_WorkSts_FD_FPAS_WorkSts_FD: accessed-variable=FPAS_WorkSts_FD.FPAS_WorkSts_FD
              REC_GentrWarnLmpSts_GentrWarnLmpSts: accessed-variable=GentrWarnLmpSts.GentrWarnLmpSts
              REC_TGS_LEVER_TGS_LEVER: accessed-variable=TGS_LEVER.TGS_LEVER
              REC_FuelConsumption_FuelConsumption: accessed-variable=FuelConsumption.FuelConsumption
              REC_CR_BliSts_CR_BliSts: accessed-variable=CR_BliSts.CR_BliSts
              REC_FCTA_B_FuncSts_FCTA_B_FuncSts: accessed-variable=FCTA_B_FuncSts.FCTA_B_FuncSts
              REC_FCTA_Warn_FCTA_Warn: accessed-variable=FCTA_Warn.FCTA_Warn
              REC_FCTBTrig_FCTBTrig: accessed-variable=FCTBTrig.FCTBTrig
              REC_SG_IFC3_IFC_FD2_SG_IFC3_IFC_FD2: accessed-variable=SG_IFC3_IFC_FD2.SG_IFC3_IFC_FD2
              REC_SG_ACC8_ACC_FD2_SG_ACC8_ACC_FD2: accessed-variable=SG_ACC8_ACC_FD2.SG_ACC8_ACC_FD2
              REC_rpSR_SWCNormal_DrvModStatusRecord_Element: accessed-variable=rpSR_SWCNormal_DrvModStatusRecord.Element
              REC_rpSR_SWCNormal_WarningStsOutput_Element: accessed-variable=rpSR_SWCNormal_WarningStsOutput.Element
              REC_SG_ACC3_ACC_FD2_SG_ACC3_ACC_FD2: accessed-variable=SG_ACC3_ACC_FD2.SG_ACC3_ACC_FD2
              REC_SafetyCanOutputViaNormal_Element: accessed-variable=SafetyCanOutputViaNormal.CheckSum_IP2
              REC_tiSR_Rte_Read_Sd_RTC_Data_SleepDateTime: accessed-variable=tiSR_Rte_Read_Sd_RTC_Data.SleepDateTime
              REC_tiSR_Rte_Read_Sd_RTC_Data_UtcTime: accessed-variable=tiSR_Rte_Read_Sd_RTC_Data.UtcTime
              REC_SafetyCanOutputViaNormal_IP_ABMWarnLmpFailrSts: accessed-variable=SafetyCanOutputViaNormal.IP_ABMWarnLmpFailrSts
              REC_SafetyCanOutputViaNormal_IP_ACCErr: accessed-variable=SafetyCanOutputViaNormal.IP_ACCErr
              REC_SafetyCanOutputViaNormal_IP_BattChrgLmpSts: accessed-variable=SafetyCanOutputViaNormal.IP_BattChrgLmpSts
              REC_SafetyCanOutputViaNormal_IP_DrvSeatBeltWarnLmpFailSts: accessed-variable=SafetyCanOutputViaNormal.IP_DrvSeatBeltWarnLmpFailSts
              REC_SafetyCanOutputViaNormal_IP_EngOilPressLowLmpSts: accessed-variable=SafetyCanOutputViaNormal.IP_EngOilPressLowLmpSts
              REC_SafetyCanOutputViaNormal_IP_Err: accessed-variable=SafetyCanOutputViaNormal.IP_Err
              REC_SafetyCanOutputViaNormal_IP_FuelLvlInfo: accessed-variable=SafetyCanOutputViaNormal.IP_FuelLvlInfo
              REC_SafetyCanOutputViaNormal_IP_FuelLvlLowLmpSts: accessed-variable=SafetyCanOutputViaNormal.IP_FuelLvlLowLmpSts
              REC_SafetyCanOutputViaNormal_IP_PassSeatBeltWarnLmpFailSts: accessed-variable=SafetyCanOutputViaNormal.IP_PassSeatBeltWarnLmpFailSts
              REC_SafetyCanOutputViaNormal_IP_VINcompr: accessed-variable=SafetyCanOutputViaNormal.IP_VINcompr
              REC_SafetyCanOutputViaNormal_IP_VehSpdUnit: accessed-variable=SafetyCanOutputViaNormal.IP_VehSpdUnit
              REC_SafetyCanOutputViaNormal_IP_VehTotDistance: accessed-variable=SafetyCanOutputViaNormal.IP_VehTotDistance
              REC_SafetyCanOutputViaNormal_IP_VehTotDistanceValid: accessed-variable=SafetyCanOutputViaNormal.IP_VehTotDistanceValid
              REC_SafetyCanOutputViaNormal_RollingCounter_IP2: accessed-variable=SafetyCanOutputViaNormal.RollingCounter_IP2
              REC_SafetyCanOutputViaNormal_dummy_HUT_IP2_0: accessed-variable=SafetyCanOutputViaNormal.dummy_HUT_IP2_0
              REC_EngClntTempVldty_EngClntTempVldty: accessed-variable=EngClntTempVldty.EngClntTempVldty
              REC_EngCoolantTemp_EngCoolantTemp: accessed-variable=EngCoolantTemp.EngCoolantTemp
              REC_SocReadyFlag_Element: accessed-variable=SocReadyFlag.Element
              REC_rpSR_SWCNormal_ChimeID_Element: accessed-variable=rpSR_SWCNormal_ChimeID.Element
              REC_SG_HC1_SG_HC1: accessed-variable=SG_HC1.SG_HC1
              REC_SG_ACC7_ACC_FD2_SG_ACC7_ACC_FD2: accessed-variable=SG_ACC7_ACC_FD2.SG_ACC7_ACC_FD2
              REC_rcSR_SWCNormal_BswM_Warm_Reset_Element: accessed-variable=rcSR_SWCNormal_BswM_Warm_Reset.Element
              REC_Cconfig_KindBuffers_400Bytes_CconfigKind_400Bytes: accessed-variable=Cconfig_KindBuffers_400Bytes.CconfigKind_400Bytes
              REC_T_Box_SysErrSts_T_Box_SysErrSts: accessed-variable=T_Box_SysErrSts.T_Box_SysErrSts
              REC_rpSR_SWCNormal_MenuSet_OverSpeedEnable_Element: accessed-variable=rpSR_SWCNormal_MenuSet_OverSpeedEnable.Element
              REC_rpSR_SWCNormal_MenuSet_OverSpeedLimit_Element: accessed-variable=rpSR_SWCNormal_MenuSet_OverSpeedLimit.Element
              REC_BSD_LCA_warningReqRight_BSD_LCA_warningReqRight: accessed-variable=BSD_LCA_warningReqRight.BSD_LCA_warningReqRight
              REC_BSD_LCA_warningReqleft_BSD_LCA_warningReqleft: accessed-variable=BSD_LCA_warningReqleft.BSD_LCA_warningReqleft
              REC_DOW_warningReqRight_DOW_warningReqRight: accessed-variable=DOW_warningReqRight.DOW_warningReqRight
              REC_DOW_warningReqleft_DOW_warningReqleft: accessed-variable=DOW_warningReqleft.DOW_warningReqleft
              REC_RCTA_warningReqLeft_RCTA_warningReqLeft: accessed-variable=RCTA_warningReqLeft.RCTA_warningReqLeft
              REC_RCTA_warningReqRight_RCTA_warningReqRight: accessed-variable=RCTA_warningReqRight.RCTA_warningReqRight
              REC_SG_AEB2_AEB_FD2_SG_AEB2_AEB_FD2: accessed-variable=SG_AEB2_AEB_FD2.SG_AEB2_AEB_FD2
              REC_SG_AEB3_AEB_FD2_SG_AEB3_AEB_FD2: accessed-variable=SG_AEB3_AEB_FD2.SG_AEB3_AEB_FD2
              REC_SG_EPS1_FD1_SG_EPS1_FD1: accessed-variable=SG_EPS1_FD1.SG_EPS1_FD1
              REC_SG_ESP2_ESP_FD2_SG_ESP2_ESP_FD2: accessed-variable=SG_ESP2_ESP_FD2.SG_ESP2_ESP_FD2
              REC_SG_ABM1_SG_ABM1: accessed-variable=SG_ABM1.SG_ABM1
              REC_SG_ABS3_ESP_FD2_SG_ABS3_ESP_FD2: accessed-variable=SG_ABS3_ESP_FD2.SG_ABS3_ESP_FD2
              REC_SG_DCT7_SG_DCT7: accessed-variable=SG_DCT7.SG_DCT7
              REC_SG_EPB1_SG_EPB1: accessed-variable=SG_EPB1.SG_EPB1
              REC_SG_EPS1_SG_EPS1: accessed-variable=SG_EPS1.SG_EPS1
              REC_SG_ESP2_SG_ESP2: accessed-variable=SG_ESP2.SG_ESP2
              REC_SG_ABS3_SG_ABS3: accessed-variable=SG_ABS3.SG_ABS3
              REC_rpSR_SWCNormal_MenuSetData_Element: accessed-variable=rpSR_SWCNormal_MenuSetData.Element
              REC_tiSR_SWC_TT_SelfCheck_Element: accessed-variable=tiSR_SWC_TT_SelfCheck.Element
              REC_rpSR_SWCNormal_S2M_Information_SpeedValue: accessed-variable=rpSR_SWCNormal_S2M_Information.SpeedValue
              REC_rpSR_SWCNormal_S2M_Information_TachoValue: accessed-variable=rpSR_SWCNormal_S2M_Information.TachoValue
              REC_SG_IFC6_IFC_FD2_SG_IFC6_IFC_FD2: accessed-variable=SG_IFC6_IFC_FD2.SG_IFC6_IFC_FD2
              REC_SG_HCU_PT4_SG_HCU_PT4: accessed-variable=SG_HCU_PT4.SG_HCU_PT4
              REC_SG_HCU_PT7_SG_HCU_PT7: accessed-variable=SG_HCU_PT7.SG_HCU_PT7
              REC_SG_BMS4_SG_BMS4: accessed-variable=SG_BMS4.SG_BMS4
              REC_SG_DHT_FD1_SG_DHT_FD1: accessed-variable=SG_DHT_FD1.SG_DHT_FD1
              REC_SG_HCU_HP5_SG_HCU_HP5: accessed-variable=SG_HCU_HP5.SG_HCU_HP5
              REC_FPAS_SoundIndcn_FPAS_SoundIndcn_0x26D: accessed-variable=FPAS_SoundIndcn.FPAS_SoundIndcn
              REC_FPAS_WorkSts_FPAS_WorkSts_0x26D: accessed-variable=FPAS_WorkSts.FPAS_WorkSts
              REC_RPAS_SoundIndcn_RPAS_SoundIndcn_0x26E: accessed-variable=RPAS_SoundIndcn.RPAS_SoundIndcn
              REC_RPAS_WorkSts_RPAS_WorkSts_0x26E: accessed-variable=RPAS_WorkSts.RPAS_WorkSts
              REC_LADBstatus_LADBstatus: accessed-variable=LADBstatus.LADBstatus
              REC_LHiBeamSts_LHiBeamSts: accessed-variable=LHiBeamSts.LHiBeamSts
              REC_RADBstatus_RADBstatus: accessed-variable=RADBstatus.RADBstatus
              REC_RHiBeamSts_RHiBeamSts: accessed-variable=RHiBeamSts.RHiBeamSts
              REC_rpSR_SWCNormal_EnergyInfoId_Data: accessed-variable=rpSR_SWCNormal_EnergyInfoId.Data
              REC_rpSR_SWCNormal_DiagMonitorReInitFlag_ChangeCounter: accessed-variable=rpSR_SWCNormal_DiagMonitorReInitFlag.ChangeCounter
              REC_Vconfig_GetKindBuffers_Kind600Bytes: accessed-variable=Vconfig_GetKindBuffers.AllKinds
          data-send-points:
            40 x access:
              SEND_Sd_Cluster_Shutdown_Status_Element: accessed-variable=Sd_Cluster_Shutdown_Status.Element
              SEND_Sd_SpeedoInfo_IndicateSpeed: accessed-variable=Sd_SpeedoInfo.IndicateSpeed
              SEND_Sd_SpeedoInfo_OverSpdWrnFlg: accessed-variable=Sd_SpeedoInfo.OverSpdWrnFlg
              SEND_Sd_SpeedoInfo_RealSpeed: accessed-variable=Sd_SpeedoInfo.RealSpeed
              SEND_Sd_SpeedoInfo_VehRunSts: accessed-variable=Sd_SpeedoInfo.VehRunSts
              SEND_Sd_TachoInfo_EngRunSts: accessed-variable=Sd_TachoInfo.EngRunSts
              SEND_Sd_TachoInfo_EngSpd: accessed-variable=Sd_TachoInfo.EngSpd
              SEND_ppSR_SWCNormal_DrvModStatusRecord_Element: accessed-variable=ppSR_SWCNormal_DrvModStatusRecord.Element
              SEND_ppSR_SWCNormal_WarningStsOutput_Element: accessed-variable=ppSR_SWCNormal_WarningStsOutput.Element
              SEND_ppSR_SWCNormal_ChimeID_Element: accessed-variable=ppSR_SWCNormal_ChimeID.Element
              SEND_CanOutputViaGateway_CheckSum_IP2: accessed-variable=Sd_CanOutputViaGateway.CheckSum_IP2
              SEND_CanOutputViaGateway_IP_ABMWarnLmpFailrSts: accessed-variable=Sd_CanOutputViaGateway.IP_ABMWarnLmpFailrSts
              SEND_CanOutputViaGateway_IP_ACCErr: accessed-variable=Sd_CanOutputViaGateway.IP_ACCErr
              SEND_CanOutputViaGateway_IP_BattChrgLmpSts: accessed-variable=Sd_CanOutputViaGateway.IP_BattChrgLmpSts
              SEND_CanOutputViaGateway_IP_DrvSeatBeltWarnLmpFailSts: accessed-variable=Sd_CanOutputViaGateway.IP_DrvSeatBeltWarnLmpFailSts
              SEND_CanOutputViaGateway_IP_EngOilPressLowLmpSts: accessed-variable=Sd_CanOutputViaGateway.IP_EngOilPressLowLmpSts
              SEND_CanOutputViaGateway_IP_Err: accessed-variable=Sd_CanOutputViaGateway.IP_Err
              SEND_CanOutputViaGateway_IP_FuelLvlInfo: accessed-variable=Sd_CanOutputViaGateway.IP_FuelLvlInfo
              SEND_CanOutputViaGateway_IP_FuelLvlLowLmpSts: accessed-variable=Sd_CanOutputViaGateway.IP_FuelLvlLowLmpSts
              SEND_CanOutputViaGateway_IP_PassSeatBeltWarnLmpFailSts: accessed-variable=Sd_CanOutputViaGateway.IP_PassSeatBeltWarnLmpFailSts
              SEND_CanOutputViaGateway_IP_VINcompr: accessed-variable=Sd_CanOutputViaGateway.IP_VINcompr
              SEND_CanOutputViaGateway_IP_VehSpdUnit: accessed-variable=Sd_CanOutputViaGateway.IP_VehSpdUnit
              SEND_CanOutputViaGateway_IP_VehTotDistance: accessed-variable=Sd_CanOutputViaGateway.IP_VehTotDistance
              SEND_CanOutputViaGateway_IP_VehTotDistanceValid: accessed-variable=Sd_CanOutputViaGateway.IP_VehTotDistanceValid
              SEND_CanOutputViaGateway_RollingCounter_IP2: accessed-variable=Sd_CanOutputViaGateway.RollingCounter_IP2
              SEND_CanOutputViaGateway_dummy_HUT_IP2_0: accessed-variable=Sd_CanOutputViaGateway.dummy_HUT_IP2_0
              SEND_Sd_CanOutputViaGateway_IP_AvgFuelCons: accessed-variable=Sd_CanOutputViaGateway.IP_AvgFuelCons
              SEND_Sd_CanOutputViaGateway_IP_CurrTheme: accessed-variable=Sd_CanOutputViaGateway.IP_CurrTheme
              SEND_Sd_CanOutputViaGateway_IP_FuelAuxTankR: accessed-variable=Sd_CanOutputViaGateway.IP_FuelAuxTankR
              SEND_Sd_CanOutputViaGateway_IP_FuelMainTankR: accessed-variable=Sd_CanOutputViaGateway.IP_FuelMainTankR
              SEND_Sd_CanOutputViaGateway_IP_InstFuelCons: accessed-variable=Sd_CanOutputViaGateway.IP_InstFuelCons
              SEND_Sd_CanOutputViaGateway_IP_InstFuelConsUnit: accessed-variable=Sd_CanOutputViaGateway.IP_InstFuelConsUnit
              SEND_Sd_CanOutputViaGateway_IP_LagueSet: accessed-variable=Sd_CanOutputViaGateway.IP_LagueSet
              SEND_Sd_CanOutputViaGateway_IP_RemainDistance: accessed-variable=Sd_CanOutputViaGateway.IP_RemainDistance
              SEND_Sd_CanOutputViaGateway_IP_VehSpdDisp: accessed-variable=Sd_CanOutputViaGateway.IP_VehSpdDisp
              SEND_Sd_CanOutputViaGateway_IP_VelSpdDisp_Mile: accessed-variable=Sd_CanOutputViaGateway.IP_VelSpdDisp_Mile
              SEND_ppSR_SWCNormal_MenuSet_OverSpeedEnable_Element: accessed-variable=ppSR_SWCNormal_MenuSet_OverSpeedEnable.Element
              SEND_ppSR_SWCNormal_MenuSet_OverSpeedLimit_Element: accessed-variable=ppSR_SWCNormal_MenuSet_OverSpeedLimit.Element
              SEND_ppSR_SWCNormal_MenuSetData_Element: accessed-variable=ppSR_SWCNormal_MenuSetData.Element
              SEND_ppSR_SWCNormal_TC_NE_ChargStsOutput_Element: accessed-variable=ppSR_SWCNormal_TC_NE_ChargStsOutput.Element
          78 x sync call:
            SC_IPC_Send_IPC_Send: operation=IPC_Send.IPC_Send
            SC_NvMService_AC3_SRBS_Defs_NvBlockNeed_Block_MaintainOdo_EraseBlock: operation=NvMService_AC3_SRBS_Defs_NvBlockNeed_Block_MaintainOdo.EraseBlock
            SC_NvMService_AC3_SRBS_Defs_NvBlockNeed_Block_MaintainOdo_GetErrorStatus: operation=NvMService_AC3_SRBS_Defs_NvBlockNeed_Block_MaintainOdo.GetErrorStatus
            SC_NvMService_AC3_SRBS_Defs_NvBlockNeed_Block_MaintainOdo_InvalidateNvBlock: operation=NvMService_AC3_SRBS_Defs_NvBlockNeed_Block_MaintainOdo.InvalidateNvBlock
            SC_NvMService_AC3_SRBS_Defs_NvBlockNeed_Block_MaintainOdo_ReadBlock: operation=NvMService_AC3_SRBS_Defs_NvBlockNeed_Block_MaintainOdo.ReadBlock
            SC_NvMService_AC3_SRBS_Defs_NvBlockNeed_Block_MaintainOdo_RestoreBlockDefaults: operation=NvMService_AC3_SRBS_Defs_NvBlockNeed_Block_MaintainOdo.RestoreBlockDefaults
            SC_NvMService_AC3_SRBS_Defs_NvBlockNeed_Block_MaintainOdo_SetRamBlockStatus: operation=NvMService_AC3_SRBS_Defs_NvBlockNeed_Block_MaintainOdo.SetRamBlockStatus
            SC_NvMService_AC3_SRBS_Defs_NvBlockNeed_Block_MaintainOdo_WriteBlock: operation=NvMService_AC3_SRBS_Defs_NvBlockNeed_Block_MaintainOdo.WriteBlock
            SC_NvMService_AC3_SRBS_Defs_NvBlockNeed_Block_ODO_1_EraseBlock: operation=NvMService_AC3_SRBS_Defs_NvBlockNeed_Block_ODO_1.EraseBlock
            SC_NvMService_AC3_SRBS_Defs_NvBlockNeed_Block_ODO_1_GetErrorStatus: operation=NvMService_AC3_SRBS_Defs_NvBlockNeed_Block_ODO_1.GetErrorStatus
            SC_NvMService_AC3_SRBS_Defs_NvBlockNeed_Block_ODO_1_InvalidateNvBlock: operation=NvMService_AC3_SRBS_Defs_NvBlockNeed_Block_ODO_1.InvalidateNvBlock
            SC_NvMService_AC3_SRBS_Defs_NvBlockNeed_Block_ODO_1_ReadBlock: operation=NvMService_AC3_SRBS_Defs_NvBlockNeed_Block_ODO_1.ReadBlock
            SC_NvMService_AC3_SRBS_Defs_NvBlockNeed_Block_ODO_1_RestoreBlockDefaults: operation=NvMService_AC3_SRBS_Defs_NvBlockNeed_Block_ODO_1.RestoreBlockDefaults
            SC_NvMService_AC3_SRBS_Defs_NvBlockNeed_Block_ODO_1_SetRamBlockStatus: operation=NvMService_AC3_SRBS_Defs_NvBlockNeed_Block_ODO_1.SetRamBlockStatus
            SC_NvMService_AC3_SRBS_Defs_NvBlockNeed_Block_ODO_1_WriteBlock: operation=NvMService_AC3_SRBS_Defs_NvBlockNeed_Block_ODO_1.WriteBlock
            SC_NvMService_AC3_SRBS_Defs_NvBlockNeed_Block_ODO_2_EraseBlock: operation=NvMService_AC3_SRBS_Defs_NvBlockNeed_Block_ODO_2.EraseBlock
            SC_NvMService_AC3_SRBS_Defs_NvBlockNeed_Block_ODO_2_GetErrorStatus: operation=NvMService_AC3_SRBS_Defs_NvBlockNeed_Block_ODO_2.GetErrorStatus
            SC_NvMService_AC3_SRBS_Defs_NvBlockNeed_Block_ODO_2_InvalidateNvBlock: operation=NvMService_AC3_SRBS_Defs_NvBlockNeed_Block_ODO_2.InvalidateNvBlock
            SC_NvMService_AC3_SRBS_Defs_NvBlockNeed_Block_ODO_2_ReadBlock: operation=NvMService_AC3_SRBS_Defs_NvBlockNeed_Block_ODO_2.ReadBlock
            SC_NvMService_AC3_SRBS_Defs_NvBlockNeed_Block_ODO_2_RestoreBlockDefaults: operation=NvMService_AC3_SRBS_Defs_NvBlockNeed_Block_ODO_2.RestoreBlockDefaults
            SC_NvMService_AC3_SRBS_Defs_NvBlockNeed_Block_ODO_2_SetRamBlockStatus: operation=NvMService_AC3_SRBS_Defs_NvBlockNeed_Block_ODO_2.SetRamBlockStatus
            SC_NvMService_AC3_SRBS_Defs_NvBlockNeed_Block_ODO_2_WriteBlock: operation=NvMService_AC3_SRBS_Defs_NvBlockNeed_Block_ODO_2.WriteBlock
            SC_NvMService_AC3_SRBS_Defs_NvBlockNeed_Block_ODO_3_EraseBlock: operation=NvMService_AC3_SRBS_Defs_NvBlockNeed_Block_ODO_3.EraseBlock
            SC_NvMService_AC3_SRBS_Defs_NvBlockNeed_Block_ODO_3_GetErrorStatus: operation=NvMService_AC3_SRBS_Defs_NvBlockNeed_Block_ODO_3.GetErrorStatus
            SC_NvMService_AC3_SRBS_Defs_NvBlockNeed_Block_ODO_3_InvalidateNvBlock: operation=NvMService_AC3_SRBS_Defs_NvBlockNeed_Block_ODO_3.InvalidateNvBlock
            SC_NvMService_AC3_SRBS_Defs_NvBlockNeed_Block_ODO_3_ReadBlock: operation=NvMService_AC3_SRBS_Defs_NvBlockNeed_Block_ODO_3.ReadBlock
            SC_NvMService_AC3_SRBS_Defs_NvBlockNeed_Block_ODO_3_RestoreBlockDefaults: operation=NvMService_AC3_SRBS_Defs_NvBlockNeed_Block_ODO_3.RestoreBlockDefaults
            SC_NvMService_AC3_SRBS_Defs_NvBlockNeed_Block_ODO_3_SetRamBlockStatus: operation=NvMService_AC3_SRBS_Defs_NvBlockNeed_Block_ODO_3.SetRamBlockStatus
            SC_NvMService_AC3_SRBS_Defs_NvBlockNeed_Block_ODO_3_WriteBlock: operation=NvMService_AC3_SRBS_Defs_NvBlockNeed_Block_ODO_3.WriteBlock
            SC_NvMService_AC3_SRBS_Defs_NvBlockNeed_Block_ODO_4_EraseBlock: operation=NvMService_AC3_SRBS_Defs_NvBlockNeed_Block_ODO_4.EraseBlock
            SC_NvMService_AC3_SRBS_Defs_NvBlockNeed_Block_ODO_4_GetErrorStatus: operation=NvMService_AC3_SRBS_Defs_NvBlockNeed_Block_ODO_4.GetErrorStatus
            SC_NvMService_AC3_SRBS_Defs_NvBlockNeed_Block_ODO_4_InvalidateNvBlock: operation=NvMService_AC3_SRBS_Defs_NvBlockNeed_Block_ODO_4.InvalidateNvBlock
            SC_NvMService_AC3_SRBS_Defs_NvBlockNeed_Block_ODO_4_ReadBlock: operation=NvMService_AC3_SRBS_Defs_NvBlockNeed_Block_ODO_4.ReadBlock
            SC_NvMService_AC3_SRBS_Defs_NvBlockNeed_Block_ODO_4_RestoreBlockDefaults: operation=NvMService_AC3_SRBS_Defs_NvBlockNeed_Block_ODO_4.RestoreBlockDefaults
            SC_NvMService_AC3_SRBS_Defs_NvBlockNeed_Block_ODO_4_SetRamBlockStatus: operation=NvMService_AC3_SRBS_Defs_NvBlockNeed_Block_ODO_4.SetRamBlockStatus
            SC_NvMService_AC3_SRBS_Defs_NvBlockNeed_Block_ODO_4_WriteBlock: operation=NvMService_AC3_SRBS_Defs_NvBlockNeed_Block_ODO_4.WriteBlock
            SC_NvMService_AC3_SRBS_Defs_NvBlockNeed_Block_ODO_5_EraseBlock: operation=NvMService_AC3_SRBS_Defs_NvBlockNeed_Block_ODO_5.EraseBlock
            SC_NvMService_AC3_SRBS_Defs_NvBlockNeed_Block_ODO_5_GetErrorStatus: operation=NvMService_AC3_SRBS_Defs_NvBlockNeed_Block_ODO_5.GetErrorStatus
            SC_NvMService_AC3_SRBS_Defs_NvBlockNeed_Block_ODO_5_InvalidateNvBlock: operation=NvMService_AC3_SRBS_Defs_NvBlockNeed_Block_ODO_5.InvalidateNvBlock
            SC_NvMService_AC3_SRBS_Defs_NvBlockNeed_Block_ODO_5_ReadBlock: operation=NvMService_AC3_SRBS_Defs_NvBlockNeed_Block_ODO_5.ReadBlock
            SC_NvMService_AC3_SRBS_Defs_NvBlockNeed_Block_ODO_5_RestoreBlockDefaults: operation=NvMService_AC3_SRBS_Defs_NvBlockNeed_Block_ODO_5.RestoreBlockDefaults
            SC_NvMService_AC3_SRBS_Defs_NvBlockNeed_Block_ODO_5_SetRamBlockStatus: operation=NvMService_AC3_SRBS_Defs_NvBlockNeed_Block_ODO_5.SetRamBlockStatus
            SC_NvMService_AC3_SRBS_Defs_NvBlockNeed_Block_ODO_5_WriteBlock: operation=NvMService_AC3_SRBS_Defs_NvBlockNeed_Block_ODO_5.WriteBlock
            SC_NvMService_AC3_SRBS_Defs_NvBlockNeed_Block_Trip_EraseBlock: operation=NvMService_AC3_SRBS_Defs_NvBlockNeed_Block_Trip.EraseBlock
            SC_NvMService_AC3_SRBS_Defs_NvBlockNeed_Block_Trip_GetErrorStatus: operation=NvMService_AC3_SRBS_Defs_NvBlockNeed_Block_Trip.GetErrorStatus
            SC_NvMService_AC3_SRBS_Defs_NvBlockNeed_Block_Trip_InvalidateNvBlock: operation=NvMService_AC3_SRBS_Defs_NvBlockNeed_Block_Trip.InvalidateNvBlock
            SC_NvMService_AC3_SRBS_Defs_NvBlockNeed_Block_Trip_ReadBlock: operation=NvMService_AC3_SRBS_Defs_NvBlockNeed_Block_Trip.ReadBlock
            SC_NvMService_AC3_SRBS_Defs_NvBlockNeed_Block_Trip_RestoreBlockDefaults: operation=NvMService_AC3_SRBS_Defs_NvBlockNeed_Block_Trip.RestoreBlockDefaults
            SC_NvMService_AC3_SRBS_Defs_NvBlockNeed_Block_Trip_SetRamBlockStatus: operation=NvMService_AC3_SRBS_Defs_NvBlockNeed_Block_Trip.SetRamBlockStatus
            SC_NvMService_AC3_SRBS_Defs_NvBlockNeed_Block_Trip_WriteBlock: operation=NvMService_AC3_SRBS_Defs_NvBlockNeed_Block_Trip.WriteBlock
            SC_Os_Service_GetCounterValue: operation=Os_Service.GetCounterValue
            SC_Os_Service_GetElapsedValue: operation=Os_Service.GetElapsedValue
            SC_rpCS_SWCNormal_Reset_TC_Module_Data_WriteData: operation=rpCS_SWCNormal_Reset_TC_Module_Data.WriteData
            SC_rpCS_SWCNormal_DM_API_vGetDrvModTTStatus_Operation: operation=rpCS_SWCNormal_DM_API_vGetDrvModTTStatus.Operation
            SC_rpCS_SWCNormal_DM_API_vGetDrvModWarningStatus_Operation: operation=rpCS_SWCNormal_DM_API_vGetDrvModWarningStatus.Operation
            SC_VConfig_GetKindConfig_Operation_VConfig_GetKindConfig: operation=VConfig_GetKindConfig.Operation_VConfig_GetKindConfig
            SC_VConfig_GetUpdateTick_OperationVConfig_GetUpdateTick: operation=VConfig_GetUpdateTick.OperationVConfig_GetUpdateTick
            SC_IRTC_Service_UTC2PerpetualCalendar: operation=IRTC_Service.UTC2PerpetualCalendar
            SC_ppCS_SWCNormal_ChimeCallback_Operation: operation=ppCS_SWCNormal_ChimeCallback.Operation
            SC_ppCS_SWCNormal_TTCallback_Operation: operation=ppCS_SWCNormal_TTCallback.Operation
            SC_ppCS_SWCNormal_WrnCallback_Operation: operation=ppCS_SWCNormal_WrnCallback.Operation
            SC_CsmDecrypt_CsmPrimitives_AES128_Decrypt_CancelJob: operation=CsmDecrypt_CsmPrimitives_AES128_Decrypt.CancelJob
            SC_CsmDecrypt_CsmPrimitives_AES128_Decrypt_Decrypt: operation=CsmDecrypt_CsmPrimitives_AES128_Decrypt.Decrypt
            SC_CsmEncrypt_CsmPrimitives_AES128_Encrypt_CancelJob: operation=CsmEncrypt_CsmPrimitives_AES128_Encrypt.CancelJob
            SC_CsmEncrypt_CsmPrimitives_AES128_Encrypt_Encrypt: operation=CsmEncrypt_CsmPrimitives_AES128_Encrypt.Encrypt
            SC_HsmKeyM_GetCmacKey: operation=HsmKeyM.GetCmacKey
            SC_HsmKeyM_GetCmacKeyState: operation=HsmKeyM.GetCmacKeyState
            SC_HsmKeyM_SetCmacKey: operation=HsmKeyM.SetCmacKey
            SC_Hsm_Port_TrngGenerate: operation=Hsm_Port.TrngGenerate
            SC_HsmKeyM_GetAes128Key: operation=HsmKeyM.GetAes128Key
            SC_HsmKeyM_SetAes128Key: operation=HsmKeyM.SetAes128Key
            SC_IoHwAb_Interface_GetPin: operation=IoHwAb_Interface.GetPin
            SC_IoHwAb_Interface_GetVoltage: operation=IoHwAb_Interface.GetVoltage
            SC_rpCS_SWCNormal_SensorAorB_Status_Operation: operation=rpCS_SWCNormal_SensorAorB_Status.Operation
            SC_rpCS_SWCNormal_ComEx_GetRxE2EStatus: operation=rpCS_SWCNormal_ComEx.GetRxE2EStatus
            SC_rpCS_SWCNormal_ComEx_ReceiveSignal: operation=rpCS_SWCNormal_ComEx.ReceiveSignal
            SC_rpCS_SWCNormal_ComEx_SendSignal: operation=rpCS_SWCNormal_ComEx.SendSignal
            SC_IRTC_Service_GetUTCTimeInMillis: operation=IRTC_Service.GetUTCTimeInMillis
        Common_Normal_List_Deinit
        Common_Normal_List_Int
        Common_Normal_10msMainFunction_  # OffSet:8ms
        Common_Normal_20msMainFunction_  # OffSet:14ms
          17 x sync call:
            SC_NvMService_AC3_SRBS_Defs_NvBlockNeed_Block_TC_Config_Data_EraseBlock: operation=NvMService_AC3_SRBS_Defs_NvBlockNeed_Block_TC_Config_Data.EraseBlock
            SC_NvMService_AC3_SRBS_Defs_NvBlockNeed_Block_TC_Config_Data_GetErrorStatus: operation=NvMService_AC3_SRBS_Defs_NvBlockNeed_Block_TC_Config_Data.GetErrorStatus
            SC_NvMService_AC3_SRBS_Defs_NvBlockNeed_Block_TC_Config_Data_InvalidateNvBlock: operation=NvMService_AC3_SRBS_Defs_NvBlockNeed_Block_TC_Config_Data.InvalidateNvBlock
            SC_NvMService_AC3_SRBS_Defs_NvBlockNeed_Block_TC_Config_Data_ReadBlock: operation=NvMService_AC3_SRBS_Defs_NvBlockNeed_Block_TC_Config_Data.ReadBlock
            SC_NvMService_AC3_SRBS_Defs_NvBlockNeed_Block_TC_Config_Data_RestoreBlockDefaults: operation=NvMService_AC3_SRBS_Defs_NvBlockNeed_Block_TC_Config_Data.RestoreBlockDefaults
            SC_NvMService_AC3_SRBS_Defs_NvBlockNeed_Block_TC_Config_Data_SetRamBlockStatus: operation=NvMService_AC3_SRBS_Defs_NvBlockNeed_Block_TC_Config_Data.SetRamBlockStatus
            SC_NvMService_AC3_SRBS_Defs_NvBlockNeed_Block_TC_Config_Data_WriteBlock: operation=NvMService_AC3_SRBS_Defs_NvBlockNeed_Block_TC_Config_Data.WriteBlock
            SC_NvMService_AC3_SRBS_Defs_NvBlockNeed_Block_TC_Data_EraseBlock: operation=NvMService_AC3_SRBS_Defs_NvBlockNeed_Block_TC_Data.EraseBlock
            SC_NvMService_AC3_SRBS_Defs_NvBlockNeed_Block_TC_Data_GetErrorStatus: operation=NvMService_AC3_SRBS_Defs_NvBlockNeed_Block_TC_Data.GetErrorStatus
            SC_NvMService_AC3_SRBS_Defs_NvBlockNeed_Block_TC_Data_InvalidateNvBlock: operation=NvMService_AC3_SRBS_Defs_NvBlockNeed_Block_TC_Data.InvalidateNvBlock
            SC_NvMService_AC3_SRBS_Defs_NvBlockNeed_Block_TC_Data_ReadBlock: operation=NvMService_AC3_SRBS_Defs_NvBlockNeed_Block_TC_Data.ReadBlock
            SC_NvMService_AC3_SRBS_Defs_NvBlockNeed_Block_TC_Data_RestoreBlockDefaults: operation=NvMService_AC3_SRBS_Defs_NvBlockNeed_Block_TC_Data.RestoreBlockDefaults
            SC_NvMService_AC3_SRBS_Defs_NvBlockNeed_Block_TC_Data_SetRamBlockStatus: operation=NvMService_AC3_SRBS_Defs_NvBlockNeed_Block_TC_Data.SetRamBlockStatus
            SC_NvMService_AC3_SRBS_Defs_NvBlockNeed_Block_TC_Data_WriteBlock: operation=NvMService_AC3_SRBS_Defs_NvBlockNeed_Block_TC_Data.WriteBlock
            SC_CanFrameCounter_Can_ABS3_Counter: operation=CanFrameCounter.Can_ABS3_Counter
            SC_CanFrameCounter_Can_ECM2_Counter: operation=CanFrameCounter.Can_ECM2_Counter
            SC_CanFrameCounter_Can_ESP_FD2_Counter: operation=CanFrameCounter.Can_ESP_FD2_Counter
        Common_Normal_20msMainFunction_B  # OffSet:17ms
          4 x sync call:
            SC_DiagnosticMonitor_Fuel_Sensor1_ShortToBAT_SetEventStatus: operation=DiagnosticMonitor_Fuel_Sensor1_ShortToBAT.SetEventStatus
            SC_DiagnosticMonitor_Fuel_Sensor1_ShortToGND_SetEventStatus: operation=DiagnosticMonitor_Fuel_Sensor1_ShortToGND.SetEventStatus
            SC_DiagnosticMonitor_Fuel_Sensor2_ShortToBAT_SetEventStatus: operation=DiagnosticMonitor_Fuel_Sensor2_ShortToBAT.SetEventStatus
            SC_DiagnosticMonitor_Fuel_Sensor2_ShortToGND_SetEventStatus: operation=DiagnosticMonitor_Fuel_Sensor2_ShortToGND.SetEventStatus
        Common_Normal_100msMainFunction_  # OffSet:19ms
          data-receive-point-by-arguments:
            access REC_tiSR_VIN_Element: accessed-variable=tiSR_VIN.Element
        DM_API_vGetDrvModWarningStatus
        DM_API_vGetDrvModTTStatus
        RTE_TC_API_Set_TC_Module_Reset_Data
        NvMNotifyJobFinished_NvBlockNeed_Block_TC_Config_Data_JobFinished
        NvMNotifyJobFinished_NvBlockNeed_Block_TC_Data_JobFinished
        EOL_ReadDID0xFDD8_EOL_GetReadHardInputForCluster
        RTE_Odo_Api_ParamentSetFunction
        svCS_SWCNormal_TTCallback_Operation
        svCS_SWCNormal_ChimeCallback_Operation
        svCS_SWCNormal_WrnCallback_Operation
        svCS_SWCNormal_ReceiveMenuSetting_Callback
        svCS_SWCNormal_HMIResetTC_Callback
        Common_Normal_Nomal2Standby_Callbcak: can-be-invoked-concurrently=true
        Common_Normal_Standby2Nomal_Callbcak: can-be-invoked-concurrently=true
        svCS_GetTankResistanceValue_Operation
        svCS_SWCNormal_ReceiveSafetyGearCRCCallback
        svCS_SWCNormal_ReceiveSafetyTTCRCCallback
        Odo_Api_ParamentGetCsPortGetData: can-be-invoked-concurrently=true
        Fuel_Api_ParamentGetCsPort_Operation
        TC_Api_ParamentGetCsPort_1_Operation: can-be-invoked-concurrently=true
        NvMNotifyJobFinished_NvBlockNeed_Menu_JobFinished
        CsmJob_Aes128_Decrypt_Cbk_Callback_CallbackNotification
        CsmJob_Aes128_Encrypt_Cbk_Callback_CallbackNotification
        SWCNormal_SensorAorB_Status_Operation
        TC_EnergyInfo
        TC_EnergyInfoResp
        svCS_SWCNormal_ReceiveAdasStatus_Callback
        svCS_SWCNormal_ReceiveHMIPowerMode_Callback
        ppCS_SWCNormal_ReceiveMenuTheme_Callback
        ppCS_SWCNormal_OdoTimeSync_CallBack
        ppCS_TtToChime
        svCS_SWCNormal_ReceiveOffroadInfo_Callback
      8 x swc service dependency:
        NvBlockNeed_Block_ODO_1
          assigned-datas:
            role=ramBlock, used-data-element=NvBlockNeed_Block_ODO_1_MirrorBlock
            role=defaultValue, used-parameter-element=NvBlockNeed_Block_ODO_1_DefaultValue
            role=defaultValue, used-parameter-element=NvBlockNeed_Block_ODO_1_DefaultValue
            role=defaultValue, used-parameter-element=NvBlockNeed_Block_ODO_1_DefaultValue
            role=defaultValue, used-parameter-element=NvBlockNeed_Block_ODO_1_DefaultValue
            role=defaultValue, used-parameter-element=NvBlockNeed_Block_ODO_1_DefaultValue
            role=defaultValue, used-parameter-element=NvBlockNeed_Block_ODO_1_DefaultValue
            role=defaultValue, used-parameter-element=NvBlockNeed_Block_ODO_1_DefaultValue
            role=defaultValue, used-parameter-element=NvBlockNeed_Block_ODO_1_DefaultValue
            role=defaultValue, used-parameter-element=NvBlockNeed_Block_ODO_1_DefaultValue
            role=defaultValue, used-parameter-element=NvBlockNeed_Block_ODO_1_DefaultValue
            role=defaultValue, used-parameter-element=NvBlockNeed_Block_ODO_1_DefaultValue
            role=defaultValue, used-parameter-element=NvBlockNeed_Block_ODO_1_DefaultValue
          assigned-ports:
            port-prototype=NvMService_AC3_SRBS_Defs_NvBlockNeed_Block_ODO_1, role=NvMService_AC3_SRBS_Defs
            port-prototype=NvMNotifyJobFinished_NvBlockNeed_Block_ODO_1, role=NvMNotifyJobFinished
          service-needs:
            nv block needs NvBlockNeed_Block_ODO_1: n-data-sets=0, ram-block-status-control=API, reliability=NO-PROTECTION, restore-at-start=true, store-at-shutdown=true
        NvBlockNeed_Block_ODO_2
          assigned-datas:
            role=ramBlock, used-data-element=NvBlockNeed_Block_ODO_2_MirrorBlock
            role=defaultValue, used-parameter-element=NvBlockNeed_Block_ODO_2_DefaultValue
            role=defaultValue, used-parameter-element=NvBlockNeed_Block_ODO_2_DefaultValue
            role=defaultValue, used-parameter-element=NvBlockNeed_Block_ODO_2_DefaultValue
            role=defaultValue, used-parameter-element=NvBlockNeed_Block_ODO_2_DefaultValue
            role=defaultValue, used-parameter-element=NvBlockNeed_Block_ODO_2_DefaultValue
            role=defaultValue, used-parameter-element=NvBlockNeed_Block_ODO_2_DefaultValue
            role=defaultValue, used-parameter-element=NvBlockNeed_Block_ODO_2_DefaultValue
            role=defaultValue, used-parameter-element=NvBlockNeed_Block_ODO_2_DefaultValue
            role=defaultValue, used-parameter-element=NvBlockNeed_Block_ODO_2_DefaultValue
            role=defaultValue, used-parameter-element=NvBlockNeed_Block_ODO_2_DefaultValue
            role=defaultValue, used-parameter-element=NvBlockNeed_Block_ODO_2_DefaultValue
            role=defaultValue, used-parameter-element=NvBlockNeed_Block_ODO_2_DefaultValue
          assigned-ports:
            port-prototype=NvMService_AC3_SRBS_Defs_NvBlockNeed_Block_ODO_2, role=NvMService_AC3_SRBS_Defs
            port-prototype=NvMNotifyJobFinished_NvBlockNeed_Block_ODO_2, role=NvMNotifyJobFinished
          service-needs:
            nv block needs NvBlockNeed_Block_ODO_2: n-data-sets=0, ram-block-status-control=API, reliability=NO-PROTECTION, restore-at-start=true, store-at-shutdown=true
        NvBlockNeed_Block_ODO_3
          assigned-datas:
            role=ramBlock, used-data-element=NvBlockNeed_Block_ODO_3_MirrorBlock
            role=defaultValue, used-parameter-element=NvBlockNeed_Block_ODO_3_DefaultValue
            role=defaultValue, used-parameter-element=NvBlockNeed_Block_ODO_3_DefaultValue
            role=defaultValue, used-parameter-element=NvBlockNeed_Block_ODO_3_DefaultValue
            role=defaultValue, used-parameter-element=NvBlockNeed_Block_ODO_3_DefaultValue
            role=defaultValue, used-parameter-element=NvBlockNeed_Block_ODO_3_DefaultValue
            role=defaultValue, used-parameter-element=NvBlockNeed_Block_ODO_3_DefaultValue
            role=defaultValue, used-parameter-element=NvBlockNeed_Block_ODO_3_DefaultValue
            role=defaultValue, used-parameter-element=NvBlockNeed_Block_ODO_3_DefaultValue
            role=defaultValue, used-parameter-element=NvBlockNeed_Block_ODO_3_DefaultValue
            role=defaultValue, used-parameter-element=NvBlockNeed_Block_ODO_3_DefaultValue
            role=defaultValue, used-parameter-element=NvBlockNeed_Block_ODO_3_DefaultValue
            role=defaultValue, used-parameter-element=NvBlockNeed_Block_ODO_3_DefaultValue
          assigned-ports:
            port-prototype=NvMService_AC3_SRBS_Defs_NvBlockNeed_Block_ODO_3, role=NvMService_AC3_SRBS_Defs
            port-prototype=NvMNotifyJobFinished_NvBlockNeed_Block_ODO_3, role=NvMNotifyJobFinished
          service-needs:
            nv block needs NvBlockNeed_Block_ODO_3: n-data-sets=0, ram-block-status-control=API, reliability=NO-PROTECTION, restore-at-start=true, store-at-shutdown=true
        NvBlockNeed_Block_ODO_4
          assigned-datas:
            role=ramBlock, used-data-element=NvBlockNeed_Block_ODO_4_MirrorBlock
            role=defaultValue, used-parameter-element=NvBlockNeed_Block_ODO_4_DefaultValue
            role=defaultValue, used-parameter-element=NvBlockNeed_Block_ODO_4_DefaultValue
            role=defaultValue, used-parameter-element=NvBlockNeed_Block_ODO_4_DefaultValue
            role=defaultValue, used-parameter-element=NvBlockNeed_Block_ODO_4_DefaultValue
            role=defaultValue, used-parameter-element=NvBlockNeed_Block_ODO_4_DefaultValue
            role=defaultValue, used-parameter-element=NvBlockNeed_Block_ODO_4_DefaultValue
            role=defaultValue, used-parameter-element=NvBlockNeed_Block_ODO_4_DefaultValue
            role=defaultValue, used-parameter-element=NvBlockNeed_Block_ODO_4_DefaultValue
            role=defaultValue, used-parameter-element=NvBlockNeed_Block_ODO_4_DefaultValue
            role=defaultValue, used-parameter-element=NvBlockNeed_Block_ODO_4_DefaultValue
            role=defaultValue, used-parameter-element=NvBlockNeed_Block_ODO_4_DefaultValue
            role=defaultValue, used-parameter-element=NvBlockNeed_Block_ODO_4_DefaultValue
          assigned-ports:
            port-prototype=NvMService_AC3_SRBS_Defs_NvBlockNeed_Block_ODO_4, role=NvMService_AC3_SRBS_Defs
            port-prototype=NvMNotifyJobFinished_NvBlockNeed_Block_ODO_4, role=NvMNotifyJobFinished
          service-needs:
            nv block needs NvBlockNeed_Block_ODO_4: n-data-sets=0, ram-block-status-control=API, reliability=NO-PROTECTION, restore-at-start=true, store-at-shutdown=true
        NvBlockNeed_Block_ODO_5
          assigned-datas:
            role=ramBlock, used-data-element=NvBlockNeed_Block_ODO_5_MirrorBlock
            role=defaultValue, used-parameter-element=NvBlockNeed_Block_ODO_5_DefaultValue
            role=defaultValue, used-parameter-element=NvBlockNeed_Block_ODO_5_DefaultValue
            role=defaultValue, used-parameter-element=NvBlockNeed_Block_ODO_5_DefaultValue
            role=defaultValue, used-parameter-element=NvBlockNeed_Block_ODO_5_DefaultValue
            role=defaultValue, used-parameter-element=NvBlockNeed_Block_ODO_5_DefaultValue
            role=defaultValue, used-parameter-element=NvBlockNeed_Block_ODO_5_DefaultValue
            role=defaultValue, used-parameter-element=NvBlockNeed_Block_ODO_5_DefaultValue
            role=defaultValue, used-parameter-element=NvBlockNeed_Block_ODO_5_DefaultValue
            role=defaultValue, used-parameter-element=NvBlockNeed_Block_ODO_5_DefaultValue
            role=defaultValue, used-parameter-element=NvBlockNeed_Block_ODO_5_DefaultValue
            role=defaultValue, used-parameter-element=NvBlockNeed_Block_ODO_5_DefaultValue
            role=defaultValue, used-parameter-element=NvBlockNeed_Block_ODO_5_DefaultValue
          assigned-ports:
            port-prototype=NvMService_AC3_SRBS_Defs_NvBlockNeed_Block_ODO_5, role=NvMService_AC3_SRBS_Defs
            port-prototype=NvMNotifyJobFinished_NvBlockNeed_Block_ODO_5, role=NvMNotifyJobFinished
          service-needs:
            nv block needs NvBlockNeed_Block_ODO_5: n-data-sets=0, ram-block-status-control=API, reliability=NO-PROTECTION, restore-at-start=true, store-at-shutdown=true
        NvBlockNeed_Block_MaintainOdo
          assigned-datas:
            role=ramBlock, used-data-element=NvBlockNeed_Block_MaintainOdo_MirrorBlock
            role=defaultValue, used-parameter-element=NvBlockNeed_Block_MaintainOdo_DefaultValue
            role=defaultValue, used-parameter-element=NvBlockNeed_Block_MaintainOdo_DefaultValue
            role=defaultValue, used-parameter-element=NvBlockNeed_Block_MaintainOdo_DefaultValue
            role=defaultValue, used-parameter-element=NvBlockNeed_Block_MaintainOdo_DefaultValue
            role=defaultValue, used-parameter-element=NvBlockNeed_Block_MaintainOdo_DefaultValue
            role=defaultValue, used-parameter-element=NvBlockNeed_Block_MaintainOdo_DefaultValue
            role=defaultValue, used-parameter-element=NvBlockNeed_Block_MaintainOdo_DefaultValue
            role=defaultValue, used-parameter-element=NvBlockNeed_Block_MaintainOdo_DefaultValue
            role=defaultValue, used-parameter-element=NvBlockNeed_Block_MaintainOdo_DefaultValue
            role=defaultValue, used-parameter-element=NvBlockNeed_Block_MaintainOdo_DefaultValue
            role=defaultValue, used-parameter-element=NvBlockNeed_Block_MaintainOdo_DefaultValue
            role=defaultValue, used-parameter-element=NvBlockNeed_Block_MaintainOdo_DefaultValue
          assigned-ports:
            port-prototype=NvMService_AC3_SRBS_Defs_NvBlockNeed_Block_MaintainOdo, role=NvMService_AC3_SRBS_Defs
            port-prototype=NvMNotifyJobFinished_NvBlockNeed_Block_MaintainOdo, role=NvMNotifyJobFinished
          service-needs:
            nv block needs NvBlockNeed_Block_MaintainOdo: n-data-sets=0, ram-block-status-control=API, reliability=NO-PROTECTION, restore-at-start=true, store-at-shutdown=true
        NvBlockNeed_Block_Trip
          assigned-datas:
            role=ramBlock, used-data-element=NvBlockNeed_Block_Trip_MirrorBlock
            role=defaultValue, used-parameter-element=NvBlockNeed_Block_Trip_DefaultValue
            role=defaultValue, used-parameter-element=NvBlockNeed_Block_Trip_DefaultValue
            role=defaultValue, used-parameter-element=NvBlockNeed_Block_Trip_DefaultValue
            role=defaultValue, used-parameter-element=NvBlockNeed_Block_Trip_DefaultValue
            role=defaultValue, used-parameter-element=NvBlockNeed_Block_Trip_DefaultValue
            role=defaultValue, used-parameter-element=NvBlockNeed_Block_Trip_DefaultValue
            role=defaultValue, used-parameter-element=NvBlockNeed_Block_Trip_DefaultValue
            role=defaultValue, used-parameter-element=NvBlockNeed_Block_Trip_DefaultValue
            role=defaultValue, used-parameter-element=NvBlockNeed_Block_Trip_DefaultValue
            role=defaultValue, used-parameter-element=NvBlockNeed_Block_Trip_DefaultValue
            role=defaultValue, used-parameter-element=NvBlockNeed_Block_Trip_DefaultValue
            role=defaultValue, used-parameter-element=NvBlockNeed_Block_Trip_DefaultValue
          assigned-ports:
            port-prototype=NvMNotifyJobFinished_NvBlockNeed_Block_Trip, role=NvMNotifyJobFinished
            port-prototype=NvMService_AC3_SRBS_Defs_NvBlockNeed_Block_Trip, role=NvMService_AC3_SRBS_Defs
          service-needs:
            nv block needs NvBlockNeed_Block_Trip: n-data-sets=0, ram-block-status-control=API, reliability=NO-PROTECTION, restore-at-start=true, store-at-shutdown=true
        NvBlockNeed_Menu
          assigned-datas:
            role=ramBlock, used-data-element=NvBlockNeed_Menu_MirrorBlock
            role=defaultValue, used-parameter-element=NvBlockNeed_MENU_Data_DefaultValue
          assigned-ports:
            port-prototype=NvMService_AC3_SRBS_NvBlockNeed_Menu, role=NvMService_AC3_SRBS
            port-prototype=NvMNotifyJobFinished_NvBlockNeed_Menu, role=NvMNotifyJobFinished
          service-needs:
            nv block needs NvBlockNeed_Menu: n-data-sets=0, reliability=NO-PROTECTION, restore-at-start=false, store-at-shutdown=false
      shared-parameters:
        10 x parameter data prototype, all with sw-calibration-access=READ-WRITE:
          NvBlockNeed_Block_ODO_{1..5}_DefaultValue: type=A_ODO_data_u8_16, init-value=[6, 0, 255, 128, 0, 0, 0, 0, 0, 0, 0, 0, 0, 0, 0, 0]
          NvBlockNeed_Block_MaintainOdo_DefaultValue: type=NVMBlockMaintain_Type, init-value=constant-reference=NVMBlockMaintainODO
          NvBlockNeed_Block_Trip_DefaultValue: type=NVMBlockTrip, init-value=constant-reference=NVMBlockTripInit
          NvBlockNeed_Block_TC_Config_Data_DefaultValue: type=NVMBlockTCConfig_Type, init-value=constant-reference=NVMBlockTCConfigInit
          NvBlockNeed_Block_TC_Data_DefaultValue: type=NVMBlockTC_Type, init-value=constant-reference=NVMBlockTCInit
          NvBlockNeed_MENU_Data_DefaultValue: type=NVMMenuData_A20, init-value=constant-reference=NVMBlockMenuInit
